VERSION "BO_HSCAN"

NS_ :

BS_:

BU_: BCM_Gp CCF_Server DDM DRDM DSM FTCM FTCMB GWM LPDM PDM PRDM PSM RFA RGTM RGTMB RLSM RPDM RRSM TBM TSTR VIM Virtual_Node WDCM Vector_XXX

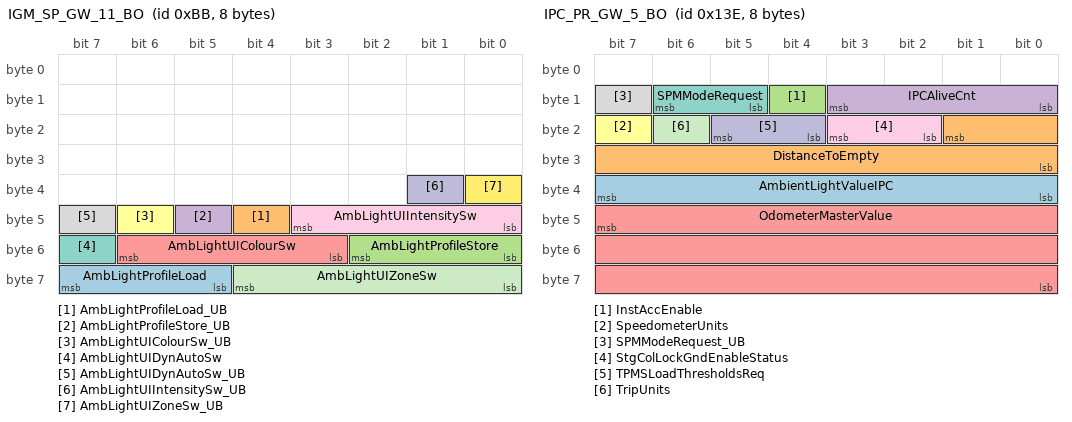
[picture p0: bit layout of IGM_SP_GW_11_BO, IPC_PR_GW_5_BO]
BO_ 187 IGM_SP_GW_11_BO: 8 GWM
 SG_ AmbLightProfileLoad : 63|3@0+ (1,0) [0|7] ""  BCM_Gp
 SG_ AmbLightProfileLoad_UB : 44|1@0+ (1,0) [0|1] ""  BCM_Gp
 SG_ AmbLightProfileStore : 50|3@0+ (1,0) [0|7] ""  BCM_Gp
 SG_ AmbLightProfileStore_UB : 45|1@0+ (1,0) [0|1] ""  BCM_Gp
 SG_ AmbLightUIColourSw : 54|4@0+ (1,0) [0|15] ""  BCM_Gp
 SG_ AmbLightUIColourSw_UB : 46|1@0+ (1,0) [0|1] ""  BCM_Gp
 SG_ AmbLightUIDynAutoSw : 55|1@0+ (1,0) [0|1] ""  BCM_Gp
 SG_ AmbLightUIDynAutoSw_UB : 47|1@0+ (1,0) [0|1] ""  BCM_Gp
 SG_ AmbLightUIIntensitySw : 43|4@0+ (1,0) [0|15] "Brightness level"  BCM_Gp
 SG_ AmbLightUIIntensitySw_UB : 33|1@0+ (1,0) [0|1] ""  BCM_Gp
 SG_ AmbLightUIZoneSw : 60|5@0+ (1,0) [0|31] ""  BCM_Gp
 SG_ AmbLightUIZoneSw_UB : 32|1@0+ (1,0) [0|1] ""  BCM_Gp

BO_ 177 IGM_SP_GW_1_BO: 8 GWM
 SG_ ActivateTimer : 47|1@0+ (1,0) [0|1] ""  BCM_Gp
 SG_ ActivateTimer_UB : 56|1@0+ (1,0) [0|1] ""  BCM_Gp
 SG_ AutoBlindEnableReq : 38|1@0+ (1,0) [0|1] ""  BCM_Gp
 SG_ AutoBlindEnableReq_UB : 63|1@0+ (1,0) [0|1] ""  BCM_Gp
 SG_ DIAnimationEnableReq : 35|1@0+ (1,0) [0|1] ""  BCM_Gp
 SG_ DIAnimationEnableReq_UB : 41|1@0+ (1,0) [0|1] ""  BCM_Gp
 SG_ EEEStateRequest : 24|1@0+ (1,0) [0|1] ""  BCM_Gp
 SG_ EEEStateRequest_UB : 62|1@0+ (1,0) [0|1] ""  BCM_Gp
 SG_ EnableDippedMirror : 27|1@0+ (1,0) [0|1] ""  BCM_Gp
 SG_ EnableDippedMirror_UB : 61|1@0+ (1,0) [0|1] ""  BCM_Gp
 SG_ GestureBlindEnableSw : 37|1@0+ (1,0) [0|1] ""  BCM_Gp
 SG_ GestureBlindEnableSw_UB : 48|1@0+ (1,0) [0|1] ""  BCM_Gp
 SG_ RearCameraWashReq : 36|1@0+ (1,0) [0|1] ""  BCM_Gp
 SG_ RearCameraWashReq_UB : 49|1@0+ (1,0) [0|1] ""  BCM_Gp
 SG_ SideStepsModeReq : 26|2@0+ (1,0) [0|3] ""  TBM
 SG_ SideStepsModeReq_UB : 50|1@0+ (1,0) [0|1] ""  TBM
 SG_ SinglePointEntryReq : 44|1@0+ (1,0) [0|1] ""  BCM_Gp
 SG_ SinglePointEntryReq_UB : 60|1@0+ (1,0) [0|1] ""  BCM_Gp
 SG_ StealthModeUISwitch : 46|2@0+ (1,0) [0|3] ""  BCM_Gp
 SG_ StealthModeUISwitch_UB : 51|1@0+ (1,0) [0|1] ""  BCM_Gp
 SG_ TowBarFunctionReq : 33|2@0+ (1,0) [0|3] ""  TBM
 SG_ TowBarFunctionReq_UB : 52|1@0+ (1,0) [0|1] ""  TBM
 SG_ TowBarMeasureLoad : 34|1@0+ (1,0) [0|1] ""  TBM
 SG_ TowBarMeasureLoad_UB : 53|1@0+ (1,0) [0|1] ""  TBM
 SG_ TrailerLightTestReq : 30|1@0+ (1,0) [0|1] ""  BCM_Gp
 SG_ TrailerLightTestReq_UB : 54|1@0+ (1,0) [0|1] ""  BCM_Gp
 SG_ ValetReq : 29|1@0+ (1,0) [0|1] ""  BCM_Gp
 SG_ ValetReq_UB : 55|1@0+ (1,0) [0|1] ""  BCM_Gp
 SG_ WakeShutDownEnableReq : 28|1@0+ (1,0) [0|1] ""  BCM_Gp
 SG_ WakeShutDownEnableReq_UB : 40|1@0+ (1,0) [0|1] ""  BCM_Gp
 SG_ WalkAwayLockReq : 17|2@0+ (1,0) [0|3] ""  Vector_XXX
 SG_ WalkAwayLockReq_UB : 31|1@0+ (1,0) [0|1] ""  Vector_XXX
 SG_ WindowsGlobalCloseReq : 43|1@0+ (1,0) [0|1] ""  BCM_Gp
 SG_ WindowsGlobalCloseReq_UB : 59|1@0+ (1,0) [0|1] ""  BCM_Gp
 SG_ WindowsGlobalOpenReq : 42|1@0+ (1,0) [0|1] ""  BCM_Gp
 SG_ WindowsGlobalOpenReq_UB : 58|1@0+ (1,0) [0|1] ""  BCM_Gp
 SG_ WiperWinterParkReq : 39|1@0+ (1,0) [0|1] ""  BCM_Gp
 SG_ WiperWinterParkReq_UB : 57|1@0+ (1,0) [0|1] ""  BCM_Gp

BO_ 108 IgnitionAuthDataControl_BO: 8 BCM_Gp
 SG_ IgnitionAuthDataControl : 7|64@0+ (1,0) [0|1.84467440737096E+019] ""  GWM

BO_ 110 IgnitionAuthDataTarget_BO: 8 GWM
 SG_ IgnitionAuthDataTarget : 7|64@0+ (1,0) [0|1.84467440737096E+019] ""  BCM_Gp

BO_ 318 IPC_PR_GW_5_BO: 8 GWM
 SG_ AmbientLightValueIPC : 39|8@0+ (1,0) [0|253] "Counts"  BCM_Gp
 SG_ DistanceToEmpty : 17|10@0+ (1,0) [0|1022] "Range in km"  Vector_XXX
 SG_ InstAccEnable : 12|1@0+ (1,0) [0|1] ""  Vector_XXX
 SG_ IPCAliveCnt : 11|4@0+ (1,0) [0|15] "Counter"  Vector_XXX
 SG_ OdometerMasterValue : 47|24@0+ (1,0) [0|16777215] ""  BCM_Gp,FTCM
 SG_ SpeedometerUnits : 23|1@0+ (1,0) [0|1] ""  Vector_XXX
 SG_ SPMModeRequest : 14|2@0+ (1,0) [0|3] ""  Vector_XXX
 SG_ SPMModeRequest_UB : 15|1@0+ (1,0) [0|1] ""  Vector_XXX
 SG_ StgColLockGndEnableStatus : 19|2@0+ (1,0) [0|3] ""  BCM_Gp
 SG_ TPMSLoadThresholdsReq : 21|2@0+ (1,0) [0|3] ""  Vector_XXX
 SG_ TripUnits : 22|1@0+ (1,0) [0|1] ""  Vector_XXX

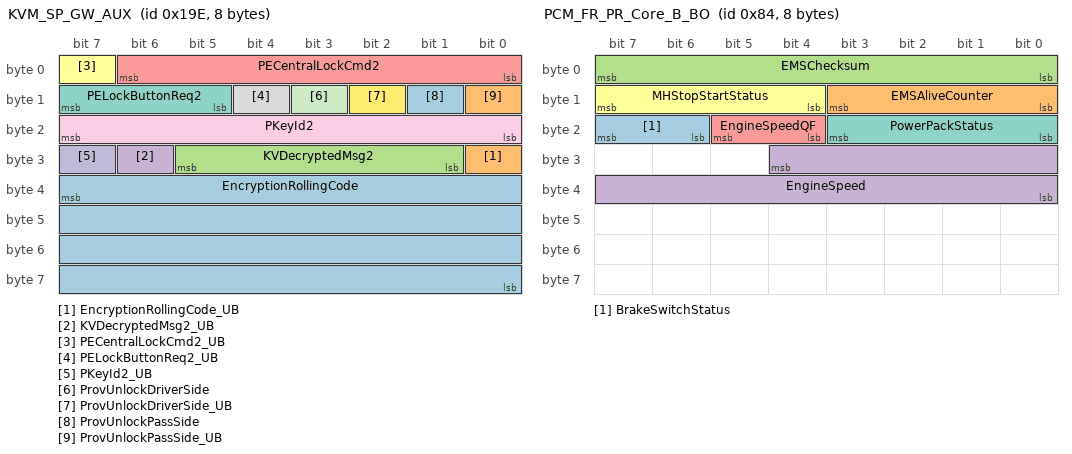
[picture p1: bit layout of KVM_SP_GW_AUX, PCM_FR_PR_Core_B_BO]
BO_ 414 KVM_SP_GW_AUX: 8 RFA
 SG_ EncryptionRollingCode : 39|32@0+ (1,0) [0|4294967295] ""  BCM_Gp,GWM
 SG_ EncryptionRollingCode_UB : 24|1@0+ (1,0) [0|1] ""  BCM_Gp,GWM
 SG_ KVDecryptedMsg2 : 29|5@0+ (1,0) [8|12] "Not Used"  BCM_Gp,GWM
 SG_ KVDecryptedMsg2_UB : 30|1@0+ (1,0) [0|1] ""  BCM_Gp,GWM
 SG_ PECentralLockCmd2 : 6|7@0+ (1,0) [0|127] "See description for encoding"  BCM_Gp,GWM,RGTM,RGTMB
 SG_ PECentralLockCmd2_UB : 7|1@0+ (1,0) [0|1] ""  BCM_Gp,GWM,RGTM,RGTMB
 SG_ PELockButtonReq2 : 15|3@0+ (1,0) [5|6] "Undefined (Unused)"  BCM_Gp,GWM
 SG_ PELockButtonReq2_UB : 12|1@0+ (1,0) [0|1] ""  BCM_Gp,GWM
 SG_ PKeyId2 : 23|8@0+ (1,0) [0|255] "See description for encoding"  BCM_Gp,GWM
 SG_ PKeyId2_UB : 31|1@0+ (1,0) [0|1] ""  BCM_Gp,GWM
 SG_ ProvUnlockDriverSide : 11|1@0+ (1,0) [0|1] ""  BCM_Gp,GWM
 SG_ ProvUnlockDriverSide_UB : 10|1@0+ (1,0) [0|1] ""  BCM_Gp,GWM
 SG_ ProvUnlockPassSide : 9|1@0+ (1,0) [0|1] ""  BCM_Gp,GWM
 SG_ ProvUnlockPassSide_UB : 8|1@0+ (1,0) [0|1] ""  BCM_Gp,GWM

BO_ 1386 LPDM_NM56A: 8 LPDM
 SG_ NMMessageLPDM : 7|64@0+ (1,0) [0|1.84467440737096E+019] ""  Virtual_Node

BO_ 944 LPDM_PR_GW_1: 8 LPDM
 SG_ LeftPowerDoorStatus : 59|4@0+ (1,0) [0|15] ""  GWM

BO_ 124 PATSDataControl_BO: 8 BCM_Gp
 SG_ PATSDataControl : 7|64@0+ (1,0) [0|1.84467440737096E+019] ""  GWM

BO_ 126 PATSDataTarget_BO: 8 GWM
 SG_ PATSDataTarget : 7|64@0+ (1,0) [0|1.84467440737096E+019] ""  BCM_Gp

BO_ 132 PCM_FR_PR_Core_B_BO: 8 GWM
 SG_ BrakeSwitchStatus : 23|2@0+ (1,0) [0|3] ""  BCM_Gp
 SG_ EMSAliveCounter : 11|4@0+ (1,0) [0|15] "Counter"  Vector_XXX
 SG_ EMSChecksum : 7|8@0+ (1,0) [0|255] "Counter"  Vector_XXX
 SG_ EngineSpeed : 28|13@0+ (1,0) [0|8191] "RPM"  BCM_Gp
 SG_ EngineSpeedQF : 21|2@0+ (1,0) [0|3] ""  Vector_XXX
 SG_ MHStopStartStatus : 15|4@0+ (1,0) [0|15] ""  FTCM
 SG_ PowerPackStatus : 19|4@0+ (1,0) [0|15] ""  BCM_Gp,FTCM

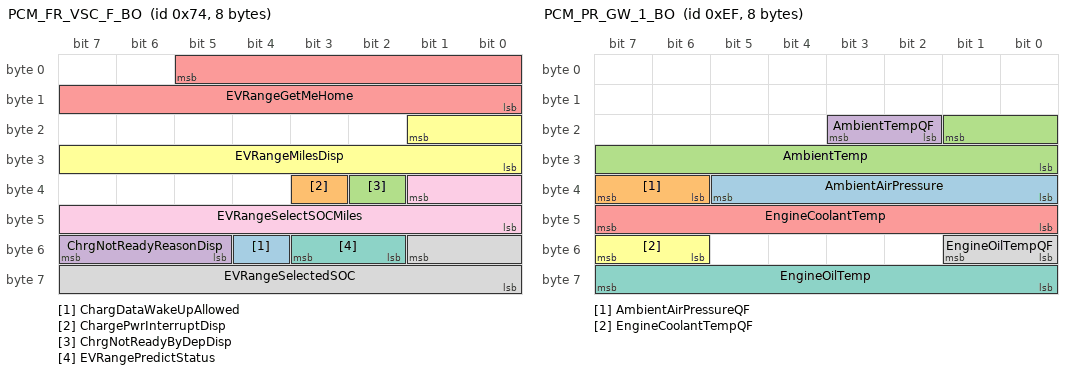
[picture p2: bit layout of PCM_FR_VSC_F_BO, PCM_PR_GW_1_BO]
BO_ 116 PCM_FR_VSC_F_BO: 8 GWM
 SG_ ChargDataWakeUpAllowed : 52|1@0+ (1,0) [0|1] ""  Vector_XXX
 SG_ ChargePwrInterruptDisp : 35|1@0+ (1,0) [0|1] ""  Vector_XXX
 SG_ ChrgNotReadyByDepDisp : 34|1@0+ (1,0) [0|1] ""  Vector_XXX
 SG_ ChrgNotReadyReasonDisp : 55|3@0+ (1,0) [0|7] ""  Vector_XXX
 SG_ EVRangeGetMeHome : 5|14@0+ (0.1,0) [0|1638.3] "km"  WDCM
 SG_ EVRangeMilesDisp : 17|10@0+ (1,0) [0|1023] "Miles"  Vector_XXX
 SG_ EVRangePredictStatus : 51|2@0+ (1,0) [0|3] ""  Vector_XXX
 SG_ EVRangeSelectedSOC : 49|10@0+ (1,0) [0|1023] "km"  Vector_XXX
 SG_ EVRangeSelectSOCMiles : 33|10@0+ (1,0) [0|1023] "Miles"  Vector_XXX

BO_ 239 PCM_PR_GW_1_BO: 8 GWM
 SG_ AmbientAirPressure : 37|6@0+ (10,500) [500|1100] "mBAR"  BCM_Gp,DSM,PSM,RLSM,RRSM
 SG_ AmbientAirPressureQF : 39|2@0+ (1,0) [0|3] ""  BCM_Gp
 SG_ AmbientTemp : 17|10@0+ (0.25,-128) [-128|127.75] "Degrees C"  BCM_Gp,DDM,DRDM,FTCM,PDM,PRDM,RGTM,RGTMB
 SG_ AmbientTempQF : 19|2@0+ (1,0) [0|3] ""  BCM_Gp,DDM,DRDM,FTCM,PDM,PRDM,RGTM,RGTMB
 SG_ EngineCoolantTemp : 47|8@0+ (1,-60) [-60|195] "deg C"  Vector_XXX
 SG_ EngineCoolantTempQF : 55|2@0+ (1,0) [0|3] ""  Vector_XXX
 SG_ EngineOilTemp : 63|8@0+ (1,-60) [-60|195] "deg C"  Vector_XXX
 SG_ EngineOilTempQF : 49|2@0+ (1,0) [0|3] ""  Vector_XXX

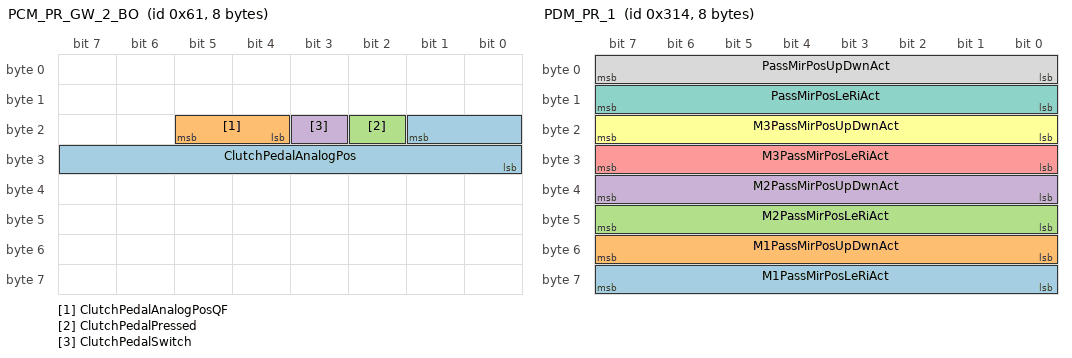
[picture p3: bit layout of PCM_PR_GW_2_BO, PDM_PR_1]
BO_ 97 PCM_PR_GW_2_BO: 8 GWM
 SG_ ClutchPedalAnalogPos : 17|10@0+ (0.0977517,0) [0|99.9999891] "%, range: 0-100%"  BCM_Gp
 SG_ ClutchPedalAnalogPosQF : 21|2@0+ (1,0) [0|3] ""  Vector_XXX
 SG_ ClutchPedalPressed : 18|1@0+ (1,0) [0|1] ""  BCM_Gp
 SG_ ClutchPedalSwitch : 19|1@0+ (1,0) [0|1] ""  Vector_XXX

BO_ 788 PDM_PR_1: 8 PDM
 SG_ M1PassMirPosLeRiAct : 63|8@0+ (1,0) [0|255] "Mirror Position"  Virtual_Node
 SG_ M1PassMirPosUpDwnAct : 55|8@0+ (1,0) [0|255] "Mirror Position"  Virtual_Node
 SG_ M2PassMirPosLeRiAct : 47|8@0+ (1,0) [0|255] "Mirror Position"  Virtual_Node
 SG_ M2PassMirPosUpDwnAct : 39|8@0+ (1,0) [0|255] "Mirror Position"  Virtual_Node
 SG_ M3PassMirPosLeRiAct : 31|8@0+ (1,0) [0|255] "Mirror Position"  Virtual_Node
 SG_ M3PassMirPosUpDwnAct : 23|8@0+ (1,0) [0|255] "Mirror Position"  Virtual_Node
 SG_ PassMirPosLeRiAct : 15|8@0+ (1,0) [0|255] "Mirror Position"  Virtual_Node
 SG_ PassMirPosUpDwnAct : 7|8@0+ (1,0) [0|255] "Mirror Position"  Virtual_Node

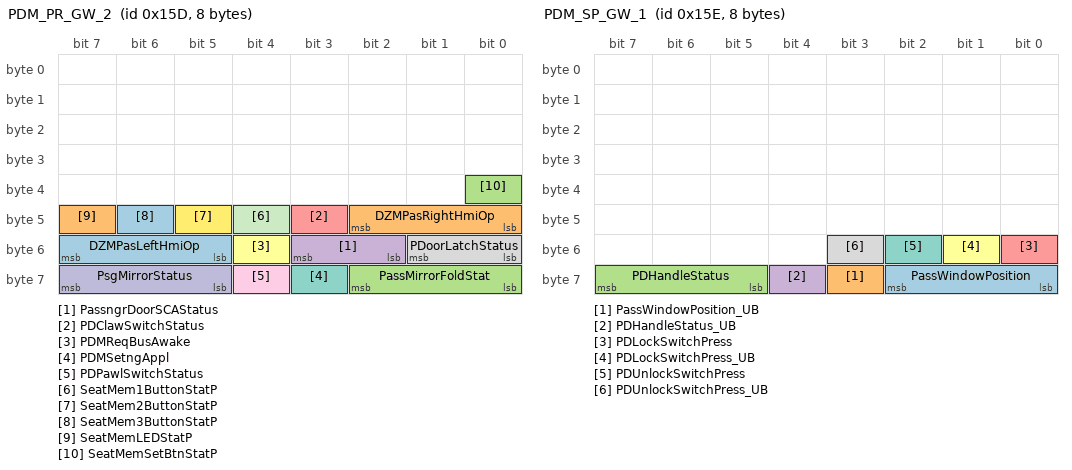
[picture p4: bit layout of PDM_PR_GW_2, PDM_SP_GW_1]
BO_ 349 PDM_PR_GW_2: 8 PDM
 SG_ DZMPasLeftHmiOp : 55|3@0+ (1,0) [5|7] "Not Used"  GWM
 SG_ DZMPasRightHmiOp : 42|3@0+ (1,0) [5|7] "Not Used"  GWM
 SG_ PassMirrorFoldStat : 58|3@0+ (1,0) [0|7] ""  DDM
 SG_ PassngrDoorSCAStatus : 51|2@0+ (1,0) [0|3] ""  DDM
 SG_ PDClawSwitchStatus : 43|1@0+ (1,0) [0|1] ""  DDM
 SG_ PDMReqBusAwake : 52|1@0+ (1,0) [0|1] ""  GWM
 SG_ PDMSetngAppl : 59|1@0+ (1,0) [0|1] ""  Virtual_Node
 SG_ PDoorLatchStatus : 49|2@0+ (1,0) [0|3] "See Description"  BCM_Gp,LPDM,RPDM,TBM
 SG_ PDPawlSwitchStatus : 60|1@0+ (1,0) [0|1] ""  DDM
 SG_ PsgMirrorStatus : 63|3@0+ (1,0) [0|7] ""  GWM
 SG_ SeatMem1ButtonStatP : 44|1@0+ (1,0) [0|1] ""  PSM
 SG_ SeatMem2ButtonStatP : 45|1@0+ (1,0) [0|1] ""  PSM
 SG_ SeatMem3ButtonStatP : 46|1@0+ (1,0) [0|1] ""  PSM
 SG_ SeatMemLEDStatP : 47|1@0+ (1,0) [0|1] ""  PSM
 SG_ SeatMemSetBtnStatP : 32|1@0+ (1,0) [0|1] ""  PSM

BO_ 350 PDM_SP_GW_1: 8 PDM
 SG_ PassWindowPosition : 58|3@0+ (1,0) [6|7] "Undefined (Unused)"  BCM_Gp,FTCM,GWM,LPDM,RPDM
 SG_ PassWindowPosition_UB : 59|1@0+ (1,0) [0|1] ""  BCM_Gp,FTCM,GWM,LPDM,RPDM
 SG_ PDHandleStatus : 63|3@0+ (1,0) [0|7] ""  GWM,RFA
 SG_ PDHandleStatus_UB : 60|1@0+ (1,0) [0|1] ""  GWM,RFA
 SG_ PDLockSwitchPress : 48|1@0+ (1,0) [0|1] ""  BCM_Gp,GWM
 SG_ PDLockSwitchPress_UB : 49|1@0+ (1,0) [0|1] ""  BCM_Gp,GWM
 SG_ PDUnlockSwitchPress : 50|1@0+ (1,0) [0|1] ""  BCM_Gp,GWM
 SG_ PDUnlockSwitchPress_UB : 51|1@0+ (1,0) [0|1] ""  BCM_Gp,GWM

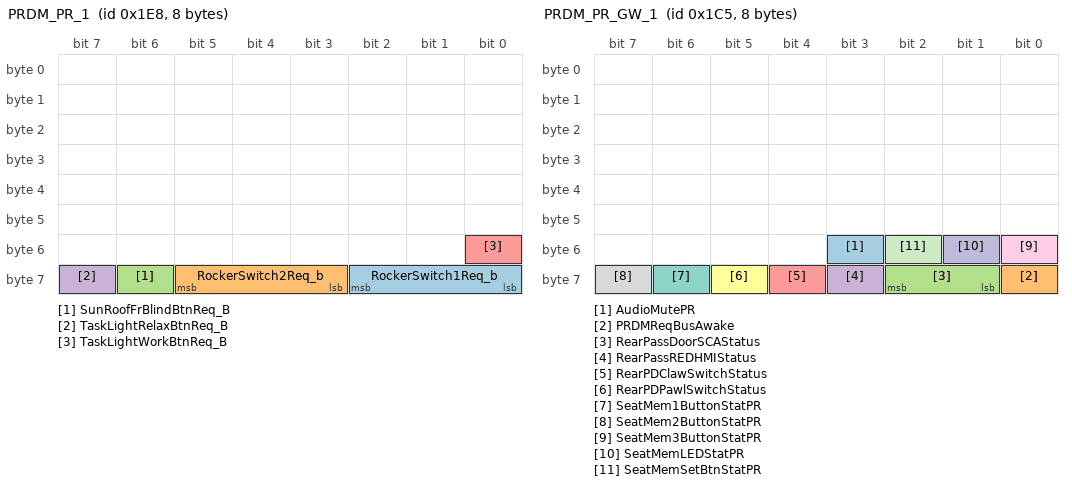
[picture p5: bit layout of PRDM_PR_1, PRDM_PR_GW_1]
BO_ 488 PRDM_PR_1: 8 PRDM
 SG_ RockerSwitch1Req_b : 58|3@0+ (1,0) [5|7] "Not used"  DRDM
 SG_ RockerSwitch2Req_b : 61|3@0+ (1,0) [5|7] "Not used"  DRDM
 SG_ SunRoofFrBlindBtnReq_B : 62|1@0+ (1,0) [0|1] ""  BCM_Gp
 SG_ TaskLightRelaxBtnReq_B : 63|1@0+ (1,0) [0|1] ""  BCM_Gp
 SG_ TaskLightWorkBtnReq_B : 48|1@0+ (1,0) [0|1] ""  BCM_Gp

BO_ 453 PRDM_PR_GW_1: 8 PRDM
 SG_ AudioMutePR : 51|1@0+ (1,0) [0|1] ""  GWM
 SG_ PRDMReqBusAwake : 56|1@0+ (1,0) [0|1] ""  GWM
 SG_ RearPassDoorSCAStatus : 58|2@0+ (1,0) [0|3] ""  DRDM
 SG_ RearPassREDHMIStatus : 59|1@0+ (1,0) [0|1] ""  GWM
 SG_ RearPDClawSwitchStatus : 60|1@0+ (1,0) [0|1] ""  DRDM
 SG_ RearPDPawlSwitchStatus : 61|1@0+ (1,0) [0|1] ""  DRDM
 SG_ SeatMem1ButtonStatPR : 62|1@0+ (1,0) [0|1] ""  PSM
 SG_ SeatMem2ButtonStatPR : 63|1@0+ (1,0) [0|1] ""  PSM
 SG_ SeatMem3ButtonStatPR : 48|1@0+ (1,0) [0|1] ""  PSM
 SG_ SeatMemLEDStatPR : 49|1@0+ (1,0) [0|1] ""  PSM
 SG_ SeatMemSetBtnStatPR : 50|1@0+ (1,0) [0|1] ""  PSM

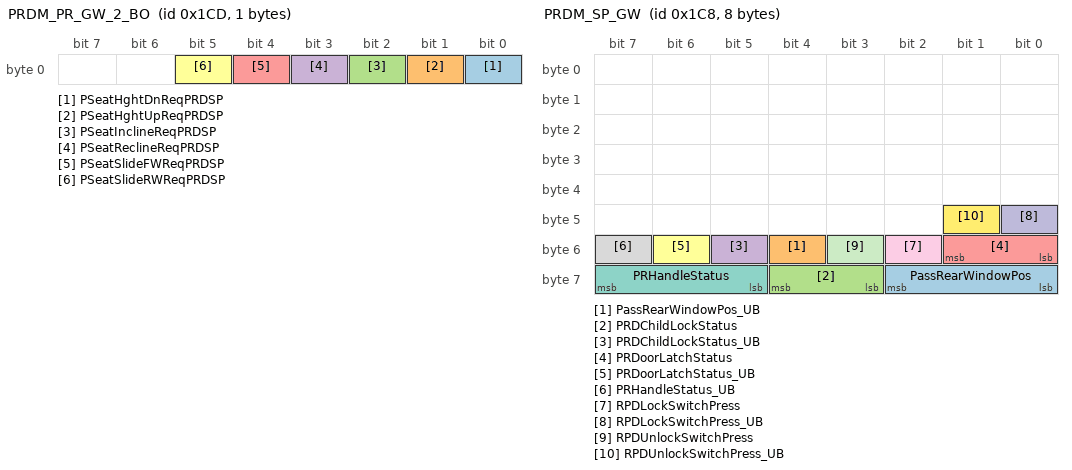
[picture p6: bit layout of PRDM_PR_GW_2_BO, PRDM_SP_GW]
BO_ 461 PRDM_PR_GW_2_BO: 1 PRDM
 SG_ PSeatHghtDnReqPRDSP : 0|1@0+ (1,0) [0|1] ""  PSM
 SG_ PSeatHghtUpReqPRDSP : 1|1@0+ (1,0) [0|1] ""  PSM
 SG_ PSeatInclineReqPRDSP : 2|1@0+ (1,0) [0|1] ""  PSM
 SG_ PSeatReclineReqPRDSP : 3|1@0+ (1,0) [0|1] ""  PSM
 SG_ PSeatSlideFWReqPRDSP : 4|1@0+ (1,0) [0|1] ""  PSM
 SG_ PSeatSlideRWReqPRDSP : 5|1@0+ (1,0) [0|1] ""  PSM

BO_ 456 PRDM_SP_GW: 8 PRDM
 SG_ PassRearWindowPos : 58|3@0+ (1,0) [6|7] "Undefined (Unused)"  BCM_Gp,FTCM,GWM
 SG_ PassRearWindowPos_UB : 52|1@0+ (1,0) [0|1] ""  BCM_Gp,FTCM,GWM
 SG_ PRDChildLockStatus : 60|2@0+ (1,0) [0|3] ""  DDM,GWM
 SG_ PRDChildLockStatus_UB : 53|1@0+ (1,0) [0|1] ""  DDM,GWM
 SG_ PRDoorLatchStatus : 49|2@0+ (1,0) [0|3] "See Description"  BCM_Gp,GWM
 SG_ PRDoorLatchStatus_UB : 54|1@0+ (1,0) [0|1] ""  BCM_Gp,GWM
 SG_ PRHandleStatus : 63|3@0+ (1,0) [0|7] ""  GWM,RFA
 SG_ PRHandleStatus_UB : 55|1@0+ (1,0) [0|1] ""  GWM,RFA
 SG_ RPDLockSwitchPress : 50|1@0+ (1,0) [0|1] ""  BCM_Gp,GWM
 SG_ RPDLockSwitchPress_UB : 40|1@0+ (1,0) [0|1] ""  BCM_Gp,GWM
 SG_ RPDUnlockSwitchPress : 51|1@0+ (1,0) [0|1] ""  BCM_Gp,GWM
 SG_ RPDUnlockSwitchPress_UB : 41|1@0+ (1,0) [0|1] ""  BCM_Gp,GWM

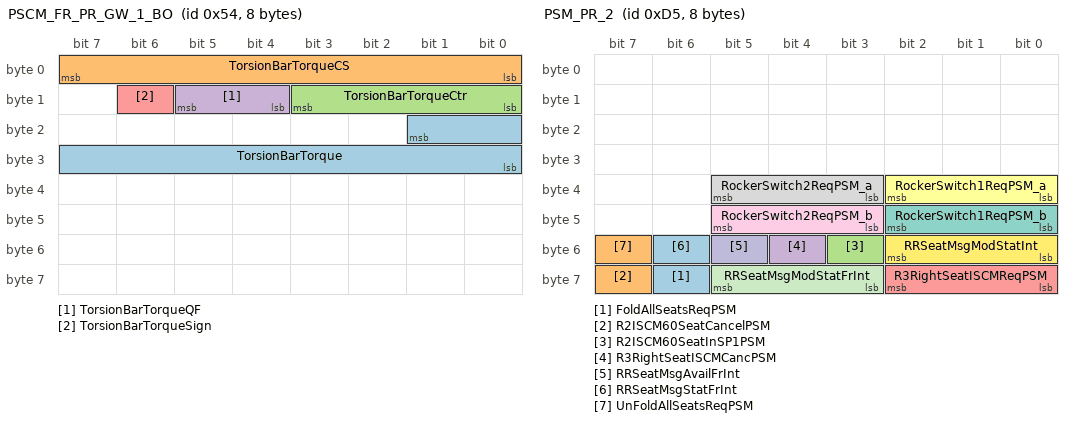
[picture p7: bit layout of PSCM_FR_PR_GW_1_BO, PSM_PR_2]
BO_ 84 PSCM_FR_PR_GW_1_BO: 8 GWM
 SG_ TorsionBarTorque : 17|10@0+ (0.02,0) [0|20.44] "0-3FCh :0..+20.40 Nm, E=N*0.02+0"  Vector_XXX
 SG_ TorsionBarTorqueCS : 7|8@0+ (1,0) [0|255] "checksum"  Vector_XXX
 SG_ TorsionBarTorqueCtr : 11|4@0+ (1,0) [0|15] "Counter value"  Vector_XXX
 SG_ TorsionBarTorqueQF : 13|2@0+ (1,0) [0|3] ""  Vector_XXX
 SG_ TorsionBarTorqueSign : 14|1@0+ (1,0) [0|1] ""  BCM_Gp

BO_ 211 PSM_BO_PR_GW_1: 8 PSM
 SG_ PasSeatInhib1stRow : 26|1@0+ (1,0) [0|1] ""  GWM
 SG_ PasSeatInhib2ndRow : 27|1@0+ (1,0) [0|1] ""  GWM
 SG_ PasSeatInhib3rdRow : 28|1@0+ (1,0) [0|1] ""  GWM
 SG_ PasSeatPosition1stRow : 59|4@0+ (1,0) [5|15] "Reserved"  GWM
 SG_ PasSeatPosition2ndRow : 63|4@0+ (1,0) [5|15] "Reserved"  GWM
 SG_ PasSeatPosition3rdRow : 51|4@0+ (1,0) [5|15] "Reserved"  GWM
 SG_ PassengerCancelSeat : 29|1@0+ (1,0) [0|1] ""  GWM,RLSM,RRSM
 SG_ PassengerSeatMovement : 30|1@0+ (1,0) [0|1] ""  GWM,RLSM,RRSM
 SG_ PassSeatFootRestStat : 31|1@0+ (1,0) [0|1] ""  GWM,RLSM,RRSM
 SG_ PassSeatMemLoadStat : 34|3@0+ (1,0) [0|7] ""  GWM,RLSM,RRSM
 SG_ PassSeatMemStorStat : 37|3@0+ (1,0) [0|7] ""  GWM,RLSM,RRSM
 SG_ PassSeatMovement2ndRow : 39|2@0+ (1,0) [0|3] ""  GWM
 SG_ PassSeatMovement3rdRow : 25|2@0+ (1,0) [0|3] ""  GWM
 SG_ PassSeatMovementStat : 55|4@0+ (1,0) [0|15] ""  GWM,RLSM,RRSM
 SG_ PassSeatMoveSelStat : 16|1@0+ (1,0) [0|1] ""  GWM
 SG_ PassSeatMovmnt2ndRow : 43|4@0+ (1,0) [5|15] "Reserved"  DSM,GWM
 SG_ PassSeatMovmnt3rdRow : 47|4@0+ (1,0) [5|15] "Reserved"  DSM,GWM
 SG_ PassSeatOccupantStatus : 22|1@0+ (1,0) [0|1] ""  GWM,RLSM,RRSM
 SG_ PassSeatPSAStat : 17|1@0+ (1,0) [0|1] ""  GWM,RLSM,RRSM
 SG_ Row1PassMovementINH : 18|1@0+ (1,0) [0|1] ""  GWM
 SG_ Row2PassMovementINH : 19|1@0+ (1,0) [0|1] ""  GWM
 SG_ Row3PassMovementINH : 20|1@0+ (1,0) [0|1] ""  GWM
 SG_ RPSeatMovement : 21|1@0+ (1,0) [0|1] ""  GWM

BO_ 1368 PSM_NM558: 8 PSM
 SG_ NMmessagePSM : 7|64@0+ (1,0) [0|1.84467440737096E+019] ""  Virtual_Node

BO_ 213 PSM_PR_2: 8 PSM
 SG_ FoldAllSeatsReqPSM : 62|1@0+ (1,0) [0|1] ""  DSM
 SG_ R2ISCM60SeatCancelPSM : 63|1@0+ (1,0) [0|1] ""  DSM
 SG_ R2ISCM60SeatInSP1PSM : 51|1@0+ (1,0) [0|1] ""  DSM
 SG_ R3RightSeatISCMCancPSM : 52|1@0+ (1,0) [0|1] ""  DSM
 SG_ R3RightSeatISCMReqPSM : 58|3@0+ (1,0) [0|7] ""  DSM
 SG_ RockerSwitch1ReqPSM_a : 34|3@0+ (1,0) [5|7] "Not used"  DSM
 SG_ RockerSwitch1ReqPSM_b : 42|3@0+ (1,0) [5|7] "Not used"  DSM
 SG_ RockerSwitch2ReqPSM_a : 37|3@0+ (1,0) [5|7] "Not used"  DSM
 SG_ RockerSwitch2ReqPSM_b : 45|3@0+ (1,0) [5|7] "Not used"  DSM
 SG_ RRSeatMsgAvailFrInt : 53|1@0+ (1,0) [0|1] ""  DSM
 SG_ RRSeatMsgModStatFrInt : 61|3@0+ (1,0) [5|7] "Unused"  DSM
 SG_ RRSeatMsgModStatInt : 50|3@0+ (1,0) [5|7] "Unused"  DSM
 SG_ RRSeatMsgStatFrInt : 54|1@0+ (1,0) [0|1] ""  DSM
 SG_ UnFoldAllSeatsReqPSM : 55|1@0+ (1,0) [0|1] ""  DSM

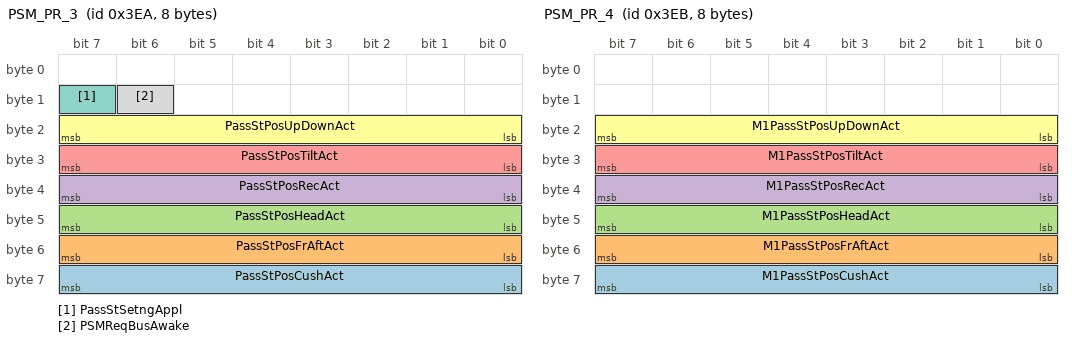
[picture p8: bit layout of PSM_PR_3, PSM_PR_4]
BO_ 1002 PSM_PR_3: 8 PSM
 SG_ PassStPosCushAct : 63|8@0+ (0.5,0) [0|100] "%"  Virtual_Node
 SG_ PassStPosFrAftAct : 55|8@0+ (0.5,0) [0|100] "%"  Virtual_Node
 SG_ PassStPosHeadAct : 47|8@0+ (0.5,0) [0|100] "%"  Virtual_Node
 SG_ PassStPosRecAct : 39|8@0+ (0.5,0) [0|100] "%"  Virtual_Node
 SG_ PassStPosTiltAct : 31|8@0+ (0.5,0) [0|100] "%"  Virtual_Node
 SG_ PassStPosUpDownAct : 23|8@0+ (0.5,0) [0|100] "%"  Virtual_Node
 SG_ PassStSetngAppl : 15|1@0+ (1,0) [0|1] ""  Virtual_Node
 SG_ PSMReqBusAwake : 14|1@0+ (1,0) [0|1] ""  GWM

BO_ 1003 PSM_PR_4: 8 PSM
 SG_ M1PassStPosCushAct : 63|8@0+ (0.5,0) [0|100] "%"  Virtual_Node
 SG_ M1PassStPosFrAftAct : 55|8@0+ (0.5,0) [0|100] "%"  Virtual_Node
 SG_ M1PassStPosHeadAct : 47|8@0+ (0.5,0) [0|100] "%"  Virtual_Node
 SG_ M1PassStPosRecAct : 39|8@0+ (0.5,0) [0|100] "%"  Virtual_Node
 SG_ M1PassStPosTiltAct : 31|8@0+ (0.5,0) [0|100] "%"  Virtual_Node
 SG_ M1PassStPosUpDownAct : 23|8@0+ (0.5,0) [0|100] "%"  Virtual_Node

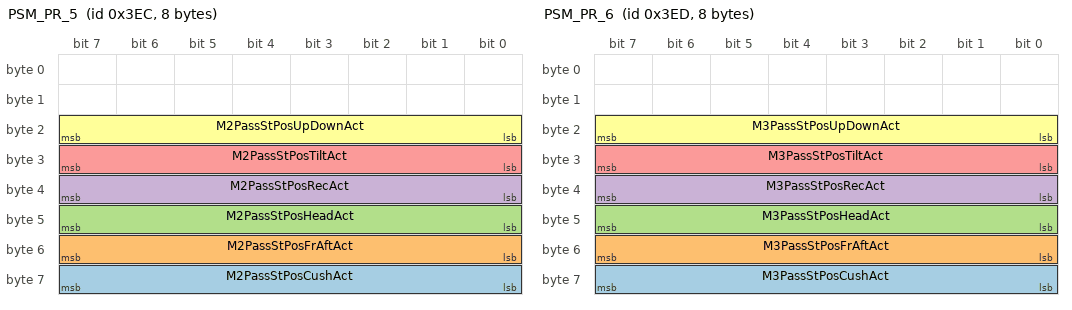
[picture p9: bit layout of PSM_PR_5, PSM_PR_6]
BO_ 1004 PSM_PR_5: 8 PSM
 SG_ M2PassStPosCushAct : 63|8@0+ (0.5,0) [0|100] "%"  Virtual_Node
 SG_ M2PassStPosFrAftAct : 55|8@0+ (0.5,0) [0|100] "%"  Virtual_Node
 SG_ M2PassStPosHeadAct : 47|8@0+ (0.5,0) [0|100] "%"  Virtual_Node
 SG_ M2PassStPosRecAct : 39|8@0+ (0.5,0) [0|100] "%"  Virtual_Node
 SG_ M2PassStPosTiltAct : 31|8@0+ (0.5,0) [0|100] "%"  Virtual_Node
 SG_ M2PassStPosUpDownAct : 23|8@0+ (0.5,0) [0|100] "%"  Virtual_Node

BO_ 1005 PSM_PR_6: 8 PSM
 SG_ M3PassStPosCushAct : 63|8@0+ (0.5,0) [0|100] "%"  Virtual_Node
 SG_ M3PassStPosFrAftAct : 55|8@0+ (0.5,0) [0|100] "%"  Virtual_Node
 SG_ M3PassStPosHeadAct : 47|8@0+ (0.5,0) [0|100] "%"  Virtual_Node
 SG_ M3PassStPosRecAct : 39|8@0+ (0.5,0) [0|100] "%"  Virtual_Node
 SG_ M3PassStPosTiltAct : 31|8@0+ (0.5,0) [0|100] "%"  Virtual_Node
 SG_ M3PassStPosUpDownAct : 23|8@0+ (0.5,0) [0|100] "%"  Virtual_Node

BO_ 191 RCM_FR_PR_GW_1_BO: 8 GWM
 SG_ CrashAirbagStatus : 63|2@0+ (1,0) [0|3] ""  Vector_XXX
 SG_ CrashOccClassStatus : 61|2@0+ (1,0) [0|3] ""  Vector_XXX
 SG_ CrashPACOSSwitchState : 59|2@0+ (1,0) [0|3] ""  Vector_XXX
 SG_ CrashPretensionerStat : 57|2@0+ (1,0) [0|3] ""  Vector_XXX
 SG_ CrashSeatBeltBcklState : 55|2@0+ (1,0) [0|3] ""  Vector_XXX
 SG_ CrashSeverityClass : 53|2@0+ (1,0) [0|3] ""  Vector_XXX
 SG_ CrashSideAirbagStatus : 51|2@0+ (1,0) [0|3] ""  Vector_XXX
 SG_ CrashStatusPIE : 42|1@0+ (1,0) [0|1] ""  BCM_Gp
 SG_ CrashStatusRCM : 43|1@0+ (1,0) [0|1] ""  BCM_Gp,DDM,DRDM,PDM,PRDM
 SG_ CrashTypeFront : 49|1@0+ (1,0) [0|1] ""  Vector_XXX
 SG_ CrashTypeRear : 48|1@0+ (1,0) [0|1] ""  Vector_XXX
 SG_ CrashTypeRoll : 40|1@0+ (1,0) [0|1] ""  Vector_XXX
 SG_ CrashTypeSide : 41|1@0+ (1,0) [0|1] ""  Vector_XXX
 SG_ DrivSeatBeltBcklError : 30|1@0+ (1,0) [0|1] ""  BCM_Gp,LPDM,RPDM
 SG_ DrivSeatBeltBcklState : 31|1@0+ (1,0) [0|1] ""  BCM_Gp,DSM,LPDM,RPDM
 SG_ DrivSeatPositionError : 47|1@0+ (1,0) [0|1] ""  Vector_XXX
 SG_ DrivSeatPositionStatus : 46|1@0+ (1,0) [0|1] ""  LPDM,RPDM
 SG_ KeepNetInAfterRunRCM : 44|1@0+ (1,0) [0|1] ""  Vector_XXX
 SG_ PassSeatBeltBcklError : 28|1@0+ (1,0) [0|1] ""  LPDM,RPDM
 SG_ PassSeatBeltBcklState : 29|1@0+ (1,0) [0|1] ""  LPDM,PSM,RPDM
 SG_ PassSeatPositionStatus : 45|1@0+ (1,0) [0|1] ""  LPDM,RPDM
 SG_ VerticalAcceleration : 27|12@0+ (0.02,-40.96) [-40.96|40.92] "m/s/s"  Vector_XXX

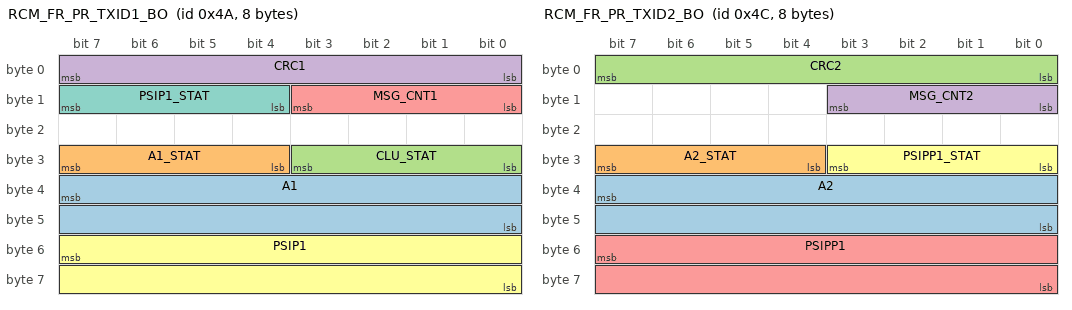
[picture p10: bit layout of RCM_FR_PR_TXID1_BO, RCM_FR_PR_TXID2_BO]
BO_ 74 RCM_FR_PR_TXID1_BO: 8 GWM
 SG_ A1 : 39|16@0+ (0.00125,-40.96) [-40.96|40.9575] "m/s2"  LPDM,RPDM
 SG_ A1_STAT : 31|4@0+ (1,0) [0|15] ""  Vector_XXX
 SG_ CLU_STAT : 27|4@0+ (1,0) [0|15] ""  Vector_XXX
 SG_ CRC1 : 7|8@0+ (1,0) [0|255] "checksum"  Vector_XXX
 SG_ MSG_CNT1 : 11|4@0+ (1,0) [0|15] "Counter value"  Vector_XXX
 SG_ PSIP1 : 55|16@0+ (0.005,-163.84) [-163.84|163.83] "Grad/s"  BCM_Gp
 SG_ PSIP1_STAT : 15|4@0+ (1,0) [0|15] ""  BCM_Gp

BO_ 76 RCM_FR_PR_TXID2_BO: 8 GWM
 SG_ A2 : 39|16@0+ (0.00125,-40.96) [-40.96|40.9575] "m/s2"  LPDM,RPDM,TBM
 SG_ A2_STAT : 31|4@0+ (1,0) [0|15] ""  Vector_XXX
 SG_ CRC2 : 7|8@0+ (1,0) [0|255] "checksum"  Vector_XXX
 SG_ MSG_CNT2 : 11|4@0+ (1,0) [0|15] "Counter value"  Vector_XXX
 SG_ PSIPP1 : 55|16@0+ (0.125,-4096) [-4096|4095.75] "Grad/s/s"  Vector_XXX
 SG_ PSIPP1_STAT : 27|4@0+ (1,0) [0|15] ""  Vector_XXX

BO_ 1288 RFA_NM508LS: 8 RFA
 SG_ NMmessageKVM : 7|64@0+ (1,0) [0|1.84467440737096E+019] ""  Virtual_Node

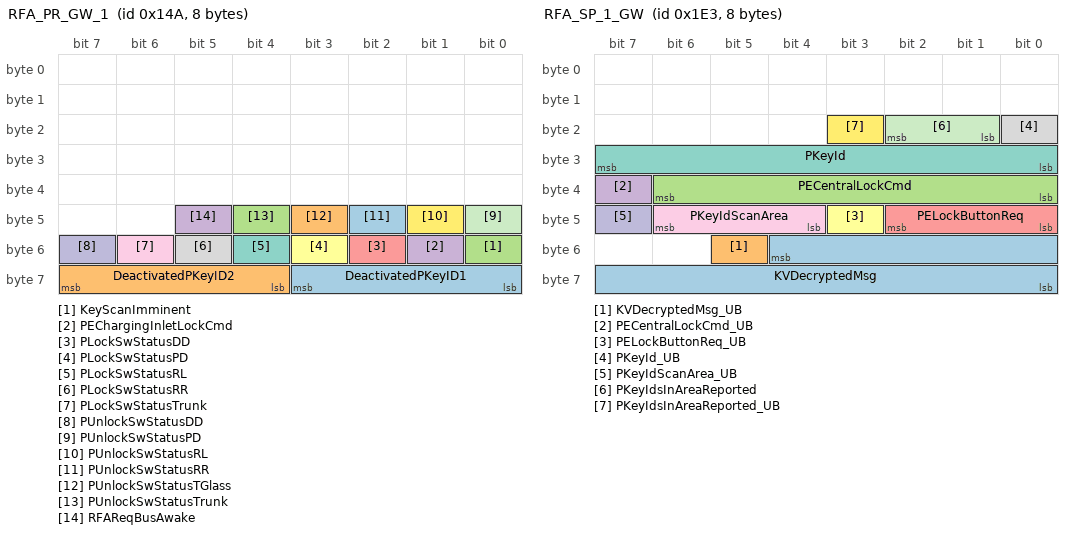
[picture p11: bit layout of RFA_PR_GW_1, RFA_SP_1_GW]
BO_ 330 RFA_PR_GW_1: 8 RFA
 SG_ DeactivatedPKeyID1 : 59|4@0+ (1,0) [0|15] "No Units"  BCM_Gp
 SG_ DeactivatedPKeyID2 : 63|4@0+ (1,0) [0|15] "No Units"  BCM_Gp
 SG_ KeyScanImminent : 48|1@0+ (1,0) [0|1] ""  WDCM
 SG_ PEChargingInletLockCmd : 49|1@0+ (1,0) [0|1] ""  GWM
 SG_ PLockSwStatusDD : 50|1@0+ (1,0) [0|1] ""  BCM_Gp
 SG_ PLockSwStatusPD : 51|1@0+ (1,0) [0|1] ""  BCM_Gp
 SG_ PLockSwStatusRL : 52|1@0+ (1,0) [0|1] ""  BCM_Gp
 SG_ PLockSwStatusRR : 53|1@0+ (1,0) [0|1] ""  BCM_Gp
 SG_ PLockSwStatusTrunk : 54|1@0+ (1,0) [0|1] ""  BCM_Gp
 SG_ PUnlockSwStatusDD : 55|1@0+ (1,0) [0|1] ""  BCM_Gp,DDM,DRDM,PDM,PRDM
 SG_ PUnlockSwStatusPD : 40|1@0+ (1,0) [0|1] ""  BCM_Gp,DDM,DRDM,PDM,PRDM
 SG_ PUnlockSwStatusRL : 41|1@0+ (1,0) [0|1] ""  BCM_Gp,DDM,DRDM,PDM,PRDM
 SG_ PUnlockSwStatusRR : 42|1@0+ (1,0) [0|1] ""  BCM_Gp,DDM,DRDM,PDM,PRDM
 SG_ PUnlockSwStatusTGlass : 43|1@0+ (1,0) [0|1] ""  BCM_Gp
 SG_ PUnlockSwStatusTrunk : 44|1@0+ (1,0) [0|1] ""  BCM_Gp
 SG_ RFAReqBusAwake : 45|1@0+ (1,0) [0|1] ""  GWM

BO_ 483 RFA_SP_1_GW: 8 RFA
 SG_ KVDecryptedMsg : 52|13@0+ (1,0) [0|8191] ""  BCM_Gp,GWM
 SG_ KVDecryptedMsg_UB : 53|1@0+ (1,0) [0|1] ""  BCM_Gp,GWM
 SG_ PECentralLockCmd : 38|7@0+ (1,0) [0|127] "See description for encoding"  BCM_Gp,GWM
 SG_ PECentralLockCmd_UB : 39|1@0+ (1,0) [0|1] ""  BCM_Gp,GWM
 SG_ PELockButtonReq : 42|3@0+ (1,0) [5|6] "Undefined (Unused)"  BCM_Gp,GWM
 SG_ PELockButtonReq_UB : 43|1@0+ (1,0) [0|1] ""  BCM_Gp,GWM
 SG_ PKeyId : 31|8@0+ (1,0) [0|255] "See description for encoding"  BCM_Gp,GWM
 SG_ PKeyId_UB : 16|1@0+ (1,0) [0|1] ""  BCM_Gp,GWM
 SG_ PKeyIdScanArea : 46|3@0+ (1,0) [0|7] ""  BCM_Gp,GWM
 SG_ PKeyIdScanArea_UB : 47|1@0+ (1,0) [0|1] ""  BCM_Gp,GWM
 SG_ PKeyIdsInAreaReported : 18|2@0+ (1,0) [0|3] ""  BCM_Gp,GWM
 SG_ PKeyIdsInAreaReported_UB : 19|1@0+ (1,0) [0|1] ""  BCM_Gp,GWM

BO_ 484 RFA_SP_GW_2: 8 RFA
 SG_ PEPullSwitchStatus : 27|3@0+ (1,0) [6|7] "Unused (Undefined)"  BCM_Gp,GWM
 SG_ PEPullSwitchStatus_UB : 28|1@0+ (1,0) [0|1] ""  BCM_Gp,GWM
 SG_ PKBattStatus : 29|1@0+ (1,0) [0|1] ""  BCM_Gp,GWM
 SG_ PKBattStatus_UB : 30|1@0+ (1,0) [0|1] ""  BCM_Gp,GWM
 SG_ PkeyScanComp : 31|1@0+ (1,0) [0|1] ""  GWM,Virtual_Node
 SG_ PkeyScanComp_UB : 16|1@0+ (1,0) [0|1] ""  GWM,Virtual_Node
 SG_ PKeyScanID : 63|8@0+ (1,0) [0|255] "See description for encoding"  GWM,Virtual_Node
 SG_ PKeyScanID_UB : 48|1@0+ (1,0) [0|1] ""  GWM,Virtual_Node
 SG_ PKeyWarningInd : 49|1@0+ (1,0) [0|1] ""  BCM_Gp,GWM
 SG_ PKeyWarningInd_UB : 50|1@0+ (1,0) [0|1] ""  BCM_Gp,GWM
 SG_ PLockRequestDD : 51|1@0+ (1,0) [0|1] ""  BCM_Gp,GWM
 SG_ PLockRequestDD_UB : 52|1@0+ (1,0) [0|1] ""  BCM_Gp,GWM
 SG_ PLockRequestPD : 53|1@0+ (1,0) [0|1] ""  BCM_Gp,GWM
 SG_ PLockRequestPD_UB : 54|1@0+ (1,0) [0|1] ""  BCM_Gp,GWM
 SG_ PLockRequestRL : 55|1@0+ (1,0) [0|1] ""  BCM_Gp,GWM
 SG_ PLockRequestRL_UB : 40|1@0+ (1,0) [0|1] ""  BCM_Gp,GWM
 SG_ PLockRequestRR : 41|1@0+ (1,0) [0|1] ""  BCM_Gp,GWM
 SG_ PLockRequestRR_UB : 42|1@0+ (1,0) [0|1] ""  BCM_Gp,GWM
 SG_ PLockRequestTrunk : 43|1@0+ (1,0) [0|1] ""  BCM_Gp,GWM
 SG_ PLockRequestTrunk_UB : 44|1@0+ (1,0) [0|1] ""  BCM_Gp,GWM
 SG_ PUnlockRequestDD : 45|1@0+ (1,0) [0|1] ""  BCM_Gp,GWM
 SG_ PUnlockRequestDD_UB : 46|1@0+ (1,0) [0|1] ""  BCM_Gp,GWM
 SG_ PUnlockRequestPD : 47|1@0+ (1,0) [0|1] ""  BCM_Gp,GWM
 SG_ PUnlockRequestPD_UB : 32|1@0+ (1,0) [0|1] ""  BCM_Gp,GWM
 SG_ PUnlockRequestRL : 33|1@0+ (1,0) [0|1] ""  BCM_Gp,GWM
 SG_ PUnlockRequestRL_UB : 34|1@0+ (1,0) [0|1] ""  BCM_Gp,GWM
 SG_ PUnlockRequestRR : 35|1@0+ (1,0) [0|1] ""  BCM_Gp,GWM
 SG_ PUnlockRequestRR_UB : 36|1@0+ (1,0) [0|1] ""  BCM_Gp,GWM
 SG_ PUnlockRequestTGlass : 37|1@0+ (1,0) [0|1] ""  BCM_Gp,GWM
 SG_ PUnlockRequestTGlass_UB : 38|1@0+ (1,0) [0|1] ""  BCM_Gp,GWM
 SG_ PUnlockRequestTrunk : 39|1@0+ (1,0) [0|1] ""  BCM_Gp,GWM
 SG_ PUnlockRequestTrunk_UB : 24|1@0+ (1,0) [0|1] ""  BCM_Gp,GWM

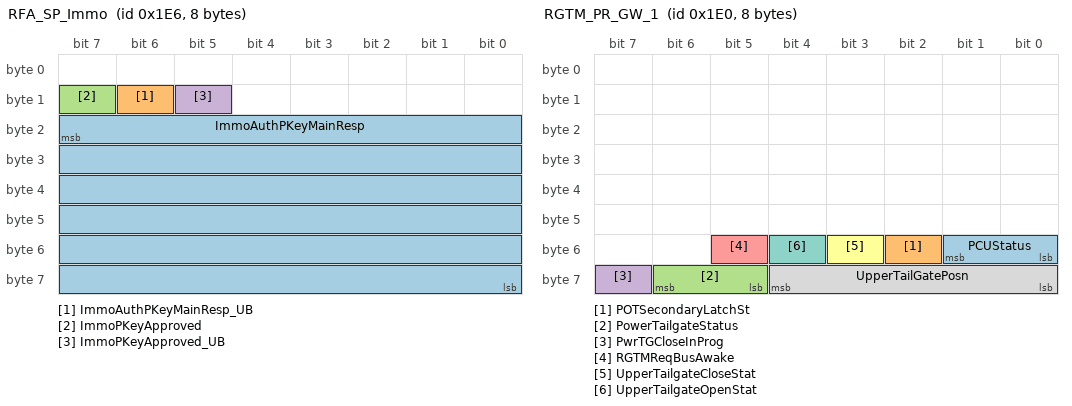
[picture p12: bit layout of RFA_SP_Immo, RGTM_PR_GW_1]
BO_ 486 RFA_SP_Immo: 8 RFA
 SG_ ImmoAuthPKeyMainResp : 23|48@0+ (1,0) [0|281474976710655] ""  BCM_Gp
 SG_ ImmoAuthPKeyMainResp_UB : 14|1@0+ (1,0) [0|1] ""  BCM_Gp
 SG_ ImmoPKeyApproved : 15|1@0+ (1,0) [0|1] ""  BCM_Gp
 SG_ ImmoPKeyApproved_UB : 13|1@0+ (1,0) [0|1] ""  BCM_Gp

BO_ 1318 RGTM_NM526: 8 RGTM
 SG_ NMmessageRGTM : 7|64@0+ (1,0) [0|1.84467440737096E+019] ""  Virtual_Node

BO_ 480 RGTM_PR_GW_1: 8 RGTM
 SG_ PCUStatus : 49|2@0+ (1,0) [0|3] ""  BCM_Gp,RGTMB
 SG_ POTSecondaryLatchSt : 50|1@0+ (1,0) [0|1] ""  RGTMB
 SG_ PowerTailgateStatus : 62|2@0+ (1,0) [0|3] ""  GWM,RGTMB
 SG_ PwrTGCloseInProg : 63|1@0+ (1,0) [0|1] ""  BCM_Gp
 SG_ RGTMReqBusAwake : 53|1@0+ (1,0) [0|1] ""  GWM
 SG_ UpperTailgateCloseStat : 51|1@0+ (1,0) [0|1] ""  RGTMB
 SG_ UpperTailgateOpenStat : 52|1@0+ (1,0) [0|1] ""  RGTMB
 SG_ UpperTailGatePosn : 60|5@0+ (1,0) [0|31] "Positional Data of Upper or lowe"  RGTMB

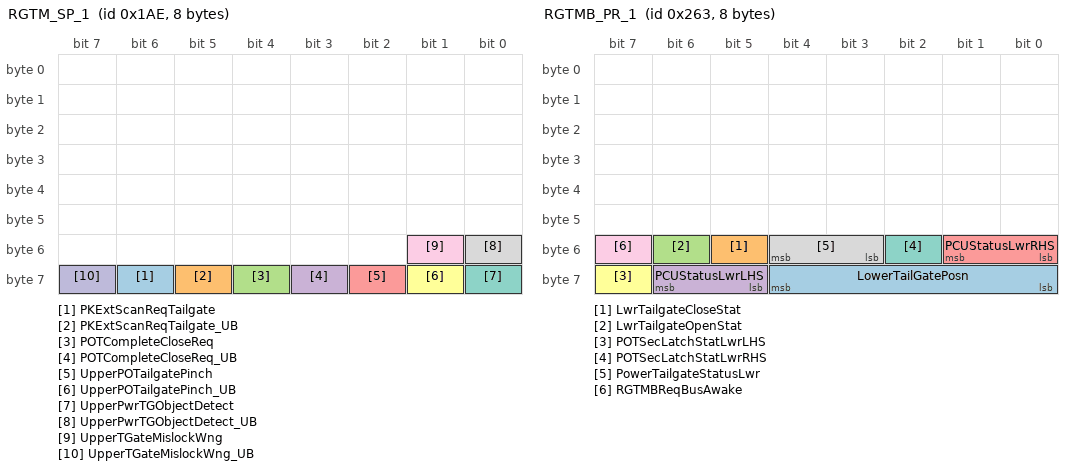
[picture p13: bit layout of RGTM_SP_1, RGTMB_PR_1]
BO_ 430 RGTM_SP_1: 8 RGTM
 SG_ PKExtScanReqTailgate : 62|1@0+ (1,0) [0|1] ""  RFA
 SG_ PKExtScanReqTailgate_UB : 61|1@0+ (1,0) [0|1] ""  RFA
 SG_ POTCompleteCloseReq : 60|1@0+ (1,0) [0|1] ""  RGTMB
 SG_ POTCompleteCloseReq_UB : 59|1@0+ (1,0) [0|1] ""  RGTMB
 SG_ UpperPOTailgatePinch : 58|1@0+ (1,0) [0|1] ""  RGTMB
 SG_ UpperPOTailgatePinch_UB : 57|1@0+ (1,0) [0|1] ""  RGTMB
 SG_ UpperPwrTGObjectDetect : 56|1@0+ (1,0) [0|1] ""  RGTMB
 SG_ UpperPwrTGObjectDetect_UB : 48|1@0+ (1,0) [0|1] ""  RGTMB
 SG_ UpperTGateMislockWng : 49|1@0+ (1,0) [0|1] ""  BCM_Gp
 SG_ UpperTGateMislockWng_UB : 63|1@0+ (1,0) [0|1] ""  BCM_Gp

BO_ 1402 RGTMB_NM57A: 8 RGTMB
 SG_ NMmessageRGTMB : 7|64@0+ (1,0) [0|1.84467440737096E+019] ""  Virtual_Node

BO_ 611 RGTMB_PR_1: 8 RGTMB
 SG_ LowerTailGatePosn : 60|5@0+ (1,0) [0|31] "Positional Data of Upper or lowe"  RGTM
 SG_ LwrTailgateCloseStat : 53|1@0+ (1,0) [0|1] ""  RGTM
 SG_ LwrTailgateOpenStat : 54|1@0+ (1,0) [0|1] ""  RGTM
 SG_ PCUStatusLwrLHS : 62|2@0+ (1,0) [0|3] ""  BCM_Gp,RGTM
 SG_ PCUStatusLwrRHS : 49|2@0+ (1,0) [0|3] ""  BCM_Gp,RGTM
 SG_ POTSecLatchStatLwrLHS : 63|1@0+ (1,0) [0|1] ""  RGTM
 SG_ POTSecLatchStatLwrRHS : 50|1@0+ (1,0) [0|1] ""  RGTM
 SG_ PowerTailgateStatusLwr : 52|2@0+ (1,0) [0|3] ""  RGTM
 SG_ RGTMBReqBusAwake : 55|1@0+ (1,0) [0|1] ""  GWM

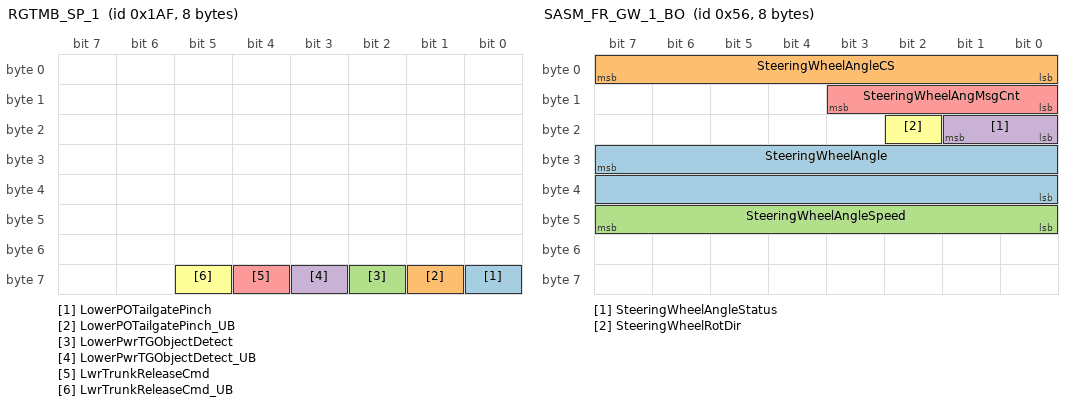
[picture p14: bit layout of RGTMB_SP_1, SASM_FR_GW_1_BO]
BO_ 431 RGTMB_SP_1: 8 RGTMB
 SG_ LowerPOTailgatePinch : 56|1@0+ (1,0) [0|1] ""  RGTM
 SG_ LowerPOTailgatePinch_UB : 57|1@0+ (1,0) [0|1] ""  RGTM
 SG_ LowerPwrTGObjectDetect : 58|1@0+ (1,0) [0|1] ""  RGTM
 SG_ LowerPwrTGObjectDetect_UB : 59|1@0+ (1,0) [0|1] ""  RGTM
 SG_ LwrTrunkReleaseCmd : 60|1@0+ (1,0) [0|1] ""  BCM_Gp,RGTM
 SG_ LwrTrunkReleaseCmd_UB : 61|1@0+ (1,0) [0|1] ""  BCM_Gp,RGTM

BO_ 1306 RLSM_NM51A: 8 RLSM
 SG_ NMmessageRLSM : 7|64@0+ (1,0) [0|1.84467440737096E+019] ""  Virtual_Node

BO_ 389 RLSM_PR_GW_1: 8 RLSM
 SG_ PassSeatHghtDownReqRL : 25|1@0+ (1,0) [0|1] ""  PSM
 SG_ PassSeatHghtUpReqRL : 24|1@0+ (1,0) [0|1] ""  PSM
 SG_ PassSeatHRestAftReqRL : 39|1@0+ (1,0) [0|1] ""  PSM
 SG_ PassSeatHRestDwnReqRL : 38|1@0+ (1,0) [0|1] ""  PSM
 SG_ PassSeatHRestForeReqRL : 37|1@0+ (1,0) [0|1] ""  PSM
 SG_ PassSeatHRestUpReqRL : 36|1@0+ (1,0) [0|1] ""  PSM
 SG_ PassSeatInclineReqRL : 55|1@0+ (1,0) [0|1] ""  PSM
 SG_ PassSeatMemClrReqRL : 35|2@0+ (1,0) [0|3] ""  PSM
 SG_ PassSeatMemClrReqRR : 33|2@0+ (1,0) [0|3] ""  PSM
 SG_ PassSeatMemLoadReqRL : 47|2@0+ (1,0) [0|3] ""  PSM
 SG_ PassSeatMemStrReqRL : 45|2@0+ (1,0) [0|3] ""  PSM
 SG_ PassSeatMoveReqRL : 43|4@0+ (1,0) [8|15] "Reserved"  PSM
 SG_ PassSeatReclineReqRL : 54|1@0+ (1,0) [0|1] ""  PSM
 SG_ PassSeatSlideAftReqRL : 53|1@0+ (1,0) [0|1] ""  PSM
 SG_ PassSeatSlideForeReqRL : 52|1@0+ (1,0) [0|1] ""  PSM
 SG_ PSARequestRL : 63|2@0+ (1,0) [0|3] ""  PSM
 SG_ RCntrSeatMoveSelStat : 61|1@0+ (1,0) [0|1] ""  GWM
 SG_ RCntrSeatMovmentStat : 51|4@0+ (1,0) [0|15] ""  DSM,GWM,PSM,RRSM
 SG_ RCntrSeatUpperLidStat : 60|1@0+ (1,0) [0|1] ""  RRSM
 SG_ RearLeftCancelSeat : 59|1@0+ (1,0) [0|1] ""  DSM,PSM
 SG_ RearSeatFoldFlatReqRL : 58|2@0+ (1,0) [0|3] ""  PSM
 SG_ RLSMSeatMovement : 26|1@0+ (1,0) [0|1] ""  PSM
 SG_ RMSeatInhib2ndRow : 56|1@0+ (1,0) [0|1] ""  GWM,RRSM

BO_ 390 RLSM_PR_GW_2: 8 RLSM
 SG_ RLeftTableDeployed : 56|1@0+ (1,0) [0|1] ""  DSM,GWM,PSM
 SG_ RLSeatCalfRestStat : 58|2@0+ (1,0) [0|3] ""  DSM,GWM,PSM
 SG_ RLSeatFoldFlatReq : 61|3@0+ (1,0) [0|7] ""  DSM,GWM,PSM
 SG_ RLSeatFootRestReq : 62|1@0+ (1,0) [0|1] ""  DSM,GWM,PSM
 SG_ RLSeatInhib2ndRow : 63|1@0+ (1,0) [0|1] ""  GWM
 SG_ RLSeatMasgIntStat : 50|3@0+ (1,0) [0|7] ""  GWM
 SG_ RLSeatMasgLocStat : 53|3@0+ (1,0) [0|7] ""  GWM
 SG_ RLSeatMasgModeStatFr : 34|3@0+ (1,0) [5|7] "Unused"  GWM
 SG_ RLSeatMasgProgStat : 44|3@0+ (1,0) [0|7] ""  GWM
 SG_ RLSeatMasgStatFr : 35|1@0+ (1,0) [0|1] ""  GWM
 SG_ RLSeatMassageModeStat : 47|3@0+ (1,0) [5|7] "unused"  GWM
 SG_ RLSeatMemLoadStat : 55|2@0+ (1,0) [0|3] ""  GWM
 SG_ RLSeatMemStorStat : 41|2@0+ (1,0) [0|3] ""  GWM
 SG_ RLSeatMovementStat : 39|4@0+ (1,0) [8|15] "Reserved"  DSM,GWM,PSM
 SG_ RLSeatMoveSelStat : 24|1@0+ (1,0) [0|1] ""  GWM
 SG_ RLSeatMsgAvailFr : 25|1@0+ (1,0) [0|1] ""  GWM
 SG_ RLSeatOccupancyStat : 26|1@0+ (1,0) [0|1] ""  GWM,PSM

BO_ 1327 RPDM_NM52F: 8 RPDM
 SG_ NMMessageRPDM : 7|64@0+ (1,0) [0|1.84467440737096E+019] ""  Virtual_Node

BO_ 530 RPDM_PR_GW_2: 8 RPDM
 SG_ RightPowerDoorStatus : 59|4@0+ (1,0) [0|15] ""  GWM

BO_ 1385 RRSM_NM569: 8 RRSM
 SG_ NMmessageRRSM : 7|64@0+ (1,0) [0|1.84467440737096E+019] ""  Virtual_Node

BO_ 682 RRSM_PR_GW_1: 8 RRSM
 SG_ CupHolderReq : 57|2@0+ (1,0) [0|3] ""  GWM,RLSM
 SG_ PassSeatHghtDownReqRR : 58|1@0+ (1,0) [0|1] ""  GWM,PSM
 SG_ PassSeatHghtUpReqRR : 59|1@0+ (1,0) [0|1] ""  GWM,PSM
 SG_ PassSeatHRestAftReqRR : 60|1@0+ (1,0) [0|1] ""  GWM,PSM
 SG_ PassSeatHRestDwnReqRR : 61|1@0+ (1,0) [0|1] ""  GWM,PSM
 SG_ PassSeatHRestForeReqRR : 62|1@0+ (1,0) [0|1] ""  GWM,PSM
 SG_ PassSeatHRestUpReqRR : 63|1@0+ (1,0) [0|1] ""  GWM,PSM
 SG_ PassSeatInclineReqRR : 48|1@0+ (1,0) [0|1] ""  GWM,PSM
 SG_ PassSeatMemLoadReqRR : 50|2@0+ (1,0) [0|3] ""  GWM,PSM
 SG_ PassSeatMemStrReqRR : 52|2@0+ (1,0) [0|3] ""  GWM,PSM
 SG_ PassSeatMoveReqRR : 43|4@0+ (1,0) [8|15] "Reserved"  GWM,PSM
 SG_ PassSeatReclineReqRR : 55|1@0+ (1,0) [0|1] ""  GWM,PSM
 SG_ PassSeatSlideAftReqRR : 45|1@0+ (1,0) [0|1] ""  GWM,PSM
 SG_ PassSeatSlideForeReqRR : 44|1@0+ (1,0) [0|1] ""  GWM,PSM
 SG_ PSARequestRR : 54|2@0+ (1,0) [0|3] ""  GWM,PSM
 SG_ RearLeftFoldSwStat : 46|1@0+ (1,0) [0|1] ""  GWM,RLSM
 SG_ RearLeftUnfoldSwStat : 47|1@0+ (1,0) [0|1] ""  GWM,RLSM
 SG_ RearRightCancelSeat : 32|1@0+ (1,0) [0|1] ""  DSM,GWM,PSM
 SG_ RearSeatFoldFlatReqRR : 34|2@0+ (1,0) [0|3] ""  GWM,PSM
 SG_ RRightTableDeployed : 35|1@0+ (1,0) [0|1] ""  DSM,GWM,PSM
 SG_ RRSeatCalfRestStat : 37|2@0+ (1,0) [0|3] ""  DSM,GWM,PSM
 SG_ RRSeatFoldFlatReq : 26|3@0+ (1,0) [0|7] ""  DSM,GWM,PSM
 SG_ RRSeatFootRestReq : 38|1@0+ (1,0) [0|1] ""  DSM,GWM,PSM
 SG_ RRSeatInhib2ndRow : 18|1@0+ (1,0) [0|1] ""  GWM
 SG_ RRSeatMasgAvailFr : 8|1@0+ (1,0) [0|1] ""  GWM
 SG_ RRSeatMasgIntStat : 4|3@0+ (1,0) [0|7] ""  GWM
 SG_ RRSeatMasgLocStat : 7|3@0+ (1,0) [0|7] ""  GWM
 SG_ RRSeatMasgModeStatFr : 12|3@0+ (1,0) [5|7] "Unused"  GWM
 SG_ RRSeatMasgProgStat : 15|3@0+ (1,0) [0|7] ""  GWM
 SG_ RRSeatMasgStatFr : 9|1@0+ (1,0) [0|1] ""  GWM
 SG_ RRSeatMemLoadStat : 20|2@0+ (1,0) [0|3] ""  GWM
 SG_ RRSeatMemStorStat : 22|2@0+ (1,0) [0|3] ""  GWM
 SG_ RRSeatMovementStat : 30|4@0+ (1,0) [8|15] "Reserved"  DSM,GWM,PSM
 SG_ RRSeatMoveSelStat : 23|1@0+ (1,0) [0|1] ""  GWM
 SG_ RRSeatOccupancyStat : 39|1@0+ (1,0) [0|1] ""  GWM,PSM
 SG_ RRSMSeatMovement : 31|1@0+ (1,0) [0|1] ""  GWM,PSM
 SG_ SkiHatchStat : 16|1@0+ (1,0) [0|1] ""  GWM,RLSM
 SG_ SkiHatchSwitchStat : 17|1@0+ (1,0) [0|1] ""  GWM,RLSM

BO_ 86 SASM_FR_GW_1_BO: 8 GWM
 SG_ SteeringWheelAngle : 31|16@0+ (0.1,-780) [-780|780] "Degrees"  BCM_Gp
 SG_ SteeringWheelAngleCS : 7|8@0+ (1,0) [0|255] "Checksum"  Vector_XXX
 SG_ SteeringWheelAngleSpeed : 47|8@0+ (4,0) [0|1016] "Rotational Speed (deg/sec)"  BCM_Gp
 SG_ SteeringWheelAngleStatus : 17|2@0+ (1,0) [0|3] ""  BCM_Gp
 SG_ SteeringWheelAngMsgCnt : 11|4@0+ (1,0) [0|15] "Counter value"  Vector_XXX
 SG_ SteeringWheelRotDir : 18|1@0+ (1,0) [0|1] ""  Vector_XXX

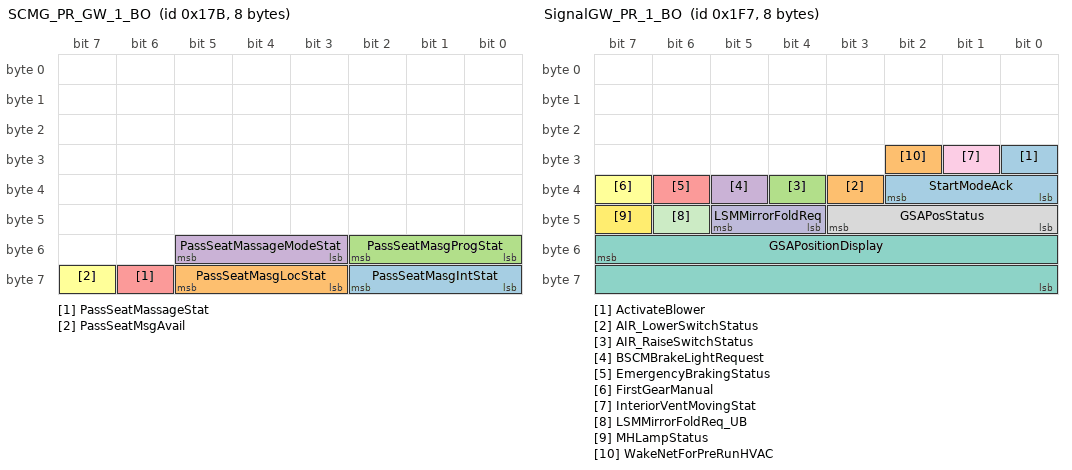
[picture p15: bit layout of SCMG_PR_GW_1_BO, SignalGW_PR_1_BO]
BO_ 379 SCMG_PR_GW_1_BO: 8 PSM
 SG_ PassSeatMasgIntStat : 58|3@0+ (1,0) [0|7] ""  GWM
 SG_ PassSeatMasgLocStat : 61|3@0+ (1,0) [0|7] ""  GWM
 SG_ PassSeatMasgProgStat : 50|3@0+ (1,0) [0|7] ""  GWM
 SG_ PassSeatMassageModeStat : 53|3@0+ (1,0) [0|7] ""  GWM
 SG_ PassSeatMassageStat : 62|1@0+ (1,0) [0|1] ""  GWM
 SG_ PassSeatMsgAvail : 63|1@0+ (1,0) [0|1] ""  GWM

BO_ 503 SignalGW_PR_1_BO: 8 GWM
 SG_ ActivateBlower : 24|1@0+ (1,0) [0|1] ""  BCM_Gp
 SG_ AIR_LowerSwitchStatus : 35|1@0+ (1,0) [0|1] ""  BCM_Gp
 SG_ AIR_RaiseSwitchStatus : 36|1@0+ (1,0) [0|1] ""  BCM_Gp
 SG_ BSCMBrakeLightRequest : 37|1@0+ (1,0) [0|1] ""  BCM_Gp
 SG_ EmergencyBrakingStatus : 38|1@0+ (1,0) [0|1] ""  BCM_Gp,LPDM,RPDM,TBM
 SG_ FirstGearManual : 39|1@0+ (1,0) [0|1] ""  BCM_Gp
 SG_ GSAPositionDisplay : 55|16@0+ (1,0) [0|65535] ""  BCM_Gp
 SG_ GSAPosStatus : 43|4@0+ (1,0) [0|15] ""  BCM_Gp,DDM,DRDM,DSM,PDM,PRDM,PSM,RLSM,RRSM
 SG_ InteriorVentMovingStat : 25|1@0+ (1,0) [0|1] ""  BCM_Gp
 SG_ LSMMirrorFoldReq : 45|2@0+ (1,0) [0|3] ""  DDM
 SG_ LSMMirrorFoldReq_UB : 46|1@0+ (1,0) [0|1] ""  DDM
 SG_ MHLampStatus : 47|1@0+ (1,0) [0|1] ""  BCM_Gp
 SG_ StartModeAck : 34|3@0+ (1,0) [0|7] ""  BCM_Gp
 SG_ WakeNetForPreRunHVAC : 26|1@0+ (1,0) [0|1] ""  BCM_Gp

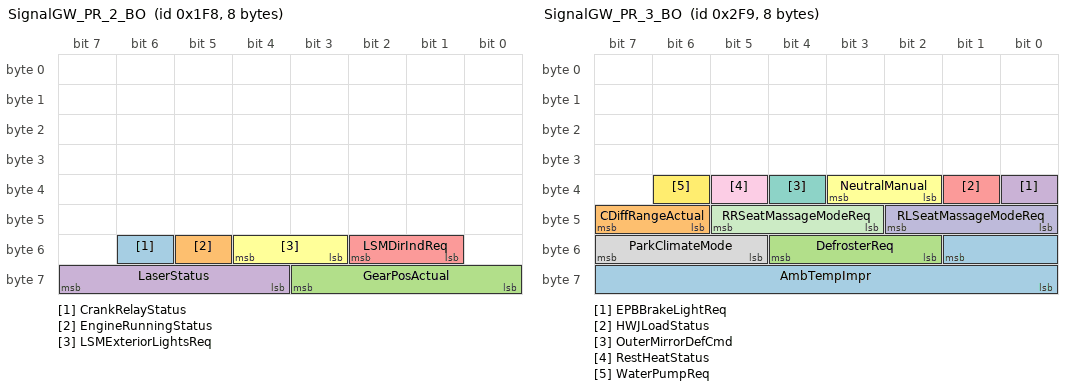
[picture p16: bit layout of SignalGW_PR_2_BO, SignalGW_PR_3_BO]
BO_ 504 SignalGW_PR_2_BO: 8 GWM
 SG_ CrankRelayStatus : 54|1@0+ (1,0) [0|1] ""  BCM_Gp
 SG_ EngineRunningStatus : 53|1@0+ (1,0) [0|1] ""  BCM_Gp
 SG_ GearPosActual : 59|4@0+ (1,0) [0|15] ""  BCM_Gp
 SG_ LaserStatus : 63|4@0+ (1,0) [4|14] "unused"  BCM_Gp
 SG_ LSMDirIndReq : 50|2@0+ (1,0) [0|3] ""  BCM_Gp
 SG_ LSMExteriorLightsReq : 52|2@0+ (1,0) [0|3] ""  BCM_Gp

BO_ 761 SignalGW_PR_3_BO: 8 GWM
 SG_ AmbTempImpr : 49|10@0+ (0.25,-128) [-128|127.75] "Degrees C"  BCM_Gp
 SG_ CDiffRangeActual : 47|2@0+ (1,0) [0|3] ""  BCM_Gp,TBM
 SG_ DefrosterReq : 52|3@0+ (1,0) [0|7] "See description text - bit encod"  BCM_Gp
 SG_ EPBBrakeLightReq : 32|1@0+ (1,0) [0|1] ""  BCM_Gp
 SG_ HWJLoadStatus : 33|1@0+ (1,0) [0|1] ""  BCM_Gp
 SG_ NeutralManual : 35|2@0+ (1,0) [0|3] ""  TBM
 SG_ OuterMirrorDefCmd : 36|1@0+ (1,0) [0|1] ""  DDM,PDM
 SG_ ParkClimateMode : 55|3@0+ (1,0) [5|7] "unused"  BCM_Gp
 SG_ RestHeatStatus : 37|1@0+ (1,0) [0|1] ""  BCM_Gp
 SG_ RLSeatMassageModeReq : 42|3@0+ (1,0) [5|7] "unused"  RLSM
 SG_ RRSeatMassageModeReq : 45|3@0+ (1,0) [5|7] "unused"  RRSM
 SG_ WaterPumpReq : 38|1@0+ (1,0) [0|1] ""  BCM_Gp

BO_ 197 SODL_PR_GW_1_BO: 8 GWM
 SG_ ABRCTAEventStatus : 38|1@0+ (1,0) [0|1] ""  Vector_XXX
 SG_ ABRCTAMonitoringMode : 13|2@0+ (1,0) [0|3] ""  Vector_XXX
 SG_ ABRCTASystemState : 41|2@0+ (1,0) [0|3] ""  Vector_XXX
 SG_ ARAAlertLeft : 33|2@0+ (1,0) [0|3] ""  DDM,PDM
 SG_ AVCMLeftTargetDet : 22|1@0+ (1,0) [0|1] ""  Vector_XXX
 SG_ BSMLeftAlert : 19|1@0+ (1,0) [0|1] ""  DDM,PDM
 SG_ BSMLeftBlocked : 39|1@0+ (1,0) [0|1] ""  Vector_XXX
 SG_ BSMLeftCVWAlert : 18|1@0+ (1,0) [0|1] ""  DDM,PDM
 SG_ BSMLeftSensorState : 37|4@0+ (1,0) [0|15] ""  DDM,PDM
 SG_ BSMLeftServiceRequired : 44|1@0+ (1,0) [0|1] ""  Vector_XXX
 SG_ BSMLeftUnavailable : 45|1@0+ (1,0) [0|1] ""  Vector_XXX
 SG_ BSMMonitoringMode : 29|3@0+ (1,0) [4|7] "Reserved for future enhancements"  Vector_XXX
 SG_ BSMSystemState : 31|2@0+ (1,0) [0|3] ""  Vector_XXX
 SG_ LeftREDAlert : 15|2@0+ (1,0) [0|3] ""  DDM,DRDM,PDM,PRDM
 SG_ RCTAStatus : 17|2@0+ (1,0) [0|3] ""  Vector_XXX
 SG_ RPCStatus : 26|3@0+ (1,0) [0|7] ""  Vector_XXX
 SG_ RPCUserModeStatus : 21|2@0+ (1,0) [0|3] ""  Vector_XXX
 SG_ SODGlobalActuatorReq : 43|2@0+ (1,0) [0|3] ""  Vector_XXX
 SG_ SODLAliveCounter : 11|4@0+ (1,0) [0|15] ""  Vector_XXX
 SG_ SODLightingRequest : 23|1@0+ (1,0) [0|1] ""  Vector_XXX

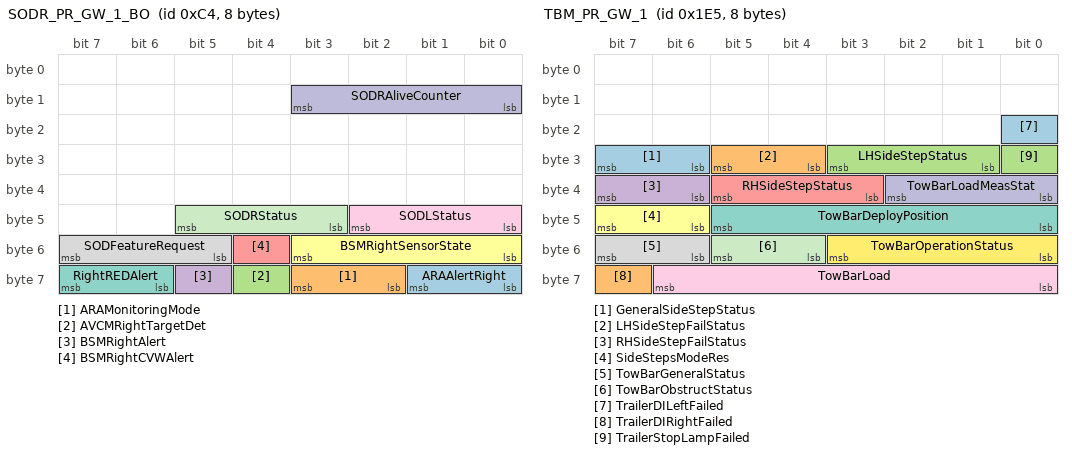
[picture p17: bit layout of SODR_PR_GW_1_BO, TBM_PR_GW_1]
BO_ 196 SODR_PR_GW_1_BO: 8 GWM
 SG_ ARAAlertRight : 57|2@0+ (1,0) [0|3] ""  DDM,PDM
 SG_ ARAMonitoringMode : 59|2@0+ (1,0) [0|3] ""  Vector_XXX
 SG_ AVCMRightTargetDet : 60|1@0+ (1,0) [0|1] ""  Vector_XXX
 SG_ BSMRightAlert : 61|1@0+ (1,0) [0|1] ""  DDM,PDM
 SG_ BSMRightCVWAlert : 52|1@0+ (1,0) [0|1] ""  DDM,PDM
 SG_ BSMRightSensorState : 51|4@0+ (1,0) [0|15] ""  DDM,PDM
 SG_ RightREDAlert : 63|2@0+ (1,0) [0|3] ""  DDM,DRDM,PDM,PRDM
 SG_ SODFeatureRequest : 55|3@0+ (1,0) [0|7] ""  Vector_XXX
 SG_ SODLStatus : 42|3@0+ (1,0) [0|7] ""  Vector_XXX
 SG_ SODRAliveCounter : 11|4@0+ (1,0) [0|15] ""  Vector_XXX
 SG_ SODRStatus : 45|3@0+ (1,0) [0|7] ""  Vector_XXX

BO_ 1344 TBM_NM540: 8 TBM
 SG_ NMmessageTBM : 7|64@0+ (1,0) [0|1.84467440737096E+019] ""  Virtual_Node

BO_ 485 TBM_PR_GW_1: 8 TBM
 SG_ GeneralSideStepStatus : 31|2@0+ (1,0) [0|3] ""  GWM
 SG_ LHSideStepFailStatus : 29|2@0+ (1,0) [0|3] ""  GWM
 SG_ LHSideStepStatus : 27|3@0+ (1,0) [0|7] ""  GWM
 SG_ RHSideStepFailStatus : 39|2@0+ (1,0) [0|3] ""  GWM
 SG_ RHSideStepStatus : 37|3@0+ (1,0) [0|7] ""  GWM
 SG_ SideStepsModeRes : 47|2@0+ (1,0) [0|3] ""  GWM
 SG_ TowBarDeployPosition : 45|6@0+ (1,0) [1|16] "progress of unlocking while stow"  GWM
 SG_ TowBarGeneralStatus : 55|2@0+ (1,0) [0|3] ""  GWM
 SG_ TowBarLoad : 62|7@0+ (5,-100) [-100|500] "Maximum nose Load to be displaye"  GWM
 SG_ TowBarLoadMeasStat : 34|3@0+ (1,0) [0|7] ""  GWM
 SG_ TowBarObstructStatus : 53|2@0+ (1,0) [0|3] ""  GWM
 SG_ TowBarOperationStatus : 51|4@0+ (1,0) [12|14] "Reserved"  GWM
 SG_ TrailerDILeftFailed : 16|1@0+ (1,0) [0|1] ""  BCM_Gp,GWM
 SG_ TrailerDIRightFailed : 63|1@0+ (1,0) [0|1] ""  BCM_Gp,GWM
 SG_ TrailerStopLampFailed : 24|1@0+ (1,0) [0|1] ""  BCM_Gp,GWM

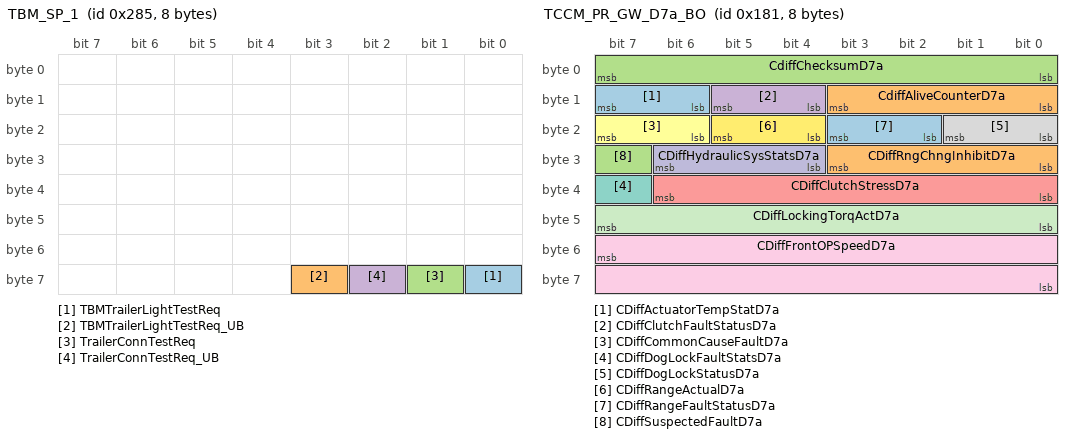
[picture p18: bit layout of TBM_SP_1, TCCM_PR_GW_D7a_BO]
BO_ 645 TBM_SP_1: 8 TBM
 SG_ TBMTrailerLightTestReq : 56|1@0+ (1,0) [0|1] ""  BCM_Gp
 SG_ TBMTrailerLightTestReq_UB : 59|1@0+ (1,0) [0|1] ""  BCM_Gp
 SG_ TrailerConnTestReq : 57|1@0+ (1,0) [0|1] ""  BCM_Gp
 SG_ TrailerConnTestReq_UB : 58|1@0+ (1,0) [0|1] ""  BCM_Gp

BO_ 385 TCCM_PR_GW_D7a_BO: 8 GWM
 SG_ CDiffActuatorTempStatD7a : 15|2@0+ (1,0) [0|3] ""  Vector_XXX
 SG_ CdiffAliveCounterD7a : 11|4@0+ (1,0) [0|15] "Counter value"  Vector_XXX
 SG_ CdiffChecksumD7a : 7|8@0+ (1,0) [0|255] "checksum"  Vector_XXX
 SG_ CDiffClutchFaultStatusD7a : 13|2@0+ (1,0) [0|3] ""  Vector_XXX
 SG_ CDiffClutchStressD7a : 38|7@0+ (1,0) [0|100] "percent of clutch stress"  Vector_XXX
 SG_ CDiffCommonCauseFaultD7a : 23|2@0+ (1,0) [0|3] ""  Vector_XXX
 SG_ CDiffDogLockFaultStatsD7a : 39|1@0+ (1,0) [0|1] ""  Vector_XXX
 SG_ CDiffDogLockStatusD7a : 17|2@0+ (1,0) [0|3] ""  Vector_XXX
 SG_ CDiffFrontOPSpeedD7a : 55|16@0+ (1,0) [0|8000] "RPM"  Vector_XXX
 SG_ CDiffHydraulicSysStatsD7a : 30|3@0+ (1,0) [0|7] ""  Vector_XXX
 SG_ CDiffLockingTorqActD7a : 47|8@0+ (15,0) [0|3000] "Nm"  Vector_XXX
 SG_ CDiffRangeActualD7a : 21|2@0+ (1,0) [0|3] ""  BCM_Gp,TBM
 SG_ CDiffRangeFaultStatusD7a : 19|2@0+ (1,0) [0|3] ""  Vector_XXX
 SG_ CDiffRngChngInhibitD7a : 27|4@0+ (1,0) [0|15] ""  Vector_XXX
 SG_ CDiffSuspectedFaultD7a : 31|1@0+ (1,0) [0|1] ""  Vector_XXX

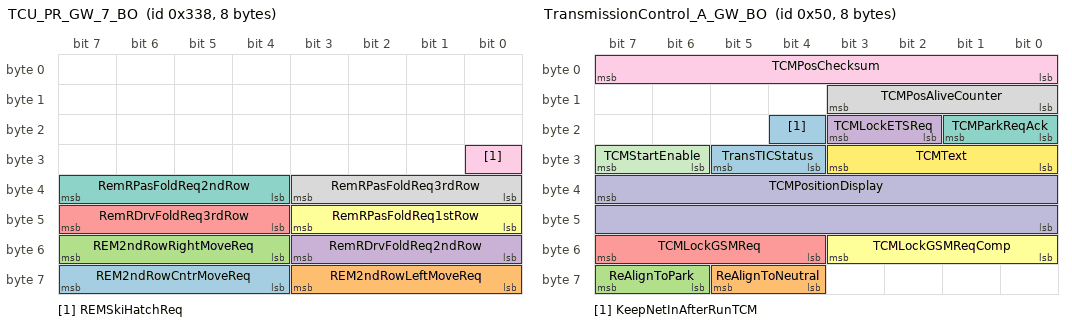
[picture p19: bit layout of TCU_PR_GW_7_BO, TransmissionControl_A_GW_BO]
BO_ 824 TCU_PR_GW_7_BO: 8 GWM
 SG_ REM2ndRowCntrMoveReq : 63|4@0+ (1,0) [4|15] "Reserved"  RLSM
 SG_ REM2ndRowLeftMoveReq : 59|4@0+ (1,0) [4|15] "Reserved"  DSM,PSM,RLSM
 SG_ REM2ndRowRightMoveReq : 55|4@0+ (1,0) [4|15] "Reserved"  DSM,PSM,RRSM
 SG_ RemRDrvFoldReq2ndRow : 51|4@0+ (1,0) [4|15] "Reserved"  Vector_XXX
 SG_ RemRDrvFoldReq3rdRow : 47|4@0+ (1,0) [4|15] "Reserved"  Vector_XXX
 SG_ RemRPasFoldReq1stRow : 43|4@0+ (1,0) [4|15] "Reserved"  Vector_XXX
 SG_ RemRPasFoldReq2ndRow : 39|4@0+ (1,0) [4|15] "Reserved"  Vector_XXX
 SG_ RemRPasFoldReq3rdRow : 35|4@0+ (1,0) [4|15] "Reserved"  Vector_XXX
 SG_ REMSkiHatchReq : 24|1@0+ (1,0) [0|1] ""  RRSM

BO_ 364 TCUDataControl_BO: 8 GWM
 SG_ TCUDataControl : 7|64@0+ (1,0) [0|1.84467440737096E+019] ""  BCM_Gp

BO_ 151 TCUDataTarget_BO: 8 BCM_Gp
 SG_ TCUDataTarget : 7|64@0+ (1,0) [0|1.84467440737096E+019] ""  GWM

BO_ 1612 TEST_RequestKVM_BOCAN: 8 GWM
 SG_ TESTRequestKVM : 7|64@0+ (1,0) [0|1.84467440737096E+019] ""  RFA

BO_ 1613 TEST_ResponseKVM_BOCAN: 8 RFA
 SG_ TESTResponseKVM : 7|64@0+ (1,0) [0|1.84467440737096E+019] ""  GWM

BO_ 949 Timedate_BO: 8 GWM
 SG_ TimeDateSetReq_ICM : 7|64@0+ (1,0) [0|1.84467440737096E+019] ""  BCM_Gp

BO_ 464 Timer: 8 BCM_Gp
 SG_ Timer1Time : 7|32@0+ (1,0) [0|4294967295] ""  GWM
 SG_ Timer2Time : 39|32@0+ (1,0) [0|4294967295] ""  GWM

BO_ 546 Timer1_BO: 8 GWM
 SG_ SetTimer1Time : 23|32@0+ (1,0) [0|4294967295] ""  BCM_Gp
 SG_ SetTimer1Time_UB : 56|1@0+ (1,0) [0|1] ""  BCM_Gp

BO_ 547 Timer2_BO: 8 GWM
 SG_ SetTimer2Time : 23|32@0+ (1,0) [0|4294967295] ""  BCM_Gp
 SG_ SetTimer2Time_UB : 56|1@0+ (1,0) [0|1] ""  BCM_Gp

BO_ 80 TransmissionControl_A_GW_BO: 8 GWM
 SG_ KeepNetInAfterRunTCM : 20|1@0+ (1,0) [0|1] ""  Vector_XXX
 SG_ ReAlignToNeutral : 61|2@0+ (1,0) [0|3] ""  Vector_XXX
 SG_ ReAlignToPark : 63|2@0+ (1,0) [0|3] ""  Vector_XXX
 SG_ TCMLockETSReq : 19|2@0+ (1,0) [0|3] ""  Vector_XXX
 SG_ TCMLockGSMReq : 55|4@0+ (1,0) [3|14] "Not Used"  Vector_XXX
 SG_ TCMLockGSMReqComp : 51|4@0+ (1,0) [1|12] "Not Used"  Vector_XXX
 SG_ TCMParkReqAck : 17|2@0+ (1,0) [0|3] ""  Vector_XXX
 SG_ TCMPosAliveCounter : 11|4@0+ (1,0) [0|15] "Counter"  Vector_XXX
 SG_ TCMPosChecksum : 7|8@0+ (1,0) [0|255] "Counter"  Vector_XXX
 SG_ TCMPositionDisplay : 39|16@0+ (1,0) [0|65535] ""  BCM_Gp,LPDM,RPDM,TBM
 SG_ TCMStartEnable : 31|2@0+ (1,0) [0|3] ""  BCM_Gp
 SG_ TCMText : 27|4@0+ (1,0) [0|15] ""  Vector_XXX
 SG_ TransTICStatus : 29|2@0+ (1,0) [0|3] ""  Vector_XXX

BO_ 2015 TST_FunctionalReq_BOBus: 8 GWM
 SG_ TesterFunctionalReq : 7|64@0+ (1,0) [0|1.84467440737096E+019] ""  DSM,FTCM,FTCMB,LPDM,PSM,RFA,RGTM,RGTMB,RLSM,RPDM,RRSM,TBM,VIM,WDCM

BO_ 1856 TST_PhysicalReqDDM_BOCAN_ASAR: 8 GWM

BO_ 1858 TST_PhysicalReqDRDM_BOCAN_ASAR: 8 GWM

BO_ 1860 TST_PhysicalReqDSM_BOCAN: 8 GWM
 SG_ TesterPhysicalReqDSM : 7|64@0+ (1,0) [0|1.84467440737096E+019] ""  DSM

BO_ 1927 TST_PhysicalReqFTCM_BOCAN: 8 GWM
 SG_ TesterPhysicalReqFTCM : 7|64@0+ (1,0) [0|1.84467440737096E+019] ""  FTCM

BO_ 1936 TST_PhysicalReqFTCMB_BOCAN: 8 GWM
 SG_ TesterPhysicalReqFTCMB : 7|64@0+ (1,0) [0|1.84467440737096E+019] ""  FTCMB

BO_ 1841 TST_PhysicalReqKVM_BOCAN: 8 GWM
 SG_ TesterPhysicalReqKVM : 7|64@0+ (1,0) [0|1.84467440737096E+019] ""  RFA

BO_ 1857 TST_PhysicalReqPDM_BOCAN_ASAR: 8 GWM

BO_ 1859 TST_PhysicalReqPRDM_BOCAN_ASAR: 8 GWM

BO_ 1955 TST_PhysicalReqPSM_BOCAN: 8 GWM
 SG_ TesterPhysicalReqPSM : 7|64@0+ (1,0) [0|1.84467440737096E+019] ""  PSM

BO_ 1909 TST_PhysicalReqRGTM_BOCAN: 8 GWM
 SG_ TesterPhysicalReqRGTM : 7|64@0+ (1,0) [0|1.84467440737096E+019] ""  RGTM

BO_ 1974 TST_PhysicalReqRGTMB_BOCAN: 8 GWM
 SG_ TesterPhysicalReqRGTMB : 7|64@0+ (1,0) [0|1.84467440737096E+019] ""  RGTMB

BO_ 1794 TST_PhysicalReqRLSM_BOCAN: 8 GWM
 SG_ TesterPhysicalReqRLSM : 7|64@0+ (1,0) [0|1.84467440737096E+019] ""  RLSM

BO_ 2016 TST_PhysicalReqRPDM_BOCAN: 8 GWM
 SG_ TesterPhysicalReqRPDM : 7|64@0+ (1,0) [0|1.84467440737096E+019] ""  RPDM

BO_ 1891 TST_PhysicalReqRRSM_BOCAN: 8 GWM
 SG_ TesterPhysicalReqRRSM : 7|64@0+ (1,0) [0|1.84467440737096E+019] ""  RRSM

BO_ 1879 TST_PhysicalReqTBM_BOCAN: 8 GWM
 SG_ TesterPhysicalReqTBM : 7|64@0+ (1,0) [0|1.84467440737096E+019] ""  TBM

BO_ 1826 TST_PhysicalReqVIM_BOCAN: 8 GWM
 SG_ TesterPhysicalReqVIM : 7|64@0+ (1,0) [0|1.84467440737096E+019] ""  VIM

BO_ 1799 TST_PhysicalReqWDCM_BOCAN: 8 GWM
 SG_ TesterPhysicalReqWDCM : 7|64@0+ (1,0) [0|1.84467440737096E+019] ""  WDCM

BO_ 1864 TST_PhysicalRespDDM_BOCAN_ASAR: 8 DDM

BO_ 1866 TST_PhysicalRespDRDM_BOCAN_ASAR: 8 DRDM

BO_ 1868 TST_PhysicalRespDSM_BOCAN: 8 DSM
 SG_ TesterPhysicalResDSM : 7|64@0+ (1,0) [0|1.84467440737096E+019] ""  GWM

BO_ 1935 TST_PhysicalRespFTCM_BOCAN: 8 FTCM
 SG_ TesterPhysicalResFTCM : 7|64@0+ (1,0) [0|1.84467440737096E+019] ""  Vector_XXX

CM_ SG_ 187 AmbLightProfileLoad "Signal to request BCM to load a specific profile";
CM_ SG_ 187 AmbLightProfileStore "Signal to request BCM to store a specific profile";
CM_ SG_ 187 AmbLightUIColourSw "Signal containing colour data from the interior ambient lighting user interface.

No encoding, just a list of numbered colour schemes.";
CM_ SG_ 187 AmbLightUIDynAutoSw "Interior ambient auto-dynamic mode switch status

";
CM_ SG_ 187 AmbLightUIIntensitySw "Intensity level user request for interior ambience lighting";
CM_ SG_ 187 AmbLightUIZoneSw "Interior ambience lighting zone

Bitmapped (1 bit for each zone)
Bit 0 - zone 1
Bit 1 - zone 2
Bit 2 - zone 3
Bit 3 - zone 4
Bit 4 - zone 5

1 = zone addressed
0 = zone NOT addressed";
CM_ SG_ 177 ActivateTimer "Used to activate Timer.";
CM_ SG_ 177 AutoBlindEnableReq "Allows the user to enable or disable the AutoBlind feature";
CM_ SG_ 177 DIAnimationEnableReq "New signal from IPC to BCM to inform when directinal indicator animation is enabled in cluster menu";
CM_ SG_ 177 EEEStateRequest "Request to enable or disable Easy Entry Exit.";
CM_ SG_ 177 EnableDippedMirror "Enable/Disable Dipped Mirror for active key.";
CM_ SG_ 177 GestureBlindEnableSw "Sporadic signal to signify that the Gesture Enable softkey on infotainment touchscreen has been pressed.  This will be in the form of a pulse to 1, and value will default back to zero.";
CM_ SG_ 177 RearCameraWashReq "Infotainment request to Body Control Module for washing the rear camera ";
CM_ SG_ 177 SideStepsModeReq "Indicates the Deployable side step roof Access or the TR Override mode";
CM_ SG_ 177 SinglePointEntryReq "Menu item that turns Single Point Entry (SPE) ON/OFF via Instrument Pack";
CM_ SG_ 177 StealthModeUISwitch "Signal carrys information about whether the user has activated the stealth mode feature. Stealth mode is enabled and disabled internally to the FCDIM so 'activated' will imply that the feature is enabled AND the appropriate key has been pressed by the user.";
CM_ SG_ 177 TowBarFunctionReq "Requests a stow/deploy function from the towbar.";
CM_ SG_ 177 TowBarMeasureLoad "Indicates that the towbar measure the nose load";
CM_ SG_ 177 TrailerLightTestReq "Request trailer Light test Sequence";
CM_ SG_ 177 ValetReq "Turns Valet On/Off";
CM_ SG_ 177 WakeShutDownEnableReq "Indicates if WakeShutDown Sequence is selected by User";
CM_ SG_ 177 WalkAwayLockReq "This signal describes the request for Walk Away Locking feature";
CM_ SG_ 177 WindowsGlobalCloseReq "On/Off toggle on the Instrument Pack menu to turn Windows Global Close function on and off.

Logical Value = 0 - Windows Global Close disabled
Logical Value = 1 - Windows Global Close enabled";
CM_ SG_ 177 WindowsGlobalOpenReq "On/Off toggle on the Instrument Pack menu to turn Windows Global Open function on and off.

Logical Value = 0 - Windows Global Open disabled
Logical Value = 1 - Windows Global Open enabled";
CM_ SG_ 177 WiperWinterParkReq "Description of signal - This signal refers to the front wiper park position.  If set WiperWinterParkReq = 1 will result in the front wiper parking in an 'on-screen' position.  If WiperWinterParkReq = 0, will result in the front wiper parking in the 'off-screen' position.";
CM_ SG_ 108 IgnitionAuthDataControl "Authorise Ignition.

Byte 1 Definition: 
00=Idle, 
01=KeyStatus,
02 = Challenge Query 
03=Response, 
05=Enable Status.

The MSB of the signal must be written to the COM layer first (with an offset of zero in wr_bytes() ) and therefore transmitted on the bus first.
Similarly, subscribing modules will receive the MSB of the signal when they call rd_bytes(0).

E.g. wr_bytes(0) = published_signal_MSB;

Subscribed_Signal_MSB = rd_bytes(0);
";
CM_ SG_ 110 IgnitionAuthDataTarget "Ignition Authorisation.

Byte 1 Definition:
01 = Idle
03 = Challenge Response
04 = Error Status.

The MSB of the signal must be written to the COM layer first (with an offset of zero in wr_bytes() ) and therefore transmitted on the bus first.
Similarly, subscribing modules will receive the MSB of the signal when they call rd_bytes(0).

E.g. wr_bytes(0) = published_signal_MSB;

Subscribed_Signal_MSB = rd_bytes(0);
";
CM_ SG_ 318 AmbientLightValueIPC "This signal takes raw ambient light data from ambient light sensor located in instrument cluster and publishes it on the CAN Bus.
";
CM_ SG_ 318 DistanceToEmpty "Trip computer fuelled range function displayed value in kilometres only.
Used by:
1) Navigation function to compare journey length with available fuel and advise if there is
insufficient fuel for the journey.
2) VSC to calculate Combined Range (Fuel+EV).";
CM_ SG_ 318 InstAccEnable "This is used to inhibit cruise if the IC has not been programmed for ACC.";
CM_ SG_ 318 IPCAliveCnt "This signal is used by other ECU's to monitor the IPC. It will increment by 1 every 20ms. When the value of 15 is reached, it will reset to 0 on the next cycle";
CM_ SG_ 318 OdometerMasterValue "EuCD Signal.
Range: 0 - 16777214 (0-FFFFFEh)
Resolution: 1 KM
FFFFFFh = Invalid Data

                                                                         
NB: Signals greater than 16bits have to be of Signal Type (Bytes) as VSX does not support Unsigned signals >16bits.

The MSB of the signal must be written to the COM layer first (with an offset of zero in wr_bytes() ) and therefore transmitted on the bus first.
Similarly, subscribing modules will receive the MSB of the signal when they call rd_bytes(0).

E.g. wr_bytes(0) = published_signal_MSB;

Subscribed_Signal_MSB = rd_bytes(0);



                             
";
CM_ SG_ 318 SpeedometerUnits "Indicates the main speedometer units. Intended for use by cruise control, ACC, ASL & ISL instead of TripUnits to set the units for setspeed.";
CM_ SG_ 318 SPMModeRequest "Indicates SPM sensitivity level request from driver via IPC.";
CM_ SG_ 318 StgColLockGndEnableStatus "Steering Column Lock Ground Enable Status";
CM_ SG_ 318 TPMSLoadThresholdsReq "Signal to transmit the vehicle load condition to TPMM";
CM_ SG_ 318 TripUnits "Used to display the set speed in the same units as those selected for the trip computer - this is also going to be used for distance units";
CM_ SG_ 414 KVDecryptedMsg2 "Remote decrypted command from KVM.
Previously unused value 1101 now to be used.
Meaning for this value :- Return suspension to normal height.
No changes to any other signal definitions or parameters.

Bit 4 Button Status: 0 = Not held, 1 = Button Held (Jaguar documentation only)
";
CM_ SG_ 414 PECentralLockCmd2 "Passive Entry lock/unlock request
";
CM_ SG_ 414 PELockButtonReq2 "Notification of lock button request with conditions incorrect";
CM_ SG_ 414 PKeyId2 "Passive Key ID

Each bit is assigned to a Key as follows:

Bit 0 = KeyID1  (0000 0001)
Bit 1 = KeyID2  (0000 0010)
Bit 2 = KeyID3  (0000 0100)
Bit 3 = KeyID4  (0000 1000)
Bit 4 = KeyID5  (0001 0000)
Bit 5 = KeyID6  (0010 0000)
Bit 6 = KeyID7  (0100 0000)
Bit 7 = KeyID8  (1000 0000)

This enables more than one Key to be present at a time.";
CM_ SG_ 414 ProvUnlockDriverSide "This signal describes the request for provisional unlocking for the drivers side of the vehicle when an authorised key is present.";
CM_ SG_ 414 ProvUnlockPassSide "This signal describes the request for provisional unlocking for the passenger side of the vehicle when an authorised key is present.";
CM_ SG_ 1386 NMMessageLPDM "Network Management Signal. This signal contains Network Management Data. This data includes the DA (Destination Address), CF (Control Field) and up to 6 data bytes of user defined data.

The MSB of the signal must be written to the COM layer first (with an offset of zero in wr_bytes() ) and therefore transmitted on the bus first.
Similarly, subscribing modules will receive the MSB of the signal when they call rd_bytes(0).

E.g. wr_bytes(0) = published_signal_MSB;

Subscribed_Signal_MSB = rd_bytes(0);";
CM_ SG_ 944 LeftPowerDoorStatus "Status of the left power close door.";
CM_ SG_ 124 PATSDataControl "Engine Start Authorisation

Byte 1 definition > 00=Idle, 01=KeyStatus, 03=Response, 05=Terminate

The MSB of the signal must be written to the COM layer first (with an offset of zero in wr_bytes() ) and therefore transmitted on the bus first.
Similarly, subscribing modules will receive the MSB of the signal when they call rd_bytes(0).

E.g. wr_bytes(0) = published_signal_MSB;

Subscribed_Signal_MSB = rd_bytes(0);
";
CM_ SG_ 126 PATSDataTarget "Engine Start Authorisation

Byte 1 Definition > Idle=00, Challenge=02, SystemStatus=04

The MSB of the signal must be written to the COM layer first (with an offset of zero in wr_bytes() ) and therefore transmitted on the bus first.
Similarly, subscribing modules will receive the MSB of the signal when they call rd_bytes(0).

E.g. wr_bytes(0) = published_signal_MSB;

Subscribed_Signal_MSB = rd_bytes(0);
";
CM_ SG_ 132 BrakeSwitchStatus "Indicates status and fault condition of brake pedal.

";
CM_ SG_ 132 EMSAliveCounter "This counter forms part of a safety-related signal group.
It is incremented by the task which generates the data set used in the CRC calculation, and may be used to determine the health of the data generation task.
Refer to STJLR 18.036 for more detail.";
CM_ SG_ 132 EMSChecksum "This CRC shall be calculated in compliance with STJLR 18.036 Version 5.
The Data Segment Polynomial shall be constructed from the details
in the network configuration file.";
CM_ SG_ 132 EngineSpeed "Instantaneous Crank shaft speed, not corrected for flywheel tolerances and not smoothed.";
CM_ SG_ 132 EngineSpeedQF "Quality Factor for 'EngineSpeed'";
CM_ SG_ 132 MHStopStartStatus "L538:
Status of the Eco-Start Stop-Start Feature
";
CM_ SG_ 132 PowerPackStatus "Describes the state of the powerpack
";
CM_ SG_ 116 ChargDataWakeUpAllowed "This signal authorises the IMC to request a vehicle wake-up event whilst in PowerMode 0.";
CM_ SG_ 116 ChargePwrInterruptDisp "The flag to convey to the customer that charging is interrupted by Power Cut.";
CM_ SG_ 116 ChrgNotReadyByDepDisp "The flag to convey to the customer that charging will not be completed by Departure Time.";
CM_ SG_ 116 ChrgNotReadyReasonDisp "This message conveys to the customer the reason why the HV Battery is not ready (bulk charge OR full charged) by the departure time.";
CM_ SG_ 116 EVRangeGetMeHome "Predicted EV Range in Kilometres whilst in Get Me Home Driver Mode";
CM_ SG_ 116 EVRangeMilesDisp "Estimated EV range in miles";
CM_ SG_ 116 EVRangePredictStatus "The status of the EV Range prediction value.";
CM_ SG_ 116 EVRangeSelectedSOC "Predicted EV Range in Kilometres at the user selected SoC";
CM_ SG_ 116 EVRangeSelectSOCMiles "Predicted EV Range in Miles for the user selected SoC to charge the HV battery to.";
CM_ SG_ 239 AmbientAirPressure "Measured barometric pressure.

EuCD name. Previously called BarometricPressure.";
CM_ SG_ 239 AmbientAirPressureQF "Quality Factor for AmbientAirPressure

EuCD signal name.";
CM_ SG_ 239 AmbientTemp "Ambient air temperature.

EuCD signal encoding,
";
CM_ SG_ 239 AmbientTempQF "EuCD Unique Signal. Quality factor for the signal AmbientTemp.";
CM_ SG_ 239 EngineCoolantTemp "Measured engine coolant temperature.
Source is dependent on sensor location: engine coolant outlet or cylinder head temperature.";
CM_ SG_ 239 EngineCoolantTempQF "Quality Factor for 'EngineCoolantTemp'.";
CM_ SG_ 239 EngineOilTemp "Measured engine oil temperature.";
CM_ SG_ 239 EngineOilTempQF "Quality Factor for 'EngineOilTemp'";
CM_ SG_ 97 ClutchPedalAnalogPos "Clutch pedal position measured as analog value. The signal shall reflect the raw sensor value.
Covered by dependability spec A0265000 issue 2, mod 2.";
CM_ SG_ 97 ClutchPedalAnalogPosQF "QF for Clutch pedal position - Manaul transmission only";
CM_ SG_ 97 ClutchPedalPressed "Reflects the 'clutch slightly engaged status'. Depending on the configuration of clutch inputs in the system this is either when the 25% switch indicates 'pressed', or when the linearized clutch position sensor value exceeds a threshold, possible to calibrate (e.g. approximately 25%). The 'clutch pressed' output signal shall be reset to 'released' when either the 25% switch indicates 'released', or when the linearized clutch position sensor value sinks below another calibratable threshold (i.e. hysteresis).";
CM_ SG_ 97 ClutchPedalSwitch "Informs when the clutch is pressed, at least, to a specified position.The switch indicates fully depressed, >75%, clutch pedal";
CM_ SG_ 788 M1PassMirPosLeRiAct "Memory 1 Mirror position left/right";
CM_ SG_ 788 M1PassMirPosUpDwnAct "Memory 1 Mirror position up/down";
CM_ SG_ 788 M2PassMirPosLeRiAct "Memory 2 Mirror position left/right";
CM_ SG_ 788 M2PassMirPosUpDwnAct "Memory 2 Mirror position up/down";
CM_ SG_ 788 M3PassMirPosLeRiAct "Memory 3 Mirror position left/right";
CM_ SG_ 788 M3PassMirPosUpDwnAct "Memory 3 Mirror position up/down";
CM_ SG_ 788 PassMirPosLeRiAct "Mirror position left/right";
CM_ SG_ 788 PassMirPosUpDwnAct "Mirror position up/down";
CM_ SG_ 349 DZMPasLeftHmiOp "Used to convey BSM door mirror HMI state back to the BSM modules. Message Inactive indicates that the DZM has determined that its physical location is such that the status information is contained in the other signal (i.e. If driver left DZM then passenger left signal will contain 'message inactive')

DZMPasLeftHmiOp    3 bits
Type	Value	Scale	Offset	Interpretation
Logical Value	0	 	Message Inactive
Logical Value	1	 	HMI Fault
Logical Value	2	 	HMI not illuminated
Logical Value	3	 	HMI status LED illuminated
Logical Value	4	 	HMI alert LED illuminated
Logical Value	5-7                           Not used
";
CM_ SG_ 349 DZMPasRightHmiOp "Used to convey BSM door mirror HMI state back to the BSM modules. Message Inactive indicates that the DZM has determined that its physical location is such that the status information is contained in the other signal (i.e. If driver left DZM then passenger left signal will contain 'message inactive')

DZMPasRightHmiOp    3 bit 
Type	Value	Scale	Offset	Interpretation
Logical Value	0	 	 Message Inactive
Logical Value	1	 	 HMI Fault
Logical Value	2	 	 HMI not illuminated
Logical Value	3	 	 HMI status LED illuminated
Logical Value	4	 	 HMI alert LED illuminated
Logical Value	5-7                            Not used
";
CM_ SG_ 349 PassMirrorFoldStat "Provides feedback of the current folding status of the passenger wing mirror";
CM_ SG_ 349 PassngrDoorSCAStatus "A signal reporting the status of the Front Passengers Side Door Soft Close Actuator - SCA.";
CM_ SG_ 349 PDClawSwitchStatus "Front Passenger Side Door Latch Claw Switch Status";
CM_ SG_ 349 PDMReqBusAwake "Single bit message to report PDM requesting CAN keepawake.";
CM_ SG_ 349 PDMSetngAppl "Indicates If a request to change settings would be sucsesfull.";
CM_ SG_ 349 PDoorLatchStatus "Passenger Door Latch Status";
CM_ SG_ 349 PDPawlSwitchStatus "Front Passenger Side Door Latch Pawl Switch Status";
CM_ SG_ 349 PsgMirrorStatus "Provide folding status of passenger wing mirror";
CM_ SG_ 349 SeatMem1ButtonStatP "Signal from passenger door zone module to passenger seat module to detail memory 1 button status.

Logical value 0-Inactive/off
Logical value 1-Active/on";
CM_ SG_ 349 SeatMem2ButtonStatP "Signal from passenger door zone module to passenger seat module to detail memory 2 button status.

Logical value 0-Inactive/off
Logical value 1-Active/on";
CM_ SG_ 349 SeatMem3ButtonStatP "Signal from passenger door zone module to passenger seat module to detail memory 3 button status.

Logical value 0-Inactive/off
Logical value 1-Active/on";
CM_ SG_ 349 SeatMemLEDStatP "Signal from passenger door zone module to driver seat module to detail memory LED status.

Logical value 0-Inactive/off
Logical value 1-Active/on";
CM_ SG_ 349 SeatMemSetBtnStatP "Signal from passenger door zone module to driver seat module to detail memory set button status.

Logical value 0-Inactive/off
Logical value 1-Active/on";
CM_ SG_ 350 PassWindowPosition "Passenger Door Window Position";
CM_ SG_ 350 PDHandleStatus "'HandleStatus' is a signal to be broadcast from DDM, PDM, DRDM and PRDM. The RFA will subscribe to this sporadic CAN signal to ignore the PELock microswitch press as the handle is being deployed (SW containment for mechanical issue)on old passive entry trchnilogy and will be used as a diagnostic CAN signal on ePEPS technology.";
CM_ SG_ 350 PDLockSwitchPress "A Signal (from PDZM to BCM) to inform that the Front Passenger Door Central Lock Switch has been pressed.";
CM_ SG_ 350 PDUnlockSwitchPress "A Signal (from PDZM to BCM) to inform that the Front Passenger Door Central Unlock Switch has been pressed.";
CM_ SG_ 488 RockerSwitch1Req_b "Generic rocker switch pack - switch 1 request";
CM_ SG_ 488 RockerSwitch2Req_b "Generic rocker switch pack - switch 2 request";
CM_ SG_ 488 SunRoofFrBlindBtnReq_B "SunRoof Blind Button Press indication";
CM_ SG_ 488 TaskLightRelaxBtnReq_B "Signal to indicate Task Lighting
Intensity Button press";
CM_ SG_ 488 TaskLightWorkBtnReq_B "Signal to indicate Task Lighting Intensity Button Press";
CM_ SG_ 453 AudioMutePR "Audio Mute Passenger Rear";
CM_ SG_ 453 PRDMReqBusAwake "Single bit message to report PRDM requesting CAN keepawake.";
CM_ SG_ 453 RearPassDoorSCAStatus "A signal reporting the status of the REAR Drivers Side Door Soft Close Actuator - SCA.";
CM_ SG_ 453 RearPassREDHMIStatus "Rear exit detection HMI fault status fin rear passenger door";
CM_ SG_ 453 RearPDClawSwitchStatus "REAR Passengers Side Door Latch Claw Switch Status";
CM_ SG_ 453 RearPDPawlSwitchStatus "REAR Passenger Side Door Latch Pawl Switch Status";
CM_ SG_ 453 SeatMem1ButtonStatPR "Signal from door zone module to seat module to detail memory button status.";
CM_ SG_ 453 SeatMem2ButtonStatPR "Signal from door zone module to seat module to detail memory button status.
";
CM_ SG_ 453 SeatMem3ButtonStatPR "Signal from door zone module to seat module to detail memory button status.
";
CM_ SG_ 453 SeatMemLEDStatPR "Signal from door zone module to seat module to detail memory button status.
";
CM_ SG_ 453 SeatMemSetBtnStatPR "Signal from door zone module to seat module to detail memory button status.
";
CM_ SG_ 461 PSeatHghtDnReqPRDSP "Request front passesnger seat height Down from rear passenger seat";
CM_ SG_ 461 PSeatHghtUpReqPRDSP "Request front passenger seat height Up from rear passenger seat";
CM_ SG_ 461 PSeatInclineReqPRDSP "Request front passenger seat squab Incline from rear passenger seat";
CM_ SG_ 461 PSeatReclineReqPRDSP "Request front passenger seat squab Recline from rear passenger seat";
CM_ SG_ 461 PSeatSlideFWReqPRDSP "Request front passenger seat slide forward from rear passenger seat";
CM_ SG_ 461 PSeatSlideRWReqPRDSP "Request front passenger seat slide rearward from rear passenger seat";
CM_ SG_ 456 PassRearWindowPos "Information on position of rear Pasenger window";
CM_ SG_ 456 PRDChildLockStatus "EuCD Specific signal. Added to align with EuCD007.";
CM_ SG_ 456 PRDoorLatchStatus "Rear Passenger Door Latch Status";
CM_ SG_ 456 PRHandleStatus "'HandleStatus' is a signal to be broadcast from DDM, PDM, DRDM and PRDM. The RFA will subscribe to this sporadic CAN signal to ignore the PELock microswitch press as the handle is being deployed (SW containment for mechanical issue)on old passive entry trchnilogy and will be used as a diagnostic CAN signal on ePEPS technology.";
CM_ SG_ 456 RPDLockSwitchPress "A Signal (from PRDM to BCM) to inform that the Rear Passenger Door Central Lock Switch has been pressed.";
CM_ SG_ 456 RPDUnlockSwitchPress "A Signal (from RPDM to BCM) to inform that the Rear Passenger Door Central Unlock Switch has been pressed.";
CM_ SG_ 84 TorsionBarTorque "EPAS torque sensor value (absolute driver steering torque). This value shall be used by Tow Assist Feature to determine the driver intervention.";
CM_ SG_ 84 TorsionBarTorqueCS "This CRC shall be calculated in compliance with STJLR 18.036 Version 5.
The Data Segment Polynomial shall be constructed from the details in the network configuration file.";
CM_ SG_ 84 TorsionBarTorqueCtr "This counter forms part of a safety-related signal group.
It is incremented by the task which generates the data set used in the CRC calculation, and may be used to determine the health of the data generation task.
Refer to STJLR 18.036 for more detail.";
CM_ SG_ 84 TorsionBarTorqueSign "Indicates the direction of Torsion Bar Torque";
CM_ SG_ 211 PasSeatInhib1stRow "Inform of ability to use move request for passengers side 1st row";
CM_ SG_ 211 PasSeatInhib2ndRow "Inform of ability to use move request for passengers side 2nd row.";
CM_ SG_ 211 PasSeatInhib3rdRow "Inform of ability to use move request for passengers side 3rd row.";
CM_ SG_ 211 PasSeatPosition1stRow "Status of Passengers seat positon on 1st row";
CM_ SG_ 211 PasSeatPosition2ndRow "Status of Passengers seat positon on 2rd row";
CM_ SG_ 211 PasSeatPosition3rdRow "Status of Passengers seat positon on 3rd row";
CM_ SG_ 211 PassengerCancelSeat "To inform rear seats when the passenger seat is manually adjusted so rear seat movement can be cancelled (used for ISCM: Intelligent Seat Cargo Mode)";
CM_ SG_ 211 PassengerSeatMovement "Passenger Seat Movement.";
CM_ SG_ 211 PassSeatFootRestStat "Signal to inform front seat to deploy/retract footrest status";
CM_ SG_ 211 PassSeatMemStorStat "Signal to inform Touch Screen from PSM of a Memory Stored status";
CM_ SG_ 211 PassSeatMovement2ndRow "Signal to inform Infortainment of the status of the seat
";
CM_ SG_ 211 PassSeatMovement3rdRow "Signal to inform Infortainment of the status of the seat
";
CM_ SG_ 211 PassSeatMovementStat "Signal from PSM to Touch Screen and Rear Seats to inform passenger seat ststus";
CM_ SG_ 211 PassSeatMoveSelStat "Signal to inform Touch Screen from PSM of a Seat Selection status.";
CM_ SG_ 211 PassSeatMovmnt2ndRow "Signal to inform HLDF status of the seat";
CM_ SG_ 211 PassSeatMovmnt3rdRow "Signal to inform HLDF status of the seat";
CM_ SG_ 211 PassSeatOccupantStatus "Signal to indicate RLSM, RRSM & IMC/AMC of Passenger Seat Occupancy Status";
CM_ SG_ 211 Row1PassMovementINH "Signal to detect occupant / fold flat inhibited
Sent to Fold Flat switchpacks & touchscreen";
CM_ SG_ 211 Row2PassMovementINH "Signal to detect occupant / fold flat inhibited
Sent to Fold Flat switchpacks & touchscreen";
CM_ SG_ 211 Row3PassMovementINH "Signal to detect occupant / fold flat inhibited
Sent to Fold Flat switchpacks & touchscreen";
CM_ SG_ 211 RPSeatMovement "Signal from PSM to IMC to inform NGI touchscreen of Rear Left seat movement request during Advanced Chauffeur Function.";
CM_ SG_ 1368 NMmessagePSM "Network Management Signal. This signal contains Network Management Data. This data includes the DA (Destination Address), CF (Control Field) and up to 6 data bytes of user defined data (currently not used by Jaguar).

Description of station manager bit field detailing each application function (station manager function 1-16)
Bit 0 - Passenger Seat Movement
Bit 1 - Memory Recall
Bit 2 - Memory Save
Bit 3 - Cancel Memory Recall
Bit 4 to Bit 15 - Unused 

The MSB of the signal must be written to the COM layer first (with an offset of zero in wr_bytes() ) and therefore transmitted on the bus first.
Similarly, subscribing modules will receive the MSB of the signal when they call rd_bytes(0).

E.g. wr_bytes(0) = published_signal_MSB;

Subscribed_Signal_MSB = rd_bytes(0);

Refer 'Software Requirement Specification for CAN Network Management' (VCC doc no 31812308)

CAN ID:
X150/X250 - 0x528
GMRDB - 0x558";
CM_ SG_ 213 FoldAllSeatsReqPSM "Signal to inform DSM for a fold all request on 2nd & 3rd Row seats";
CM_ SG_ 213 R2ISCM60SeatCancelPSM "Signal to inform DSM, RearLeft 60 seat cancelled ISCM movement ";
CM_ SG_ 213 R2ISCM60SeatInSP1PSM "Signal to inform DSM, RearLeft 60 seat reached Safe position in ISCM movement ";
CM_ SG_ 213 R3RightSeatISCMCancPSM "Signal to inform DSM, Row3 Right seat cancelled ISCM movement ";
CM_ SG_ 213 R3RightSeatISCMReqPSM "Signal to inform DSM for Rear Left 60 seat ISCM movement 
";
CM_ SG_ 213 RockerSwitch1ReqPSM_a "Generic rocker switch pack - switch 1 request";
CM_ SG_ 213 RockerSwitch1ReqPSM_b "Generic rocker switch pack - switch 1 request";
CM_ SG_ 213 RockerSwitch2ReqPSM_a "Generic rocker switch pack - switch 2 request";
CM_ SG_ 213 RockerSwitch2ReqPSM_b "Generic rocker switch pack - switch 2 request";
CM_ SG_ 213 RRSeatMsgAvailFrInt "Intermediate Massage signals PSM to DSM";
CM_ SG_ 213 RRSeatMsgModStatFrInt "Intermediate Massage signals PSM to DSM";
CM_ SG_ 213 RRSeatMsgModStatInt "Intermediate Massage signals PSM to DSM";
CM_ SG_ 213 RRSeatMsgStatFrInt "Intermediate Massage signals PSM to DSM";
CM_ SG_ 213 UnFoldAllSeatsReqPSM "Signal to inform DSM for a unfold all request on 2nd & 3rd Row seats";
CM_ SG_ 1002 PassStPosCushAct "Passenger seat Position cushion";
CM_ SG_ 1002 PassStPosFrAftAct "Passenger seat Position Fore-Aft";
CM_ SG_ 1002 PassStPosHeadAct "Passenger seat Position head rest";
CM_ SG_ 1002 PassStPosRecAct "Passenger seat Position Recline";
CM_ SG_ 1002 PassStPosTiltAct "Passenger seat Position Tilt";
CM_ SG_ 1002 PassStPosUpDownAct "Passenger seat Position up-Down";
CM_ SG_ 1002 PassStSetngAppl "Passenger seat settings sucsesfully applied";
CM_ SG_ 1002 PSMReqBusAwake "Single bit message to report PSM requesting CAN keepawake.";
CM_ SG_ 1003 M1PassStPosCushAct "Passenger seat Position cushion";
CM_ SG_ 1003 M1PassStPosFrAftAct "Passenger seat Position Fore-Aft";
CM_ SG_ 1003 M1PassStPosHeadAct "Passenger seat Position head rest";
CM_ SG_ 1003 M1PassStPosRecAct "Passenger seat Position Recline";
CM_ SG_ 1003 M1PassStPosTiltAct "Passenger seat Position Tilt";
CM_ SG_ 1003 M1PassStPosUpDownAct "Passenger seat Position up-Down";
CM_ SG_ 1004 M2PassStPosCushAct "Passenger seat Position cushion";
CM_ SG_ 1004 M2PassStPosFrAftAct "Passenger seat Position Fore-Aft";
CM_ SG_ 1004 M2PassStPosHeadAct "Passenger seat Position head rest";
CM_ SG_ 1004 M2PassStPosRecAct "Passenger seat Position Recline";
CM_ SG_ 1004 M2PassStPosTiltAct "Passenger seat Position Tilt";
CM_ SG_ 1004 M2PassStPosUpDownAct "Passenger seat Position up-Down";
CM_ SG_ 1005 M3PassStPosCushAct "Passenger seat Position cushion";
CM_ SG_ 1005 M3PassStPosFrAftAct "Passenger seat Position Fore-Aft";
CM_ SG_ 1005 M3PassStPosHeadAct "Passenger seat Position head rest";
CM_ SG_ 1005 M3PassStPosRecAct "Passenger seat Position Recline";
CM_ SG_ 1005 M3PassStPosTiltAct "Passenger seat Position Tilt";
CM_ SG_ 1005 M3PassStPosUpDownAct "Passenger seat Position up-Down";
CM_ SG_ 191 CrashAirbagStatus "Driver and passenger airbag deployment status. This information is used to estimate the crash severity.

This signal is used for additional data about the crash event that has occurred when CrashStatusRCM has been set to crash.
The signal status reported here shall represent the status at the point of crash detection and shall be latched in that state for the period that CrashStatusRCM is set to crash.";
CM_ SG_ 191 CrashOccClassStatus "Front passenger seat occupancy status. This information is to be considered while estimating the crash severity.

This signal is used for additional data about the crash event that has occurred when CrashStatusRCM has been set to crash.
The signal status reported here shall represent the status at the point of crash detection and shall be latched in that state for the period that CrashStatusRCM is set to crash.";
CM_ SG_ 191 CrashPACOSSwitchState "'Passenger Airbag Cut Off Switch' state. This information is to be used while estimating the crash severity.

This signal is used for additional data about the crash event that has occurred when CrashStatusRCM has been set to crash.
The signal status reported here shall represent the status at the point of crash detection and shall be latched in that state for the period that CrashStatusRCM is set to crash.";
CM_ SG_ 191 CrashPretensionerStat "Driver's and front seat passenger's pretensioner state. This information is used in estimating the crash severity.

This signal is used for additional data about the crash event that has occurred when CrashStatusRCM has been set to crash.
The signal status reported here shall represent the status at the point of crash detection and shall be latched in that state for the period that CrashStatusRCM is set to crash.";
CM_ SG_ 191 CrashSeatBeltBcklState "Driver's and front seat passenger's seatbelt buckle state. This information is used to estimate the crash severity.

This signal is used for additional data about the crash event that has occurred when CrashStatusRCM has been set to crash.
The signal status reported here shall represent the status at the point of crash detection and shall be latched in that state for the period that CrashStatusRCM is set to crash.";
CM_ SG_ 191 CrashSeverityClass "Crash severity classification for frontal collisions. Set to 'No event' for rear/side collisions.

This signal is used for additional data about the crash event that has occurred when CrashStatusRCM has been set to crash
The signal status reported here shall represent the status at the point of crash detection and shall be latched in that state for the period that CrashStatusRCM is set to crash.";
CM_ SG_ 191 CrashSideAirbagStatus "Side airbags/curtains deployment status. This information is used to estimate the crash severity.

This signal is used for additional data about the crash event that has occurred when CrashStatusRCM has been set to crash.
The signal status reported here shall represent the status at the point of crash detection and shall be latched in that state for the period that CrashStatusRCM is set to crash.";
CM_ SG_ 191 CrashStatusPIE "This signal defines the crash status of the PIE.";
CM_ SG_ 191 CrashStatusRCM "This signal defines the crash status of the vehicle safety system.";
CM_ SG_ 191 CrashTypeFront "Signal indicates whether front crash has occurred or not. This is required to estimate the crash severity.
0 - No Front crash
1 - Front crash

This signal is used for additional data about the crash event that has occurred when CrashStatusRCM has been set to crash.
The signal status reported here shall represent the status at the point of crash detection and shall be latched in that state for the period that CrashStatusRCM is set to crash.";
CM_ SG_ 191 CrashTypeRear "Signal indicates whether rear crash has occurred or not. This is required to estimate the crash severity.
0 - No rear crash
1 - Rear crash

This signal is used for additional data about the crash event that has occurred when CrashStatusRCM has been set to crash.
The signal status reported here shall represent the status at the point of crash detection and shall be latched in that state for the period that CrashStatusRCM is set to crash.";
CM_ SG_ 191 CrashTypeRoll "Signal indicates whether vehicle rollover has occurred or not. This information is required to estimate the crash severity.

This signal is used for additional data about the crash event that has occurred when CrashStatusRCM has been set to crash.
The signal status reported here shall represent the status at the point of crash detection and shall be latched in that state for the period that CrashStatusRCM is set to crash.
";
CM_ SG_ 191 CrashTypeSide "Signal indicates whether side crash has occurred or not. This information is required to estimate the crash severity.
0 - No side crash
1 - Side crash 

This signal is used for additional data about the crash event that has occurred when CrashStatusRCM has been set to crash.
The signal status reported here shall represent the status at the point of crash detection and shall be latched in that state for the period that CrashStatusRCM is set to crash.";
CM_ SG_ 191 DrivSeatBeltBcklError "When the bit is set to a '1', a fault condition exists for the driver's seat belt buckle switch.";
CM_ SG_ 191 DrivSeatBeltBcklState "When the bit is set to a '1', the driver's seat belt buckle is latched.
This signal will be invalid and set to 1 (latched) during proveout and should not be used by subscriber until the valid state is established at 1sec post ignition on PM6";
CM_ SG_ 191 DrivSeatPositionError "Error status of driver seat track position switch.";
CM_ SG_ 191 DrivSeatPositionStatus "Status of driver seat track position switch.

This signal will be invalid and set to 1 (forward) during proveout and should not be used by subscribers until the valid state is established at 1sec post ignition on (PM6)";
CM_ SG_ 191 KeepNetInAfterRunRCM "An after-run function master shall send a CAN signal stating that the network is required during after-run. This allows the after-run manager to keep the OSEK nodes awake in order to create a stable ring and also allows supporting slaves to continue CAN transmission or supply ECU power.";
CM_ SG_ 191 PassSeatBeltBcklError "When the bit is set to a '1', a fault condition exists for the passenger seat belt buckle switch.";
CM_ SG_ 191 PassSeatBeltBcklState "When the bit is set to a '1', the passenger seat belt buckle is latched.";
CM_ SG_ 191 PassSeatPositionStatus "This signal will be invalid and set to 1 (forward) during proveout and should not be used by subscribers until the valid state is established at 1sec post ignition on (PM6)";
CM_ SG_ 74 A1 "Beschleunigung 1 (Lateral Acceleration 1). Positive value when vehicle is in a left hand turn. Units of m/sec2.

See IMU bus spec. for details
";
CM_ SG_ 74 A1_STAT "Status Beschleunigung 1 (Lateral Acceleration 1 Status)

Indicates the status of the Lateral Acceleration 1 signal, A1: 
XXX1 = sensor element not populated 
XX1X = signal faulty 
X1XX = sensor initialising 
1XXX = sensor channel not calibrated 

See IMU bus spec. for details";
CM_ SG_ 74 CLU_STAT "Clusterstatus (Sensor Status). NOT SUPPORTED. Unused signal from standard IMU sensor signal set.

See IMU bus spec. for details
";
CM_ SG_ 74 CRC1 "This CRC shall be calculated in compliance with STJLR 18.036 Version 5.
The Data Segment Polynomial shall be constructed from the details in the network configuration file.";
CM_ SG_ 74 MSG_CNT1 "This counter forms part of a safety-related signal group.
It is incremented by the task which generates the data set used in the CRC calculation, and may be used to determine the health of the data generation task.
Refer to STJLR 18.036 for more detail.";
CM_ SG_ 74 PSIP1 "Gierrate 1 (Yaw Rate 1). Positive value when vehicle is in a left hand turn. Units of Grad/sec, 1 Grad = 1/400th of a full circle.

See IMU bus spec. for details";
CM_ SG_ 74 PSIP1_STAT "Status Gierrate 1 (Yaw Rate 1 Status).

Indicates the status of the Yaw Rate 1 signal, PSIP1:
XXX1 = sensor element not populated
XX1X = signal faulty
X1XX = sensor initialising
1XXX = sensor channel not calibrated

See IMU bus spec. for details";
CM_ SG_ 76 A2 "Beschleunigung 2 (Longitudinal Acceleration). Positive value when vehicle is accelerating forwards. Units of m/sec2. 

See IMU bus spec. for details
";
CM_ SG_ 76 A2_STAT "Status Beschleunigung 2 (Longitudinal Acceleration Status).

Indicates the status of the Longitudinal Acceleration signal, A2: 
XXX1 = sensor element not populated 
XX1X = signal faulty 
X1XX = sensor initialising 
1XXX = sensor channel not calibrated 

See IMU bus spec. for details";
CM_ SG_ 76 CRC2 "This CRC shall be calculated in compliance with STJLR 18.036 Version 5.
The Data Segment Polynomial shall be constructed from the details in the network configuration file.";
CM_ SG_ 76 MSG_CNT2 "This counter forms part of a safety-related signal group.
It is incremented by the task which generates the data set used in the CRC calculation, and may be used to determine the health of the data generation task.
Refer to STJLR 18.036 for more detail.";
CM_ SG_ 76 PSIPP1 "Gierbeschleunigung 1 (Yaw Angular Acceleration 1). NOT SUPPORTED. Unused signal from standard IMU sensor signal set.

See IMU bus spec. for details";
CM_ SG_ 76 PSIPP1_STAT "Status Gierbeschleunigung 1 (Yaw Angular Acceleration 1 Status). 

Indicates the status of the Yaw Angular Acceleration 1 signal, PSIPP1: 
XXX1 = sensor element not populated 
XX1X = signal faulty 
X1XX = sensor initialising 
1XXX = sensor channel not calibrated 

Set to XXX1 as PSIPP1 is not supported.

See IMU bus spec. for details";
CM_ SG_ 1288 NMmessageKVM "Network Management Signal. This signal contains Network Management Data. This data includes the DA (Destination Address), CF (Control Field) and up to 6 data bytes of user defined data (currently not used by Jaguar). 

The MSB of the signal must be written to the COM layer first (with an offset of zero in wr_bytes() ) and therefore transmitted on the bus first.
Similarly, subscribing modules will receive the MSB of the signal when they call rd_bytes(0).

E.g. wr_bytes(0) = published_signal_MSB;

Subscribed_Signal_MSB = rd_bytes(0);

CAN ID:
X150/X250 - 0x508
GMRDB - 0x508

Description of station manager bit field detailing each application function (station manager functions)
Bit 0: LRN - Learn (FOB, TPMS, PK, etc)
Bit 1: ISM - Input Signal Manager
Bit 2: OSM - Output Signal Manager
Bit 3: ELM - E-Latch Manager
Bit 4: CMM - Configuration and Mode Manager
Bit 5: RMM - RFR Mode manager
Bit 6: DGN - Diagnostics
Bit 7: unused
Bit 8: ECI - EE Cache Interface
Bit 9: EDI - EE Direct Interface";
CM_ SG_ 330 DeactivatedPKeyID1 "All detected keys that are passivily deactivated. (Block 1)
This is also used for disabling other functions in the key.

EuCD signal";
CM_ SG_ 330 DeactivatedPKeyID2 "All detected keys that are passivily deactivated. (Block 2).
This is also used for disabling other functions in the key.

EuCD signal";
CM_ SG_ 330 KeyScanImminent "Periodic signal from RFA which will alert wireless chargers that a keyscan is imminent and they should turn off.";
CM_ SG_ 330 PEChargingInletLockCmd "Passive Entry unlock request for the Plug-In Charging Socket.";
CM_ SG_ 330 PLockSwStatusDD "Driver Door lock switch status";
CM_ SG_ 330 PLockSwStatusPD "(Front) Passenger Door lock switch status";
CM_ SG_ 330 PLockSwStatusRL "Rear left door lock switch status";
CM_ SG_ 330 PLockSwStatusRR "Rear right door lock switch status";
CM_ SG_ 330 PLockSwStatusTrunk "Trunk lock switch status";
CM_ SG_ 330 PUnlockSwStatusDD "Driver Door unlock switch status";
CM_ SG_ 330 PUnlockSwStatusPD "(Front) Passenger Door unlock switch status";
CM_ SG_ 330 PUnlockSwStatusRL "Rear Left door unlock switch status";
CM_ SG_ 330 PUnlockSwStatusRR "Rear Right door unlock switch status";
CM_ SG_ 330 PUnlockSwStatusTGlass "Tailgate glass unlock switch status";
CM_ SG_ 330 PUnlockSwStatusTrunk "Trunk unlock switch status";
CM_ SG_ 483 KVDecryptedMsg "Remote decrypted command from KVM.

Bit coded:
0000=IGNORE
0001=Lock
0010=Unlock
0011=Tailgate
0100=Approach Light
0101=Panic Alarm
0110=Security Check Req
0111=Change Lock Mode
Range 1000 - 1101 = Not used
1110 = Raise Suspension 
1111 = Lower Suspension 

Bit 4 Button Status: 0 = Not held, 1 = Button Held (Jaguar documentation only)
Bit 5-12 RSSI value
";
CM_ SG_ 483 PECentralLockCmd "Passive Entry lock/unlock request
";
CM_ SG_ 483 PELockButtonReq "Notification of lock button request with conditions incorrect";
CM_ SG_ 483 PKeyId "Passive Key ID

Each bit is assigned to a Key as follows:

Bit 0 = KeyID1  (0000 0001)
Bit 1 = KeyID2  (0000 0010)
Bit 2 = KeyID3  (0000 0100)
Bit 3 = KeyID4  (0000 1000)
Bit 4 = KeyID5  (0001 0000)
Bit 5 = KeyID6  (0010 0000)
Bit 6 = KeyID7  (0100 0000)
Bit 7 = KeyID8  (1000 0000)

This enables more than one Key to be present at a time.";
CM_ SG_ 483 PKeyIdScanArea "Reports where the passive key was found.

EuCD signal.

JLR note:
---------------
This signal should be grouped in RFA_Gp. However, it is not possible for EuCD to currently do this due to backward compatibility issues. For JLR 10MY it shall be ensured that this signal is written to at the same time as RFA_Gp and that this signal is packaged in the same CAN frame as RFA_Gp.";
CM_ SG_ 483 PKeyIdsInAreaReported "Reports how many keys that have been found for each key search.

EuCD signal.

JLR note:
---------------
This signal should be grouped in RFA_Gp. However, it is not possible for EuCD to currently do this due to backward compatibility issues. For JLR 10MY it shall be ensured that this signal is written to at the same time as RFA_Gp and that this signal is packaged in the same CAN frame as RFA_Gp.";
CM_ SG_ 484 PEPullSwitchStatus "KVM Reports to Body Systems Particular Door Handle Pulled when Vehicle Unlocked.";
CM_ SG_ 484 PKBattStatus "Indicates the status of the smart key internal battery.
***1 Bit Unsigned Type***";
CM_ SG_ 484 PkeyScanComp "Shows if key scanning is complete.";
CM_ SG_ 484 PKeyScanID "Shows which keys are present in
the vehicle.

Bitfield: (0 = Not present,
1 = Present)
Bit 0 -> Key 1
...
Bit 7 -> Key 8";
CM_ SG_ 484 PKeyWarningInd "Passive Key Warning";
CM_ SG_ 484 PLockRequestDD "Driver Door lock request with a valid PKeyID";
CM_ SG_ 484 PLockRequestPD "Passenger Door lock request with a valid PKeyID";
CM_ SG_ 484 PLockRequestRL "Rear Left door lock request with a valid PKeyID";
CM_ SG_ 484 PLockRequestRR "Rear Right door lock request with a valid PKeyID";
CM_ SG_ 484 PLockRequestTrunk "Trunk lock request with a valid PKeyID";
CM_ SG_ 484 PUnlockRequestDD "Driver Door unlock request with a valid PKeyID";
CM_ SG_ 484 PUnlockRequestPD "Passenger Door unlock request with a valid PKeyID";
CM_ SG_ 484 PUnlockRequestRL "Rear Left door unlock request with a valid PKeyID";
CM_ SG_ 484 PUnlockRequestRR "Rear Right door unlock request with a valid PKeyID";
CM_ SG_ 484 PUnlockRequestTGlass "Tailgate Glass unlock request with a valid PKeyID";
CM_ SG_ 484 PUnlockRequestTrunk "Trunk unlock request with a valid PKeyID";
CM_ SG_ 486 ImmoAuthPKeyMainResp "Passive Control Response

The MSB of the signal must be written to the COM layer first (with an offset of zero in wr_bytes() ) and therefore transmitted on the bus first.
Similarly, subscribing modules will receive the MSB of the signal when they call rd_bytes(0).

E.g. wr_bytes(0) = published_signal_MSB;

Subscribed_Signal_MSB = rd_bytes(0);
";
CM_ SG_ 486 ImmoPKeyApproved "Passive Key Approved";
CM_ SG_ 1318 NMmessageRGTM "Network Management Signal. This signal contains Network Management Data. This data includes the DA (Destination Address), CF (Control Field) and up to 6 data bytes of user defined data. 

The MSB of the signal must be written to the COM layer first (with an offset of zero in wr_bytes() ) and therefore transmitted on the bus first.
Similarly, subscribing modules will receive the MSB of the signal when they call rd_bytes(0).

E.g. wr_bytes(0) = published_signal_MSB;

Subscribed_Signal_MSB = rd_bytes(0);
";
CM_ SG_ 480 PCUStatus "Signal from RGTM UPPER reporting the status of  the Power Cinch Unit/Soft Close Unit.";
CM_ SG_ 480 POTSecondaryLatchSt "Signal reporting the (RAW) Upper Tailgate secondary latch status";
CM_ SG_ 480 PowerTailgateStatus "PowerTailgateStatus - Status of power boot/tailgate";
CM_ SG_ 480 PwrTGCloseInProg "Msg from RGTM to BCM indicating that a Power Close (including post power close soft close operation)is in progress/has occurred - to distinguish whether latch/gate close was due to Power Close operation or manual/override operation.";
CM_ SG_ 480 UpperTailgateCloseStat "A message from RGTM Upper telling RGTMB Lower the whether Upper gate is OK to close.
";
CM_ SG_ 480 UpperTailgateOpenStat "A message from RGTM Upper telling RGTMB Lower the whether the Upper gate is OK to open.";
CM_ SG_ 480 UpperTailGatePosn "A signal reporting upper tailgate position ";
CM_ SG_ 430 PKExtScanReqTailgate "Tailgate Module requests a scan of the exterior rear.";
CM_ SG_ 430 POTCompleteCloseReq "Signal reporting a complete close request";
CM_ SG_ 430 UpperPOTailgatePinch "Signal indicating whether a pinch condition has occurred on the power tailgate";
CM_ SG_ 430 UpperPwrTGObjectDetect "A message from RGTM Upper telling RGTMB Lower that an ObjectDetect condition has occurred on the Upper tailgate.

Encoding:
0 - ObjectDetect Inactive
1 - ObjectDetect Active - Stop movement";
CM_ SG_ 430 UpperTGateMislockWng "A signal from the RGTM Upper to BCM to warn of a mislock error";
CM_ SG_ 1402 NMmessageRGTMB "Network Management Signal. This signal contains Network Management Data. This data includes the DA (Destination Address), CF (Control Field) and up to 6 data bytes of user defined data. 

The MSB of the signal must be written to the COM layer first (with an offset of zero in wr_bytes() ) and therefore transmitted on the bus first.
Similarly, subscribing modules will receive the MSB of the signal when they call rd_bytes(0).

E.g. wr_bytes(0) = published_signal_MSB;

Subscribed_Signal_MSB = rd_bytes(0);
";
CM_ SG_ 611 LowerTailGatePosn "A signal reporting Lower tailgate position ";
CM_ SG_ 611 LwrTailgateCloseStat "A message from RGTMB Lower telling RGTM Upper the whether the Lower gate is OK to close.";
CM_ SG_ 611 LwrTailgateOpenStat "A message from RGTMB Lower telling RGTM Upper the whether the Lower gate is OK to open.";
CM_ SG_ 611 PCUStatusLwrLHS "Signal reporting the status of Lower LHS PCU Power Cinch Unit/Soft Close Actuator";
CM_ SG_ 611 PCUStatusLwrRHS "Signal reporting the status of lower RHS PCU Power Cinch Unit //Soft Close Actuator";
CM_ SG_ 611 POTSecLatchStatLwrLHS "Signal reporting the (RAW) Lower LHS Tailgate Latch Status(Secondary)";
CM_ SG_ 611 POTSecLatchStatLwrRHS "Signal reporting the (RAW) Lower RHS Tailgate Latch Status(Secondary)";
CM_ SG_ 611 PowerTailgateStatusLwr "Signal to report on the status of the lower tailgate";
CM_ SG_ 431 LowerPOTailgatePinch "Signal indicating whether a pinch condition has occurred on the lower tailgate";
CM_ SG_ 431 LowerPwrTGObjectDetect "A message from RGTMB Lower telling RGTM Upper that an ObjectDetect condition has occurred on the lower tailgate.

0 - ObjectDetect Inactive
1 - ObjectDetect Active - Stop movement";
CM_ SG_ 431 LwrTrunkReleaseCmd "Request from RGTMB to BCM to drive lower tailgate latch(es)";
CM_ SG_ 1306 NMmessageRLSM "Network Management Signal. This signal contains Network Management Data. This data includes the DA (Destination Address), CF (Control Field) and up to 6 data bytes of user defined data (currently not used by Jaguar). 

Description of station manager bit field detailing each application function (station manager function 1-16)
Bit 0 - Rear Left Seat Movement
Bit 1 - Memory Recall
Bit 2 - Memory Save
Bit 3 - Cancel Memory Recall
Bit 4 to Bit 15 - Unused

The MSB of the signal must be written to the COM layer first (with an offset of zero in wr_bytes() ) and therefore transmitted on the bus first.
Similarly, subscribing modules will receive the MSB of the signal when they call rd_bytes(0).

E.g. wr_bytes(0) = published_signal_MSB;

Subscribed_Signal_MSB = rd_bytes(0);

Refer 'Software Requirement Specification for CAN Network Management' (VCC doc no 31812308)

CAN ID:
X150/X250 - 0x528
GMRDB - 0x558";
CM_ SG_ 389 PassSeatHghtDownReqRL "Request front passesnger seat height down from rear left passenger seat";
CM_ SG_ 389 PassSeatHghtUpReqRL "Request front passesnger seat height down from rear right passenger seat";
CM_ SG_ 389 PassSeatHRestAftReqRL "Signal from RRSM to PSM to request front Passenger seat Head Rest Aft Position";
CM_ SG_ 389 PassSeatHRestDwnReqRL "Signal from RLSM to PSM to request front Passenger seat Head Rest Down";
CM_ SG_ 389 PassSeatHRestForeReqRL "Signal from RLSM to PSM to request front Passenger seat Head Rest Fore Position";
CM_ SG_ 389 PassSeatHRestUpReqRL "Signal from RLSM to PSM to request front Passenger seat Head Rest UP";
CM_ SG_ 389 PassSeatInclineReqRL "Request front passesnger seat incline from rear left passenger seat";
CM_ SG_ 389 PassSeatMemClrReqRL "Signal to inform PSM from RLSM to Clear stored Memory Settings in PSM with respect to rear seat";
CM_ SG_ 389 PassSeatMemLoadReqRL "Signal to inform PSM from RLSM to load PSM with respect to rear seat";
CM_ SG_ 389 PassSeatMemStrReqRL "Signal to inform PSM from RLSM to store locally in PSM with respect to rear seat";
CM_ SG_ 389 PassSeatMoveReqRL "Signal from RLSM to PSM to be sent out when seat is unoccupied";
CM_ SG_ 389 PassSeatReclineReqRL "Request front passenger seat recline from rear left passenger seat";
CM_ SG_ 389 PassSeatSlideAftReqRL "Request front passenger seat slide back from rear left passenger seat";
CM_ SG_ 389 PassSeatSlideForeReqRL "Request front passenger seat slide forward from rear left passenger seat";
CM_ SG_ 389 PSARequestRL "Passanger seat away request and direction";
CM_ SG_ 389 RCntrSeatMoveSelStat "Signal to inform Touch Screen from RLSM of a Seat Selection status.";
CM_ SG_ 389 RCntrSeatMovmentStat "Signal to inform HLDF status of the seat";
CM_ SG_ 389 RCntrSeatUpperLidStat "Signal from RLSM to inform Upper Lid status";
CM_ SG_ 389 RearLeftCancelSeat "Rear Left Seat module will send out a RearLeftCancelSeat signal to the Calf Rest if a rear seat switch pack button is pressed while a memory recall is performed.";
CM_ SG_ 389 RearSeatFoldFlatReqRL "Signal required 'fold flat rear seat' to inform front PSM that there is a rear fold flat request so as to move out of the clash zone";
CM_ SG_ 389 RLSMSeatMovement "Indication of Rear Left seat movement.";
CM_ SG_ 389 RMSeatInhib2ndRow "Inform of ability to use move request for rear middle seat 2nd row";
CM_ SG_ 390 RLeftTableDeployed "RLeftTableDeployed signal is required for a rear business class table in the rear console, this signal will broadcast to the front seat modules to make the DSM & PSM aware of if rear table is deployed or not deployed";
CM_ SG_ 390 RLSeatCalfRestStat "Signal to inform front seats & HVAC of calf rest position";
CM_ SG_ 390 RLSeatFoldFlatReq "Signal to inform front seats to move out of the clash region whenever the 'Rear Fold Flat' is activated. ";
CM_ SG_ 390 RLSeatFootRestReq "Signal to inform front seat to deploy/retract footrest";
CM_ SG_ 390 RLSeatInhib2ndRow "Inform of ability to use move request for rear left seat 2nd row";
CM_ SG_ 390 RLSeatMasgIntStat "Rear Left Seat: Current Massage Intensity Status";
CM_ SG_ 390 RLSeatMasgLocStat "Rear Left Seat: Current Massage Location Status";
CM_ SG_ 390 RLSeatMasgModeStatFr "Signal transmitted by the massage module to the FCDIM to confirm the active massage mode of the seat";
CM_ SG_ 390 RLSeatMasgProgStat "Rear Left Seat: Current Massage Programme Status";
CM_ SG_ 390 RLSeatMasgStatFr "Signal transmitted by the massage module to the FCDIM to confirm the massage seat status on/off";
CM_ SG_ 390 RLSeatMassageModeStat "Rear Left seat massage status indicator";
CM_ SG_ 390 RLSeatMemLoadStat "Signal to inform Touch Screen from RLSM of a Memory Recall status";
CM_ SG_ 390 RLSeatMemStorStat "Signal to inform Touch Screen from RLSM of a Memory Stored status";
CM_ SG_ 390 RLSeatMovementStat "Signal to inform HLDF status of the seat";
CM_ SG_ 390 RLSeatMoveSelStat "Signal to inform Touch Screen from RLSM of a Seat Selection status ";
CM_ SG_ 390 RLSeatMsgAvailFr "Signal transmitted by the Rear SCMG to  FCDIM to indicate massage availability";
CM_ SG_ 390 RLSeatOccupancyStat "Signal from rear left seat module to inform PSM of rear seat occupant status";
CM_ SG_ 1327 NMMessageRPDM "Network Management Signal. This signal contains Network Management Data. This data includes the DA (Destination Address), CF (Control Field) and up to 6 data bytes of user defined data.

The MSB of the signal must be written to the COM layer first (with an offset of zero in wr_bytes() ) and therefore transmitted on the bus first.
Similarly, subscribing modules will receive the MSB of the signal when they call rd_bytes(0).

E.g. wr_bytes(0) = published_signal_MSB;

Subscribed_Signal_MSB = rd_bytes(0);";
CM_ SG_ 530 RightPowerDoorStatus "Status of the right power close door.";
CM_ SG_ 1385 NMmessageRRSM "Network Management Signal. This signal contains Network Management Data. This data includes the DA (Destination Address), CF (Control Field) and up to 6 data bytes of user defined data (currently not used by Jaguar). 

Description of station manager bit field detailing each application function (station manager function 1-16)
Bit 0 - Rear Right Seat Movement
Bit 1 - Memory Recall
Bit 2 - Memory Save
Bit 3 - Cancel Memory Recall
Bit 4 to Bit 15 - Unused

The MSB of the signal must be written to the COM layer first (with an offset of zero in wr_bytes() ) and therefore transmitted on the bus first.
Similarly, subscribing modules will receive the MSB of the signal when they call rd_bytes(0).

E.g. wr_bytes(0) = published_signal_MSB;

Subscribed_Signal_MSB = rd_bytes(0);

Refer 'Software Requirement Specification for CAN Network Management' (VCC doc no 31812308)

CAN ID:
X150/X250 - 0x528
GMRDB - 0x558";
CM_ SG_ 682 CupHolderReq "Signal to inform Rear Left seat module of cupholder switch request";
CM_ SG_ 682 PassSeatHghtDownReqRR "Request front passesnger seat height down from rear right passenger seat";
CM_ SG_ 682 PassSeatHghtUpReqRR "Request front passesnger seat height down from rear right passenger seat";
CM_ SG_ 682 PassSeatHRestAftReqRR "Signal from RLSM to PSM to request front Passenger seat Head Rest Aft Position";
CM_ SG_ 682 PassSeatHRestDwnReqRR "Signal from RRSM to PSM to request front Passenger seat Head Rest Down";
CM_ SG_ 682 PassSeatHRestForeReqRR "Signal from RRSM to PSM to request front Passenger seat Head Rest Fore Position";
CM_ SG_ 682 PassSeatHRestUpReqRR "Signal from RRSM to PSM to request front Passenger seat Head Rest UP";
CM_ SG_ 682 PassSeatInclineReqRR "Request front passesnger seat incline from rear right passenger seat";
CM_ SG_ 682 PassSeatMemLoadReqRR "Signal to inform PSM from RRSM to load PSM with respect to rear seat";
CM_ SG_ 682 PassSeatMemStrReqRR "Signal to inform PSM from RRSM to store locally in PSM with respect to rear seat";
CM_ SG_ 682 PassSeatMoveReqRR "Signal from RRSM to PSM to be sent out when seat is unoccupied";
CM_ SG_ 682 PassSeatReclineReqRR "Request front passenger seat recline from rear right passenger seat";
CM_ SG_ 682 PassSeatSlideAftReqRR "Request front passenger seat slide back from rear right passenger seat";
CM_ SG_ 682 PassSeatSlideForeReqRR "Request front passenger seat slide forward from rear right passenger seat";
CM_ SG_ 682 PSARequestRR "Passanger seat away request and direction";
CM_ SG_ 682 RearLeftFoldSwStat "Signal from Rear Right Module to Rear Left Module to inform Fold Switch Status";
CM_ SG_ 682 RearLeftUnfoldSwStat "Signal from Rear Right Module to Rear Left Module to inform Unfold Switch Status";
CM_ SG_ 682 RearRightCancelSeat "Rear Right Seat module will send out a RearRightCancelSeat signal to the Calf Rest if a rear seat switch pack button is pressed while a memory recall is performed.";
CM_ SG_ 682 RearSeatFoldFlatReqRR "Signal required 'fold flat rear seat' to inform front PSM that there is a rear fold flat request so as to move out of the clash zone
";
CM_ SG_ 682 RRightTableDeployed "RRightTableDeployed signal is required for a rear business class table in the rear console, this signal will broadcast to the front seat modules to make the DSM & PSM aware of if rear table is deployed or not deployed";
CM_ SG_ 682 RRSeatCalfRestStat "Signal to inform front seats & HVAC of calf rest position";
CM_ SG_ 682 RRSeatFoldFlatReq "Signal to inform front seats to move out of the clash region whenever the 'Rear Fold Flat' is activated. ";
CM_ SG_ 682 RRSeatFootRestReq "Signal to inform front seat to deploy/retract footrest";
CM_ SG_ 682 RRSeatInhib2ndRow "Inform of ability to use move request for rear right seat 2nd row";
CM_ SG_ 682 RRSeatMasgAvailFr "Signal transmitted by the Rear SCMH to  FCDIM to indicate massage availability";
CM_ SG_ 682 RRSeatMasgIntStat "Rear Right Seat: Current Massage Intensity Status";
CM_ SG_ 682 RRSeatMasgLocStat "Rear Right Seat: Current Massage Location Status";
CM_ SG_ 682 RRSeatMasgModeStatFr "Signal transmitted by the massage module to the FCDIM to confirm the active massage mode of the seat";
CM_ SG_ 682 RRSeatMasgProgStat "Rear Right Seat: Current Massage Programme Status";
CM_ SG_ 682 RRSeatMasgStatFr "Signal transmitted by the massage module to the FCDIM to confirm the massage seat status on/off";
CM_ SG_ 682 RRSeatMemLoadStat "Signal to inform Touch Screen from RLSM of a Memory Recall status";
CM_ SG_ 682 RRSeatMemStorStat "Signal to inform Touch Screen from RLSM of a Memory Stored status";
CM_ SG_ 682 RRSeatMovementStat "Signal to inform HLDF status of the seat";
CM_ SG_ 682 RRSeatMoveSelStat "Signal to inform Touch Screen from RRSM of a Seat Selection status";
CM_ SG_ 682 RRSeatOccupancyStat "Signal from rear right seat module to inform PSM of rear seat occupant status.";
CM_ SG_ 682 RRSMSeatMovement "Indication of Rear Right seat movement.";
CM_ SG_ 682 SkiHatchStat "Signal to inform touch screen of Ski Hatch status";
CM_ SG_ 682 SkiHatchSwitchStat "Signal from Rear Right Module to Rear Left Module to inform Ski-Hatch Switch Status";
CM_ SG_ 86 SteeringWheelAngle "This signal provides the a measurement of the steering wheel position. The angle is measured as referenced from a 0 degree straight-ahead position. 

- If the steering wheel is rotated clockwise, the measurement decreases.
- If the steering wheel is rotated anti-clockwise, the measurement increases.

On certain vehicle lines fitted with relative angle sensors, the straight-ahead position may have to be 'learned' in each ignition cycle after a brief period of driving. On vehicles fitted with absolute angle sensors, this is not the case.

Depending on the vehicle electrical architecture, the signal may be sourced via the ABS module or direct from the SASM.

The MSB of the signal must be written to the COM layer first (with an offset of zero in wr_bytes() ) and therefore transmitted on the bus first.
Similarly, subscribing modules will receive the MSB of the signal when they call rd_bytes(0).

E.g. wr_bytes(0) = published_signal_MSB;

Subscribed_Signal_MSB = rd_bytes(0);";
CM_ SG_ 86 SteeringWheelAngleCS "This CRC shall be calculated in compliance with STJLR 18.036 Version 5.
The Data Segment Polynomial shall be constructed from the details in the network configuration file.";
CM_ SG_ 86 SteeringWheelAngleSpeed "Steering Wheel Rotation Speed.
";
CM_ SG_ 86 SteeringWheelAngleStatus "2-bit signal relating to SteeringWheelAngleUnsigned. This flag indicates progress with the Learn Centre Algorithm. This signal will indicate a value of 1 (Centre not learned) at the start of every ignition cycle before the algorithm has had a chance to run. As the algorithm runs to completion, the value will increment to 3. Certain exceptional conditions may cause the algorithm to re-run mid-igntion cycle. A fault with the sensor is indicated by a value of 0.
";
CM_ SG_ 86 SteeringWheelAngMsgCnt "This counter forms part of a safety-related signal group.
It is incremented by the task which generates the data set used in the CRC calculation, and may be used to determine the health of the data generation task.
Refer to STJLR 18.036 for more detail.";
CM_ SG_ 86 SteeringWheelRotDir "This signal indicates the direction of steering wheel rotation. ";
CM_ SG_ 379 PassSeatMasgIntStat "Signal transmitted by the massage module to HLDF to confirm the active massage intensity on the front passenger seat.";
CM_ SG_ 379 PassSeatMasgLocStat "Passenger Seat: Current Massage Location Status";
CM_ SG_ 379 PassSeatMasgProgStat "Passenger Seat: Current Massage Programme Status";
CM_ SG_ 379 PassSeatMassageModeStat "Passenger seat massage status indicator";
CM_ SG_ 379 PassSeatMassageStat "The status of the passenger's seat massage system.";
CM_ SG_ 379 PassSeatMsgAvail "States whether the passengers' seat massage system is available";
CM_ SG_ 503 ActivateBlower "Front Blower Relay Activation";
CM_ SG_ 503 AIR_LowerSwitchStatus "This signal denotes the status of the Air Suspension Lower Switch. The signal is used by the body controller for PLIP configuration.";
CM_ SG_ 503 AIR_RaiseSwitchStatus "This signal denotes the status of the Air Suspension Raise switch. It is used by the body controller for PLIP configuration.";
CM_ SG_ 503 BSCMBrakeLightRequest "To request brake light activation for automatic braking functions in the BSCM
";
CM_ SG_ 503 EmergencyBrakingStatus "To enable the visible warning signal to warn other drivers that your vehicle is performing an emergency braking manoeuvre. This can be for example the hazard warning lights or flashing brake lights. These are turned on when the Emergency Braking Light (EBL) function is triggered, the triggering depending on the vehicle speed, deceleration and ABS activation.";
CM_ SG_ 503 FirstGearManual "Flag signal that indicates if the first gear is engaged or not. Manual transmissions only.";
CM_ SG_ 503 GSAPositionDisplay "Message used by IPK and ETS to display selected gear information.TCM will set multiple bits when e.g in Drive 5th gear and in Sport. The Signal TCMDrivingModeDisplay can be used for gear 1-8 display when in manual mode.

Init: Blank ETS display and Blank IPK display. Bit 14 and 15 set to 1, all other bits set to 0 (49152 decimal)

Bits 0 - 5: Gear Selection
000000 = Auto selection
000001 = 1st Gear
000010 = 2nd Gear
000100 = 3rd Gear
001000 = 4th Gear
010000 = 5th Gear
100000 = 6th Gear
100001 = 7th Gear
100010 = 8th Gear
100100 = 9th Gear

Bits 6 - 11: Gear Mode
000001 = Fault
000010 = Park Position
000100 = Reverse Position
001000 = Neutral Position
010000 = Drive Position
100000 = Sport Position

Bits 12 - 13: Flash Display
x1 = FLASH ETS Display
1x = FLASH IPK Display

Bits 14 - 15: Blank Display
x1 = Blank ETS Display
1x = Blank IPK Display";
CM_ SG_ 503 GSAPosStatus "Actual PRNDS Position of the vehicle Transmission (simplified version of GSAPositionDisplay)";
CM_ SG_ 503 LSMMirrorFoldReq "Request to remotely fold or unfold the wing mirrors to support the remote low speed manoeuvering features.";
CM_ SG_ 503 MHLampStatus "Micro Hybrid Lamp used to indicate if the MH system is enabled or disabled";
CM_ SG_ 503 WakeNetForPreRunHVAC "CAN signal stating if the network is required for Pre-Run.

Description of bit field detailing each application function to be stored in the DID (After-Run Function 1- 16):
Pre Run Function 1 (Bit 0) - 
HVAC gets external temperature prior to a fuel burn event
PCM obtains fuel burn information (no. of burns, burns times etc)following a fuel burn event.";
CM_ SG_ 504 CrankRelayStatus "This signal is set true when the vehicle 12v system (as used by the various modules) will suffer a voltage dip due to a cold cranking event. 

Non-EuCD name retained for compatibility.  Use EngineState for new developments.
";
CM_ SG_ 504 EngineRunningStatus "'IF PowerPackStatus = RunningRunning OR RunningStandby OR RunningStartingInProgress
THEN EngineRunningStatus = 1 [Engine running]
ELSE EngineRunningStatus = 0 [Engine not running]'

";
CM_ SG_ 504 GearPosActual "Actual gear position.
Note - this signal is not ASIL rated.
If in gliding this signal will read the gear that the transmission would have been in if gliding was not active.

Info: The EV Drive encoding will only be used on powertrain architectures where there is a transmission that doesn't control torque to all the wheels. e.g. D8 PHEV where the transmission controls torque the wheels on the front axle only.";
CM_ SG_ 504 LaserStatus "Laser status";
CM_ SG_ 504 LSMDirIndReq "Request for direction indicator lights to be turned on during low speed manoeuvres";
CM_ SG_ 504 LSMExteriorLightsReq "Request for vehicle exterior light activation";
CM_ SG_ 761 AmbTempImpr "An improved version of the measured ambient temperature. range -57..+70 degree C";
CM_ SG_ 761 CDiffRangeActual "Transfer box range signal.The 'Undefined' state indicates that Range change is in progress


";
CM_ SG_ 761 DefrosterReq "Bit 1 = RearDefroster
Bit 2 = Mirrors
Bit 3  = FrontDefroster

EATC switch sets all bits!
";
CM_ SG_ 761 EPBBrakeLightReq "L538:
EPB activation of rear brake lamps during dynamic EPB braking";
CM_ SG_ 761 HWJLoadStatus "Status of the heated washer jet load for ELM

0= HWJ off
1= HWJ on";
CM_ SG_ 761 NeutralManual "Signal to indicate when manual transmission is in neutral";
CM_ SG_ 761 OuterMirrorDefCmd "Heated Mirror Command.";
CM_ SG_ 761 ParkClimateMode "Operating mode of the Fuel Burning Heater";
CM_ SG_ 761 RestHeatStatus "Status of HVAC Rest Heating

0 = Rest Heating Off
1 = Rest Heating On";
CM_ SG_ 761 RLSeatMassageModeReq "Rear Left seat massage mode request signal";
CM_ SG_ 761 RRSeatMassageModeReq "Rear Right seat massage mode request signal";
CM_ SG_ 761 WaterPumpReq "Request to turn on  (or off) the extra waterpump";
CM_ SG_ 197 ABRCTAEventStatus "ABRCTA Event Status used to inform the driver that an ABRCTA event has been actuated.";
CM_ SG_ 197 ABRCTAMonitoringMode "Indicateds the status of the ABRCTA system";
CM_ SG_ 197 ABRCTASystemState "Reports the overall system state of the Autobrake RCTA feature.";
CM_ SG_ 197 ARAAlertLeft "Left advanced reversing aid - alert";
CM_ SG_ 197 AVCMLeftTargetDet "Adjacent Vehicle Collision Mitigation (AVCM) system has detected an object within the left side of the host vehicle alert zone or a vehicle is fast approaching from behind and in the adjacent left lane.";
CM_ SG_ 197 BSMLeftAlert "An object of interest has been detected within the alert zone on the left side of the vehicle and the driver should be alerted that there is an object present.";
CM_ SG_ 197 BSMLeftBlocked "This is based on radar measurements made by the left sensor that indicates that there is something directly in front of the sensor (within a few centimetres) that prevents its ability to see objects nearby.";
CM_ SG_ 197 BSMLeftCVWAlert "Cross Vehicle Warning Alert - Left.";
CM_ SG_ 197 BSMLeftSensorState "Indicates the overall mode of the Left Blind Spot Monitoring sensor as a result of CAN inputs and test results.";
CM_ SG_ 197 BSMLeftServiceRequired "The left side sensor has detected an error and is informing the driver that the BSM system is not working properly.";
CM_ SG_ 197 BSMLeftUnavailable "The left side sensor is currently unavailable";
CM_ SG_ 197 BSMMonitoringMode "Indicates the overall mode of the Blind Spot Monitoring system as requested by the driver.";
CM_ SG_ 197 BSMSystemState "Reports the overall System Status of the BSM. To be used to drive message centre display";
CM_ SG_ 197 LeftREDAlert "Signal to inform the REDS Proximity Sensor whether traffic or obstruction is detected by SOD radar module";
CM_ SG_ 197 RCTAStatus "Indicateds the status of the RCTA system";
CM_ SG_ 197 RPCStatus "Rear Precrash feature status";
CM_ SG_ 197 RPCUserModeStatus "Confirmation status of the user selection via HMI";
CM_ SG_ 197 SODGlobalActuatorReq "A request from the SODL for all appropriate availlable actuators to provide actuation based on the detection of a PC event.";
CM_ SG_ 197 SODLAliveCounter "An alive counter from the left rear corner radar, used to determine whether the ECU is still operating.";
CM_ SG_ 197 SODLightingRequest "A request to operate the hazard lights from SOD based automated driving features.";
CM_ SG_ 196 ARAAlertRight "Right advanced reversing aid - alert";
CM_ SG_ 196 ARAMonitoringMode "Indicates the overall mode of the Blind Spot Monitoring system as requested by the driver.";
CM_ SG_ 196 AVCMRightTargetDet "Adjacent Vehicle Collision Mitigation (AVCM) system has detected an object within the right side of the host vehicle alert zone or a vehicle is fast approaching from behind and in the adjacent right lane.";
CM_ SG_ 196 BSMRightAlert "An object of interest has been detected within the alert zone on the right side of the vehicle and the driver should be alerted that there is an object present.";
CM_ SG_ 196 BSMRightCVWAlert "Cross Vehicle Warning Alert - Right.";
CM_ SG_ 196 BSMRightSensorState "Indicates the overall mode of the Right Blind Spot Monitoring sensor as a result of CAN inputs and test results";
CM_ SG_ 196 RightREDAlert "Signal to control Rear exit detection in the right rear door.";
CM_ SG_ 196 SODFeatureRequest "Feature that has requested actuation through DADC.";
CM_ SG_ 196 SODLStatus "Status of SODL Module";
CM_ SG_ 196 SODRAliveCounter "An alive counter from the right rear corner radar, used to determine whether the ECU is still operating.";
CM_ SG_ 196 SODRStatus "The overall health status of the rear right corner radar.";
CM_ SG_ 1344 NMmessageTBM "Network Management Signal. This signal contains Network Management Data. This data includes the DA (Destination Address), CF (Control Field) and up to 6 data bytes of user defined data. 

The MSB of the signal must be written to the COM layer first (with an offset of zero in wr_bytes() ) and therefore transmitted on the bus first.
Similarly, subscribing modules will receive the MSB of the signal when they call rd_bytes(0).

E.g. wr_bytes(0) = published_signal_MSB;

Subscribed_Signal_MSB = rd_bytes(0);
";
CM_ SG_ 485 GeneralSideStepStatus "Indicates a general Side step syste status";
CM_ SG_ 485 LHSideStepFailStatus "Indicates the failure/obstruction mode for LH Side Step";
CM_ SG_ 485 LHSideStepStatus "Current deployment state of the LH Electrical Side Step. This is used to select corresponding display stated on the FCDIM.";
CM_ SG_ 485 RHSideStepFailStatus "Indicates the failure/obstruction mode for RH Side Step";
CM_ SG_ 485 RHSideStepStatus "Current deployment state of the RH Electrical Side Step. This is used to select corresponding display stated on the FCDIM.";
CM_ SG_ 485 SideStepsModeRes "TBM Response to Mode Request";
CM_ SG_ 485 TowBarDeployPosition "Indicates the deployment status of the towbar from fully stowed to fully deployed. Used to display position on the HLDF.";
CM_ SG_ 485 TowBarGeneralStatus "Indicates the General status of the towbar";
CM_ SG_ 485 TowBarLoad "Indicates the Z axis towbar load";
CM_ SG_ 485 TowBarLoadMeasStat "Indicates the towbar load measurement status";
CM_ SG_ 485 TowBarObstructStatus "Indicates the obstruction status of the towbar during movement";
CM_ SG_ 485 TowBarOperationStatus "Indicates the status of the towbar";
CM_ SG_ 485 TrailerDILeftFailed "Indicates the Left Trailer DI is not working.";
CM_ SG_ 485 TrailerDIRightFailed "Indicates the Right Trailer DI is not working";
CM_ SG_ 485 TrailerStopLampFailed "Indicates the Trailer Stop Lamp is not working.";
CM_ SG_ 645 TBMTrailerLightTestReq "Request trailer light test sequence on or off";
CM_ SG_ 645 TrailerConnTestReq "Requests Cold monitor Task (300 ms test of trailer DIs and brake lights)";
CM_ SG_ 385 CDiffActuatorTempStatD7a "This signal indicates whether the transfer case actuator temperature has exceeded internal thresholds.";
CM_ SG_ 385 CdiffAliveCounterD7a "This counter forms part of a safety-related signal group.
It is incremented by the task which generates the data set used in the CRC calculation, and may be used to determine the health of the data generation task.
Refer to STJLR 18.036 for more detail.";
CM_ SG_ 385 CdiffChecksumD7a "This CRC shall be calculated in compliance with STJLR 18.036 Version 5.
The Data Segment Polynomial shall be constructed from the details
in the network configuration file.";
CM_ SG_ 385 CDiffClutchFaultStatusD7a "This signal indicates the centre locking differential clutch fault status";
CM_ SG_ 385 CDiffClutchStressD7a "Transfer case clutch temperature stress level.
The stress level is calculated from clutch disc temperature and maps the temperature range 110 - 220deg C to 0 - 100%.

0 - 100 percent of clutch stress
101 - 126 Invalid (undefined)
127 - 127 Fault Condition";
CM_ SG_ 385 CDiffCommonCauseFaultD7a "This signal indicates AWD common cause fault status.";
CM_ SG_ 385 CDiffFrontOPSpeedD7a "Output speed from the front output of the transfer case

0-8000 Shaft Speed in RPM
8001 - 65534 Invalid
65535 Fault
";
CM_ SG_ 385 CDiffHydraulicSysStatsD7a "Status of the transfer case hydraulic system
";
CM_ SG_ 385 CDiffLockingTorqActD7a "This is the centre differential current locking torque (calculated) published for SCS control

0 - 200 Nm
201 - 254 Reserved
255 Error Marker";
CM_ SG_ 385 CDiffRangeActualD7a "Transfer box range signal.The 'Undefined' state indicates that Range change is in progress


";
CM_ SG_ 385 CDiffRangeFaultStatusD7a "This signal indicates the range failure mode.";
CM_ SG_ 385 CDiffSuspectedFaultD7a "This signal indicates AWD suspected fault status ";
CM_ SG_ 824 REM2ndRowCntrMoveReq "TCU  Signal to inform RLSM of Rear Middle 2nd Row Power Arm Rest Movement Request";
CM_ SG_ 824 REM2ndRowLeftMoveReq "TCU Signal to inform RLSM Rear Left 2nd row Seat Movement Request";
CM_ SG_ 824 REM2ndRowRightMoveReq "TCU Signal to inform RRSM Rear Right 2nd Row Seat Movement Request";
CM_ SG_ 824 RemRDrvFoldReq2ndRow "Telematics Signal to 
inform DSM of a Drivers 
side 2nd Row fold 
request";
CM_ SG_ 824 RemRDrvFoldReq3rdRow "Telematics Signal to 
inform DSM of a Drivers 
side 3rd Row fold 
request";
CM_ SG_ 824 RemRPasFoldReq1stRow "Telematics Signal to inform PSM of a Passengers side 1st Row fold request";
CM_ SG_ 824 RemRPasFoldReq2ndRow "Telematics Signal to 
inform PSM of a 
Passengers side 2nd 
Row fold request";
CM_ SG_ 824 RemRPasFoldReq3rdRow "Telematics Signal to 
inform PSM of a 
Passengers side 3rd Row 
fold request";
CM_ SG_ 824 REMSkiHatchReq "Signal to inform Rear Seat Modules of a Ski Hatch Open request";
CM_ SG_ 364 TCUDataControl "CAN signal transmitted by TCU requesting a feature from BCM. Signal is also used to send the 'auth challenge response' to BCM.

Telematics feature authorisation

Byte0 definition >> 01:Feature Request (TF2), 03:Challenge Response, 04:Error Status

AA BB
00 00 Idle
01 YY Determines feature requested (TF2)
 03 Alarm Reset
 05 Alarm Sensor Disable (Ferry Mode)
 0F Vehicle Location
 30 Pre-Requisite (EWuP)
 33 Remote Engine Stop
 56 Remote Engine Start
 68 Remote Vehicle Unlock
 6F Vehicle Secure
 73 Power up seat modules and desensitize internal motion sensors
 78 Power down seat modules and resensitize internal motion sensors
  All other values reserved for future use
03 R1 Challenge Response - R1 - R6 (6 byte ANS)
04 YY Error Status
 01 Error Status - Time Out
 02 Error Status - Target SID Not Stored
 03 Error Status - Engine Blocked";
CM_ SG_ 151 TCUDataTarget "CAN signal used by BCM to send 'auth challenge query' & request status to TCU
Telematics feature authorisation

Byte1 definition >> 02: Challenge Query, 05: Status

00  XX  Idle
02  C1  Challenge Query  - C1 - C6 (6 byte RN#)
05  81  Enable status = TCU Auth / Ok
01  Disable status = NOK (Target SID Not Stored)
01  Disable status = BLOCKED
01  Disable status = Challenge Error
XX - Don't Care
";
CM_ SG_ 1612 TESTRequestKVM "This signal is for configuring second TL channel in RFA. The second TL channel is very useful for debugging, testing and analyzing the system because it allows to pass selected data in near-real-time to the CAN where it can be captured by CANalyzer. These data are not needed for vehicle operation but are very useful for troubleshooting not only of the software but also of the vehicle systems problems.

Two frames are needed because of Volcano TL configuration requirements: a TL channel requires an input frame and an output frame. We are going to use output frame only. All other ECUs on the network should simply ignore these frames and their signals.

The frames and their signals should be very similar to TST_PhysicalReqKVM and TST_PhysicalRespKVM; the reason we want to avoid using these is to avoid interference with diagnostic layer.";
CM_ SG_ 1613 TESTResponseKVM "This signal is for configuring second TL channel in RFA. The second TL channel is very useful for debugging, testing and analyzing the system because it allows to pass selected data in near-real-time to the CAN where it can be captured by CANalyzer. These data are not needed for vehicle operation but are very useful for troubleshooting not only of the software but also of the vehicle systems problems. 

Two frames are needed because of Volcano TL configuration requirements: a TL channel requires an input frame and an output frame. We are going to use output frame only. All other ECUs on the network should simply ignore these frames and their signals. 

The frames and their signals should be very similar to TST_PhysicalReqKVM and TST_PhysicalRespKVM; the reason we want to avoid using these is to avoid interference with diagnostic layer.";
CM_ SG_ 949 TimeDateSetReq_ICM "Part    No of bits     LSB           MSB     Value range      Scaling    Offset     Max Hex   Invalid HEX
                              offset         offset     Min   ->   Max
Year         8             56              63        2000      2254       1         2000        0xFE          0xFF
Month      8             48              55          0            12         1             0          0x0C          0xFF
Day          8             40              47          0            31         1             0          0x1F          0xFF
Hour         8             32              39          0           23          1             0          0x17          0xFF
Minute      8             24              31          0           59          1             0          0x3B          0xFF
Second    8             16              23          0           59          1             0          0x3B          0xFF


Description                Size    Start bit     End bit    Unit of measure     Meaning
TimeAdjustRequest    ";
CM_ SG_ 464 Timer1Time "Month Day Hour Minute currently set as Timer1

Encoding Description:
Byte 1 = Month
Byte 2 = Day of Month
Byte 3 = Hour
Byte 4 = Minute";
CM_ SG_ 464 Timer2Time "Month Day Hour Minute currently set as Timer2

Encoding Description:
Byte 1 = Month
Byte 2 = Day of Month
Byte 3 = Hour
Byte 4 = Minute";
CM_ SG_ 546 SetTimer1Time "Signal with Timer1Time

SetTimer1TimeCoding:

Bit/Byte coded:

Byte 1=Month
Byte 2=Day
Byte 3=Hour
Byte 4=Minute
";
CM_ SG_ 547 SetTimer2Time "Signal with Timer2Time

SetTimer2TimeCoding:

Bit/Byte coded:

Byte 1=Month
Byte 2=Day
Byte 3=Hour
Byte 4=Minute
";
CM_ SG_ 80 KeepNetInAfterRunTCM "CAN signal stating if the network is required for After-Run.

Description of bit field detailing each application function to be stored in the DID (After-Run Function 1- 16):
Bit 0: output speed condition (n_ab)
Bit 1: position condition (PosPRND)
Bit 2: timer condition 1(tmr_PowerDown)
Bit 3: timer condition 2 (tmr_PowerDownLong)
Bit 4: SbW Display Timer condition
Bit 5 - 15: Fixwert: 0x00";
CM_ SG_ 80 ReAlignToNeutral "Request from the TCM for the GSM to reset its output of driver request to Neutral
";
CM_ SG_ 80 ReAlignToPark "Request from the TCM for the GSM to reset its output of driver request to Park";
CM_ SG_ 80 TCMLockETSReq "Used to Lock ETS for shiftlock functionality and for locking ETS in the event of transmission failure.";
CM_ SG_ 80 TCMLockGSMReq "TCMLockGSMReq and TCMLockGSMReqComp
Signal to prevent the Stick shifter requesting Park above a speed threshold, Changed name and size to match Multican applications";
CM_ SG_ 80 TCMLockGSMReqComp "TCMLockGSMReq and TCMLockGSMReqComp
Signal to prevent the Stick shifter requesting Park above a speed threshold, Changed name and size to match Multican applications";
CM_ SG_ 80 TCMParkReqAck "Used to inform the ETS that the TCM is processing a shift request into Park, used to check validity. Max normal shift time 0.1s. Max Shift time to Park 0.4Sec.";
CM_ SG_ 80 TCMPosAliveCounter "This counter forms part of a safety-related signal group.
It is incremented by the task which generates the data set used in the CRC calculation, and may be used to determine the health of the data generation task.
Refer to STJLR 18.036 for more detail.";
CM_ SG_ 80 TCMPosChecksum "This CRC shall be calculated in compliance with STJLR 18.036 Version 5.
The Data Segment Polynomial shall be constructed from the details in the network configuration file.";
CM_ SG_ 80 TCMPositionDisplay "Message used by IPK and ETS to display selected gear information.TCM will set multiple bits when e.g in Drive 5th gear and in Sport. The Signal TCMDrivingModeDisplay can be used for gear 1-8 display when in manual mode.

Init: Blank ETS display and Blank IPK display. Bit 14 and 15 set to 1, all other bits set to 0 (49152 decimal)

Bits 0 - 5: Gear Selection
000000 = Auto selection
000001 = 1st Gear
000010 = 2nd Gear
000100 = 3rd Gear
001000 = 4th Gear
010000 = 5th Gear
100000 = 6th Gear
100001 = 7th Gear
100010 = 8th Gear
100100 = 9th Gear

Bits 6 - 11: Gear Mode
000001 = Fault
000010 = Park  Position
000100 = Reverse Position
001000 = Neutral Position
010000 = Drive Position
100000 = Sport Position 

Bits 12 - 13: Flash Display
x1 = FLASH ETS Display
1x = FLASH IPK Display

Bits 14 - 15: Blank Display
x1 = Blank ETS Display
1x = Blank IPK Display


On Electronic Shifter installations, the TCMPositionDisplay CAN message will indicate Park as follows:      - at ignition on the";
CM_ SG_ 80 TCMStartEnable "Bit is used to inform the ETS that the TCM is a position such that engine crank is permissible. ";
CM_ SG_ 80 TCMText "The code for the current TCM Text message to be displayed. 

EuCD signal name.";
CM_ SG_ 80 TransTICStatus "Used to indicate the status of transmission Idle Control functionality

This signal is provided at a QM rating only";
CM_ SG_ 2015 TesterFunctionalReq "Scan Tool Functionally Addressed Request for legislated emissions related diagnostics on CAN. This signal shall always be packaged in CANID 0x7DF.

The MSB of the signal must be written to the COM layer first (with an offset of zero in wr_bytes() ) and therefore transmitted on the bus first.
Similarly, subscribing modules will receive the MSB of the signal when they call rd_bytes(0).

E.g. wr_bytes(0) = published_signal_MSB;

Subscribed_Signal_MSB = rd_bytes(0);


";
CM_ SG_ 1860 TesterPhysicalReqDSM "Diagnostic Physically Addressed Request from Tester.

The MSB of the signal must be written to the COM layer first (with an offset of zero in wr_bytes() ) and therefore transmitted on the bus first.
Similarly, subscribing modules will receive the MSB of the signal when they call rd_bytes(0).

E.g. wr_bytes(0) = published_signal_MSB;

Subscribed_Signal_MSB = rd_bytes(0);
";
CM_ SG_ 1927 TesterPhysicalReqFTCM "Diagnostic Physically Addressed Request from Tester.

The MSB of the signal must be written to the COM layer first (with an offset of zero in wr_bytes() ) and therefore transmitted on the bus first.
Similarly, subscribing modules will receive the MSB of the signal when they call rd_bytes(0).

E.g. wr_bytes(0) = published_signal_MSB;

Subscribed_Signal_MSB = rd_bytes(0).
";
CM_ SG_ 1936 TesterPhysicalReqFTCMB "Diagnostic Physically Addressed Request from Tester.

The MSB of the signal must be written to the COM layer first (with an offset of zero in wr_bytes() ) and therefore transmitted on the bus first.
Similarly, subscribing modules will receive the MSB of the signal when they call rd_bytes(0).

E.g. wr_bytes(0) = published_signal_MSB;

Subscribed_Signal_MSB = rd_bytes(0).
";
CM_ SG_ 1841 TesterPhysicalReqKVM "Diagnostic Physically Addressed Request from Tester. Signal name is according to EuCD convention!!

The MSB of the signal must be written to the COM layer first (with an offset of zero in wr_bytes() ) and therefore transmitted on the bus first.
Similarly, subscribing modules will receive the MSB of the signal when they call rd_bytes(0).

E.g. wr_bytes(0) = published_signal_MSB;

Subscribed_Signal_MSB = rd_bytes(0);";
CM_ SG_ 1955 TesterPhysicalReqPSM "Diagnostic Physically Addressed Request from Tester.

The MSB of the signal must be written to the COM layer first (with an offset of zero in wr_bytes() ) and therefore transmitted on the bus first.
Similarly, subscribing modules will receive the MSB of the signal when they call rd_bytes(0).

E.g. wr_bytes(0) = published_signal_MSB;

Subscribed_Signal_MSB = rd_bytes(0).
";
CM_ SG_ 1909 TesterPhysicalReqRGTM "This signal is the physically-adressed diagnostic request to the RGTM ECU.

The MSB of the signal must be written to the COM layer first (with an offset of zero in wr_bytes() ) and therefore transmitted on the bus first.
Similarly, subscribing modules will receive the MSB of the signal when they call rd_bytes(0).

E.g. wr_bytes(0) = published_signal_MSB;

Subscribed_Signal_MSB = rd_bytes(0);

Address = 0x775";
CM_ SG_ 1974 TesterPhysicalReqRGTMB "This signal is the physically-adressed diagnostic request to the RGTMB ECU.

The MSB of the signal must be written to the COM layer first (with an offset of zero in wr_bytes() ) and therefore transmitted on the bus first.
Similarly, subscribing modules will receive the MSB of the signal when they call rd_bytes(0).

E.g. wr_bytes(0) = published_signal_MSB;

Subscribed_Signal_MSB = rd_bytes(0);

Address = 0x775";
CM_ SG_ 1794 TesterPhysicalReqRLSM "Diagnostic Physically Addressed Request from Tester.

The MSB of the signal must be written to the COM layer first (with an offset of zero in wr_bytes() ) and therefore transmitted on the bus first.
Similarly, subscribing modules will receive the MSB of the signal when they call rd_bytes(0).

E.g. wr_bytes(0) = published_signal_MSB;

Subscribed_Signal_MSB = rd_bytes(0).
";
CM_ SG_ 2016 TesterPhysicalReqRPDM "Diagnostic Physically Addressed Request from Tester.

The MSB of the signal must be written to the COM layer first (with an offset of zero in wr_bytes() ) and therefore transmitted on the bus first.
Similarly, subscribing modules will receive the MSB of the signal when they call rd_bytes(0).

E.g. wr_bytes(0) = published_signal_MSB;

Subscribed_Signal_MSB = rd_bytes(0).
";
CM_ SG_ 1891 TesterPhysicalReqRRSM "Diagnostic Physically Addressed Request from Tester.

The MSB of the signal must be written to the COM layer first (with an offset of zero in wr_bytes() ) and therefore transmitted on the bus first.
Similarly, subscribing modules will receive the MSB of the signal when they call rd_bytes(0).

E.g. wr_bytes(0) = published_signal_MSB;

Subscribed_Signal_MSB = rd_bytes(0).
";
CM_ SG_ 1879 TesterPhysicalReqTBM "This signal is the physically-adressed diagnostic request to the TBM ECU.

The MSB of the signal must be written to the COM layer first (with an offset of zero in wr_bytes() ) and therefore transmitted on the bus first.
Similarly, subscribing modules will receive the MSB of the signal when they call rd_bytes(0).

E.g. wr_bytes(0) = published_signal_MSB;

Subscribed_Signal_MSB = rd_bytes(0);
";
CM_ SG_ 1868 TesterPhysicalResDSM "Diagnostic Physically Addressed Response from DSM.

The MSB of the signal must be written to the COM layer first (with an offset of zero in wr_bytes() ) and therefore transmitted on the bus first.
Similarly, subscribing modules will receive the MSB of the signal when they call rd_bytes(0).

E.g. wr_bytes(0) = published_signal_MSB;

Subscribed_Signal_MSB = rd_bytes(0);
";
CM_ SG_ 1935 TesterPhysicalResFTCM "This is the diagnostic response from the FTCM (HDM).

The MSB of the signal must be written to the COM layer first (with an offset of zero in wr_bytes() ) and therefore transmitted on the bus first.
Similarly, subscribing modules will receive the MSB of the signal when they call rd_bytes(0).

E.g. wr_bytes(0) = published_signal_MSB;

Subscribed_Signal_MSB = rd_bytes(0).
";
BA_DEF_ BO_  "GenMsgSendType" ENUM  "cyclic","spontaneous","cyclicIfActive","spontaneousWithDelay","cyclicAndSpontaneous","cyclicAndSpontaneousWithDelay";
BA_DEF_ BO_  "GenMsgCycleTime" FLOAT 0 300000;
BA_DEF_ BO_  "GenMsgStartDelayTime" FLOAT 0 300000;
BA_DEF_ BO_  "GenMsgDelayTime" FLOAT 0 300000;
BA_DEF_ SG_  "GenSigSendType" ENUM  "Cyclic","OnWrite","OnWriteWithRepetition","OnChange","OnChangeWithRepetition","IfActive","IfActiveWithRepetition","NoSigSendType";
BA_DEF_ SG_  "GenSigStartValue" FLOAT -1.79769313486232E+308 1.84467440737096E+019;
BA_DEF_DEF_  "GenMsgSendType" "";
BA_DEF_DEF_  "GenMsgCycleTime" 0;
BA_DEF_DEF_  "GenMsgStartDelayTime" 0;
BA_DEF_DEF_  "GenMsgDelayTime" 0;
BA_DEF_DEF_  "GenSigSendType" "Cyclic";
BA_DEF_DEF_  "GenSigStartValue" 0;
BA_ "GenMsgDelayTime" BO_ 187 30;
BA_ "GenMsgSendType" BO_ 187 1;
BA_ "GenMsgDelayTime" BO_ 177 100;
BA_ "GenMsgSendType" BO_ 177 1;
BA_ "GenMsgDelayTime" BO_ 108 120;
BA_ "GenMsgSendType" BO_ 108 1;
BA_ "GenMsgDelayTime" BO_ 110 180;
BA_ "GenMsgSendType" BO_ 110 1;
BA_ "GenMsgDelayTime" BO_ 318 80;
BA_ "GenMsgSendType" BO_ 318 1;
BA_ "GenMsgDelayTime" BO_ 414 100;
BA_ "GenMsgSendType" BO_ 414 1;
BA_ "GenMsgCycleTime" BO_ 944 300;
BA_ "GenMsgSendType" BO_ 944 0;
BA_ "GenMsgDelayTime" BO_ 124 60;
BA_ "GenMsgSendType" BO_ 124 1;
BA_ "GenMsgDelayTime" BO_ 126 100;
BA_ "GenMsgSendType" BO_ 126 1;
BA_ "GenMsgDelayTime" BO_ 132 20;
BA_ "GenMsgSendType" BO_ 132 1;
BA_ "GenMsgDelayTime" BO_ 116 80;
BA_ "GenMsgSendType" BO_ 116 1;
BA_ "GenMsgDelayTime" BO_ 239 80;
BA_ "GenMsgSendType" BO_ 239 1;
BA_ "GenMsgCycleTime" BO_ 97 40;
BA_ "GenMsgSendType" BO_ 97 0;
BA_ "GenMsgCycleTime" BO_ 788 1000;
BA_ "GenMsgSendType" BO_ 788 0;
BA_ "GenMsgCycleTime" BO_ 349 60;
BA_ "GenMsgSendType" BO_ 349 0;
BA_ "GenMsgDelayTime" BO_ 350 60;
BA_ "GenMsgSendType" BO_ 350 1;
BA_ "GenMsgCycleTime" BO_ 488 100;
BA_ "GenMsgSendType" BO_ 488 0;
BA_ "GenMsgCycleTime" BO_ 453 60;
BA_ "GenMsgSendType" BO_ 453 0;
BA_ "GenMsgCycleTime" BO_ 461 40;
BA_ "GenMsgSendType" BO_ 461 0;
BA_ "GenMsgDelayTime" BO_ 456 60;
BA_ "GenMsgSendType" BO_ 456 1;
BA_ "GenMsgDelayTime" BO_ 84 20;
BA_ "GenMsgSendType" BO_ 84 1;
BA_ "GenMsgCycleTime" BO_ 211 30;
BA_ "GenMsgSendType" BO_ 211 0;
BA_ "GenMsgDelayTime" BO_ 1368 100;
BA_ "GenMsgSendType" BO_ 1368 1;
BA_ "GenMsgCycleTime" BO_ 213 30;
BA_ "GenMsgSendType" BO_ 213 0;
BA_ "GenMsgCycleTime" BO_ 1002 800;
BA_ "GenMsgSendType" BO_ 1002 0;
BA_ "GenMsgCycleTime" BO_ 1003 900;
BA_ "GenMsgSendType" BO_ 1003 0;
BA_ "GenMsgCycleTime" BO_ 1004 900;
BA_ "GenMsgSendType" BO_ 1004 0;
BA_ "GenMsgCycleTime" BO_ 1005 900;
BA_ "GenMsgSendType" BO_ 1005 0;
BA_ "GenMsgDelayTime" BO_ 191 40;
BA_ "GenMsgSendType" BO_ 191 1;
BA_ "GenMsgDelayTime" BO_ 74 10;
BA_ "GenMsgSendType" BO_ 74 1;
BA_ "GenMsgDelayTime" BO_ 76 10;
BA_ "GenMsgSendType" BO_ 76 1;
BA_ "GenMsgCycleTime" BO_ 330 50;
BA_ "GenMsgSendType" BO_ 330 0;
BA_ "GenMsgDelayTime" BO_ 483 50;
BA_ "GenMsgSendType" BO_ 483 1;
BA_ "GenMsgDelayTime" BO_ 484 30;
BA_ "GenMsgSendType" BO_ 484 1;
BA_ "GenMsgDelayTime" BO_ 486 60;
BA_ "GenMsgSendType" BO_ 486 1;
BA_ "GenMsgDelayTime" BO_ 1318 100;
BA_ "GenMsgSendType" BO_ 1318 1;
BA_ "GenMsgCycleTime" BO_ 480 40;
BA_ "GenMsgSendType" BO_ 480 0;
BA_ "GenMsgDelayTime" BO_ 430 80;
BA_ "GenMsgSendType" BO_ 430 1;
BA_ "GenMsgDelayTime" BO_ 1402 100;
BA_ "GenMsgSendType" BO_ 1402 1;
BA_ "GenMsgCycleTime" BO_ 611 180;
BA_ "GenMsgSendType" BO_ 611 0;
BA_ "GenMsgDelayTime" BO_ 431 50;
BA_ "GenMsgSendType" BO_ 431 1;
BA_ "GenMsgDelayTime" BO_ 1306 100;
BA_ "GenMsgSendType" BO_ 1306 1;
BA_ "GenMsgCycleTime" BO_ 389 100;
BA_ "GenMsgSendType" BO_ 389 0;
BA_ "GenMsgCycleTime" BO_ 390 250;
BA_ "GenMsgSendType" BO_ 390 0;
BA_ "GenMsgCycleTime" BO_ 530 300;
BA_ "GenMsgSendType" BO_ 530 0;
BA_ "GenMsgDelayTime" BO_ 1385 100;
BA_ "GenMsgSendType" BO_ 1385 1;
BA_ "GenMsgCycleTime" BO_ 682 200;
BA_ "GenMsgSendType" BO_ 682 0;
BA_ "GenMsgDelayTime" BO_ 86 20;
BA_ "GenMsgSendType" BO_ 86 1;
BA_ "GenMsgCycleTime" BO_ 379 120;
BA_ "GenMsgSendType" BO_ 379 0;
BA_ "GenMsgCycleTime" BO_ 503 60;
BA_ "GenMsgSendType" BO_ 503 0;
BA_ "GenMsgCycleTime" BO_ 504 150;
BA_ "GenMsgSendType" BO_ 504 0;
BA_ "GenMsgCycleTime" BO_ 761 350;
BA_ "GenMsgSendType" BO_ 761 0;
BA_ "GenMsgDelayTime" BO_ 197 20;
BA_ "GenMsgSendType" BO_ 197 1;
BA_ "GenMsgDelayTime" BO_ 196 20;
BA_ "GenMsgSendType" BO_ 196 1;
BA_ "GenMsgCycleTime" BO_ 485 50;
BA_ "GenMsgSendType" BO_ 485 0;
BA_ "GenMsgDelayTime" BO_ 645 100;
BA_ "GenMsgSendType" BO_ 645 1;
BA_ "GenMsgDelayTime" BO_ 385 40;
BA_ "GenMsgSendType" BO_ 385 1;
BA_ "GenMsgDelayTime" BO_ 824 800;
BA_ "GenMsgSendType" BO_ 824 1;
BA_ "GenMsgDelayTime" BO_ 364 120;
BA_ "GenMsgSendType" BO_ 364 1;
BA_ "GenMsgDelayTime" BO_ 151 5;
BA_ "GenMsgSendType" BO_ 151 1;
BA_ "GenMsgSendType" BO_ 1612 1;
BA_ "GenMsgDelayTime" BO_ 949 900;
BA_ "GenMsgSendType" BO_ 949 1;
BA_ "GenMsgCycleTime" BO_ 464 100;
BA_ "GenMsgSendType" BO_ 464 0;
BA_ "GenMsgDelayTime" BO_ 546 300;
BA_ "GenMsgSendType" BO_ 546 1;
BA_ "GenMsgDelayTime" BO_ 547 300;
BA_ "GenMsgSendType" BO_ 547 1;
BA_ "GenMsgDelayTime" BO_ 80 20;
BA_ "GenMsgSendType" BO_ 80 1;
BA_ "GenMsgSendType" BO_ 2015 1;
BA_ "GenMsgDelayTime" BO_ 1856 5;
BA_ "GenMsgSendType" BO_ 1856 1;
BA_ "GenMsgDelayTime" BO_ 1858 5;
BA_ "GenMsgSendType" BO_ 1858 1;
BA_ "GenMsgDelayTime" BO_ 1860 100;
BA_ "GenMsgSendType" BO_ 1860 1;
BA_ "GenMsgDelayTime" BO_ 1927 100;
BA_ "GenMsgSendType" BO_ 1927 1;
BA_ "GenMsgDelayTime" BO_ 1936 100;
BA_ "GenMsgSendType" BO_ 1936 1;
BA_ "GenMsgDelayTime" BO_ 1841 100;
BA_ "GenMsgSendType" BO_ 1841 1;
BA_ "GenMsgDelayTime" BO_ 1857 5;
BA_ "GenMsgSendType" BO_ 1857 1;
BA_ "GenMsgDelayTime" BO_ 1859 5;
BA_ "GenMsgSendType" BO_ 1859 1;
BA_ "GenMsgDelayTime" BO_ 1955 100;
BA_ "GenMsgSendType" BO_ 1955 1;
BA_ "GenMsgDelayTime" BO_ 1909 100;
BA_ "GenMsgSendType" BO_ 1909 1;
BA_ "GenMsgDelayTime" BO_ 1974 100;
BA_ "GenMsgSendType" BO_ 1974 1;
BA_ "GenMsgDelayTime" BO_ 1794 100;
BA_ "GenMsgSendType" BO_ 1794 1;
BA_ "GenMsgDelayTime" BO_ 2016 100;
BA_ "GenMsgSendType" BO_ 2016 1;
BA_ "GenMsgDelayTime" BO_ 1891 100;
BA_ "GenMsgSendType" BO_ 1891 1;
BA_ "GenMsgDelayTime" BO_ 1879 100;
BA_ "GenMsgSendType" BO_ 1879 1;
BA_ "GenMsgDelayTime" BO_ 1826 100;
BA_ "GenMsgSendType" BO_ 1826 1;
BA_ "GenMsgDelayTime" BO_ 1799 100;
BA_ "GenMsgSendType" BO_ 1799 1;
BA_ "GenMsgSendType" BO_ 1864 1;
BA_ "GenMsgSendType" BO_ 1866 1;
BA_ "GenSigSendType" SG_ 108 IgnitionAuthDataControl 1;
BA_ "GenSigStartValue" SG_ 318 AmbientLightValueIPC 1;
BA_ "GenSigStartValue" SG_ 318 DistanceToEmpty 1023;
BA_ "GenSigSendType" SG_ 414 EncryptionRollingCode 1;
BA_ "GenSigSendType" SG_ 414 KVDecryptedMsg2 1;
BA_ "GenSigSendType" SG_ 414 PECentralLockCmd2 1;
BA_ "GenSigSendType" SG_ 414 PELockButtonReq2 1;
BA_ "GenSigSendType" SG_ 414 PKeyId2 1;
BA_ "GenSigSendType" SG_ 414 ProvUnlockDriverSide 1;
BA_ "GenSigSendType" SG_ 414 ProvUnlockPassSide 1;
BA_ "GenSigSendType" SG_ 1386 NMMessageLPDM 1;
BA_ "GenSigSendType" SG_ 124 PATSDataControl 1;
BA_ "GenSigStartValue" SG_ 132 EngineSpeedQF 1;
BA_ "GenSigStartValue" SG_ 239 AmbientAirPressureQF 1;
BA_ "GenSigStartValue" SG_ 239 AmbientTempQF 1;
BA_ "GenSigStartValue" SG_ 239 EngineCoolantTempQF 1;
BA_ "GenSigStartValue" SG_ 239 EngineOilTempQF 1;
BA_ "GenSigStartValue" SG_ 97 ClutchPedalAnalogPosQF 1;
BA_ "GenSigStartValue" SG_ 349 PassMirrorFoldStat 5;
BA_ "GenSigStartValue" SG_ 349 PassngrDoorSCAStatus 3;
BA_ "GenSigStartValue" SG_ 349 PDoorLatchStatus 2;
BA_ "GenSigSendType" SG_ 350 PassWindowPosition 1;
BA_ "GenSigSendType" SG_ 350 PDHandleStatus 1;
BA_ "GenSigSendType" SG_ 350 PDLockSwitchPress 1;
BA_ "GenSigSendType" SG_ 350 PDUnlockSwitchPress 1;
BA_ "GenSigStartValue" SG_ 453 RearPassDoorSCAStatus 3;
BA_ "GenSigSendType" SG_ 456 PassRearWindowPos 1;
BA_ "GenSigSendType" SG_ 456 PRDChildLockStatus 1;
BA_ "GenSigStartValue" SG_ 456 PRDChildLockStatus 3;
BA_ "GenSigSendType" SG_ 456 PRDoorLatchStatus 1;
BA_ "GenSigStartValue" SG_ 456 PRDoorLatchStatus 2;
BA_ "GenSigSendType" SG_ 456 PRHandleStatus 1;
BA_ "GenSigSendType" SG_ 456 RPDLockSwitchPress 1;
BA_ "GenSigSendType" SG_ 456 RPDUnlockSwitchPress 1;
BA_ "GenSigSendType" SG_ 1368 NMmessagePSM 1;
BA_ "GenSigStartValue" SG_ 191 KeepNetInAfterRunRCM 1;
BA_ "GenSigStartValue" SG_ 191 VerticalAcceleration 2048;
BA_ "GenSigStartValue" SG_ 74 A1 32768;
BA_ "GenSigStartValue" SG_ 74 A1_STAT 4;
BA_ "GenSigStartValue" SG_ 74 PSIP1 32768;
BA_ "GenSigStartValue" SG_ 74 PSIP1_STAT 4;
BA_ "GenSigStartValue" SG_ 76 A2 32768;
BA_ "GenSigStartValue" SG_ 76 A2_STAT 4;
BA_ "GenSigStartValue" SG_ 76 PSIPP1 32768;
BA_ "GenSigStartValue" SG_ 76 PSIPP1_STAT 4;
BA_ "GenSigSendType" SG_ 1288 NMmessageKVM 1;
BA_ "GenSigSendType" SG_ 483 KVDecryptedMsg 1;
BA_ "GenSigSendType" SG_ 483 PECentralLockCmd 1;
BA_ "GenSigSendType" SG_ 483 PELockButtonReq 1;
BA_ "GenSigSendType" SG_ 483 PKeyId 1;
BA_ "GenSigSendType" SG_ 483 PKeyIdScanArea 1;
BA_ "GenSigSendType" SG_ 483 PKeyIdsInAreaReported 1;
BA_ "GenSigSendType" SG_ 484 PEPullSwitchStatus 1;
BA_ "GenSigSendType" SG_ 484 PKBattStatus 1;
BA_ "GenSigSendType" SG_ 484 PkeyScanComp 1;
BA_ "GenSigSendType" SG_ 484 PKeyScanID 1;
BA_ "GenSigSendType" SG_ 484 PKeyWarningInd 1;
BA_ "GenSigSendType" SG_ 484 PLockRequestDD 1;
BA_ "GenSigSendType" SG_ 484 PLockRequestPD 1;
BA_ "GenSigSendType" SG_ 484 PLockRequestRL 1;
BA_ "GenSigSendType" SG_ 484 PLockRequestRR 1;
BA_ "GenSigSendType" SG_ 484 PLockRequestTrunk 1;
BA_ "GenSigSendType" SG_ 484 PUnlockRequestDD 1;
BA_ "GenSigSendType" SG_ 484 PUnlockRequestPD 1;
BA_ "GenSigSendType" SG_ 484 PUnlockRequestRL 1;
BA_ "GenSigSendType" SG_ 484 PUnlockRequestRR 1;
BA_ "GenSigSendType" SG_ 484 PUnlockRequestTGlass 1;
BA_ "GenSigSendType" SG_ 484 PUnlockRequestTrunk 1;
BA_ "GenSigSendType" SG_ 486 ImmoAuthPKeyMainResp 1;
BA_ "GenSigSendType" SG_ 486 ImmoPKeyApproved 1;
BA_ "GenSigSendType" SG_ 1318 NMmessageRGTM 1;
BA_ "GenSigStartValue" SG_ 480 PCUStatus 3;
BA_ "GenSigStartValue" SG_ 480 POTSecondaryLatchSt 1;
BA_ "GenSigSendType" SG_ 430 PKExtScanReqTailgate 1;
BA_ "GenSigSendType" SG_ 430 POTCompleteCloseReq 1;
BA_ "GenSigSendType" SG_ 430 UpperPOTailgatePinch 1;
BA_ "GenSigSendType" SG_ 430 UpperPwrTGObjectDetect 1;
BA_ "GenSigSendType" SG_ 430 UpperTGateMislockWng 1;
BA_ "GenSigSendType" SG_ 1402 NMmessageRGTMB 1;
BA_ "GenSigStartValue" SG_ 611 PCUStatusLwrLHS 3;
BA_ "GenSigStartValue" SG_ 611 PCUStatusLwrRHS 3;
BA_ "GenSigStartValue" SG_ 611 POTSecLatchStatLwrLHS 1;
BA_ "GenSigStartValue" SG_ 611 POTSecLatchStatLwrRHS 1;
BA_ "GenSigSendType" SG_ 431 LowerPOTailgatePinch 1;
BA_ "GenSigSendType" SG_ 431 LowerPwrTGObjectDetect 1;
BA_ "GenSigSendType" SG_ 431 LwrTrunkReleaseCmd 1;
BA_ "GenSigSendType" SG_ 1306 NMmessageRLSM 1;
BA_ "GenSigSendType" SG_ 1327 NMMessageRPDM 1;
BA_ "GenSigSendType" SG_ 1385 NMmessageRRSM 1;
BA_ "GenSigStartValue" SG_ 86 SteeringWheelAngle 7800;
BA_ "GenSigStartValue" SG_ 86 SteeringWheelAngleStatus 1;
BA_ "GenSigStartValue" SG_ 503 GSAPositionDisplay 49152;
BA_ "GenSigStartValue" SG_ 503 GSAPosStatus 15;
BA_ "GenSigSendType" SG_ 503 LSMMirrorFoldReq 1;
BA_ "GenSigStartValue" SG_ 504 LaserStatus 15;
BA_ "GenSigStartValue" SG_ 761 CDiffRangeActual 3;
BA_ "GenSigStartValue" SG_ 197 BSMMonitoringMode 2;
BA_ "GenSigSendType" SG_ 1344 NMmessageTBM 1;
BA_ "GenSigStartValue" SG_ 485 TowBarLoad 127;
BA_ "GenSigStartValue" SG_ 485 TrailerDILeftFailed 1;
BA_ "GenSigStartValue" SG_ 485 TrailerDIRightFailed 1;
BA_ "GenSigStartValue" SG_ 485 TrailerStopLampFailed 1;
BA_ "GenSigSendType" SG_ 645 TBMTrailerLightTestReq 1;
BA_ "GenSigSendType" SG_ 645 TrailerConnTestReq 1;
BA_ "GenSigSendType" SG_ 151 TCUDataTarget 1;
BA_ "GenSigSendType" SG_ 1613 TESTResponseKVM 1;
BA_ "GenSigStartValue" SG_ 80 ReAlignToNeutral 1;
BA_ "GenSigStartValue" SG_ 80 ReAlignToPark 1;
BA_ "GenSigStartValue" SG_ 80 TCMLockGSMReqComp 15;
BA_ "GenSigStartValue" SG_ 80 TCMPositionDisplay 49152;
BA_ "GenSigSendType" SG_ 1868 TesterPhysicalResDSM 1;
BA_ "GenSigSendType" SG_ 1935 TesterPhysicalResFTCM 1;
VAL_ 187 AmbLightProfileLoad 0 "No Profile" 1 "Profile 1" 2 "Profile 2" 3 "Profile 3" 4 "Profile 4" 5 "Not Used" 6 "Default" 7 "Default 2" ;
VAL_ 187 AmbLightProfileStore 0 "No Profile" 1 "Profile 1" 2 "Profile 2" 3 "Profile 3" 4 "Profile 4" 5 "Not Used" 6 "Default" 7 "Default 2" ;
VAL_ 187 AmbLightUIDynAutoSw 0 "auto dynamic lighting required OFF" 1 "auto dynamic lighting required ON" ;
VAL_ 177 ActivateTimer 0 "Off" 1 "On" ;
VAL_ 177 AutoBlindEnableReq 0 "Disable Request" 1 "Enable Request" ;
VAL_ 177 DIAnimationEnableReq 0 "Disabled" 1 "Enabled" ;
VAL_ 177 EEEStateRequest 0 "Disable" 1 "Enable" ;
VAL_ 177 EnableDippedMirror 0 "Disabled" 1 "Enabled" ;
VAL_ 177 GestureBlindEnableSw 0 "Button Not Pressed" 1 "Button Pressed" ;
VAL_ 177 RearCameraWashReq 0 "Wash not requested" 1 "Wash requested" ;
VAL_ 177 SideStepsModeReq 0 "Off" 1 "Roof Access Mode" 2 "Terrain Response Override" 3 "Normal/On" ;
VAL_ 177 SinglePointEntryReq 0 "Request Single Point Entry OFF" 1 "Request Single Point Entry ON" ;
VAL_ 177 StealthModeUISwitch 0 "Stealth mode not requested" 1 "Stealth mode requested" 2 "reserved2" 3 "reserved2" ;
VAL_ 177 TowBarFunctionReq 0 "No action" 1 "Deploy" 2 "Stow" 3 "Stop" ;
VAL_ 177 TowBarMeasureLoad 0 "NO req/OFF" 1 "Measure" ;
VAL_ 177 TrailerLightTestReq 0 " No action " 1 "Turn on or off" ;
VAL_ 177 ValetReq 0 "Valet Mode Inactive" 1 "Valet Mode Active" ;
VAL_ 177 WakeShutDownEnableReq 0 "WakeupShutdown Menu Disabled" 1 "WakeupShutdown Menu Enabled" ;
VAL_ 177 WalkAwayLockReq 0 "Undefined" 1 "Central Locking" 2 "Remain Unlocked" 3 "Double Locking" ;
VAL_ 177 WindowsGlobalCloseReq 0 "Disabled" 1 "Enabled" ;
VAL_ 177 WindowsGlobalOpenReq 0 "Disabled" 1 "Enabled" ;
VAL_ 177 WiperWinterParkReq 0 "Disabled" 1 "Enabled" ;
VAL_ 318 AmbientLightValueIPC 254 "Light sensor not available" 255 "Light sensor faulty i.e open circuit or short circuit etc" ;
VAL_ 318 DistanceToEmpty 1023 "Error" ;
VAL_ 318 InstAccEnable 0 "not enabled for ACC" 1 "enabled for ACC" ;
VAL_ 318 SpeedometerUnits 0 "km/h / km" 1 "MPH / miles" ;
VAL_ 318 SPMModeRequest 0 "Request Low sensitivity" 1 "Request Medium sensitivity" 2 "Request High sensitivity" 3 "Request Snow / Ice" ;
VAL_ 318 StgColLockGndEnableStatus 0 "Off/Lock" 1 "Off/Unlock" 2 "On/Lock" 3 "On/Unlock" ;
VAL_ 318 TPMSLoadThresholdsReq 0 "Keep current thresholds" 1 "Use low load thresholds" 2 "Use high load thresholds" 3 "Unused" ;
VAL_ 318 TripUnits 0 "km/h / km" 1 "MPH / miles" ;
VAL_ 414 KVDecryptedMsg2 0 "IGNORE" 1 "Lock" 2 "Unlock" 3 "Tailgate" 4 "Approach Light" 5 "Panic Alarm" 6 "Security Check Req" 7 "Change Lock Mode" 13 "Return Suspension to normal height" 14 "Raise Suspension" 15 "Lower Suspension" ;
VAL_ 414 PELockButtonReq2 0 "Not used" 1 "Driver Door" 2 "Passenger Door" 3 "Left Rear Door" 4 "Right Rear Door" 7 "Not Activated" ;
VAL_ 414 ProvUnlockDriverSide 0 "provisional unlocking not active on driver side" 1 "provisional unlocking active on driver side" ;
VAL_ 414 ProvUnlockPassSide 0 "provisional unlocking not active on passenger side" 1 "provisional unlocking active on passenger side" ;
VAL_ 944 LeftPowerDoorStatus 0 "Unknown" 1 "Normal" 2 "Closing" 3 "Body angle exceeds closing limit" 4 "Body angle exceeds holding limit" 5 "Door closing obstruction" 6 "Temperature too low for operation" 7 "Temperature too high for operation" 8 "Insufficient power available for operation" 9 "Reserved9" 10 "Reserved10" 11 "Reserved11" 12 "Reserved12" 13 "Reserved13" 14 "Reserved14" 15 "Fault" ;
VAL_ 132 BrakeSwitchStatus 0 "Normal Condition" 1 "Brake Pedal Pressed" 2 "(Undefined)" 3 "Brake Switch Fault" ;
VAL_ 132 EngineSpeedQF 0 "The accuracy of the data is undefinable" 1 "Data is temporarily undefinable, evaluation in progress" 2 "The accuracy of the data is not within specification" 3 "The data is calculated with the specified accuracy" ;
VAL_ 132 MHStopStartStatus 0 "STARTUP" 1 "DEACTIVATED" 2 "DESELECTED" 3 "STOP AVAILABLE" 4 "STOP NOT AVAILABLE" 5 "STOPPED" 6 "PRESS CLUTCH PEDAL" 7 "SELECT NEUTRAL" 8 "PRESS BRAKE PEDAL" 9 "IMMINENT START WARNING" 10 "ERROR" 11 "EXT TEMP" 12 "DPF REGEN" 13 "BATT CHARGE" 14 "SYS DEMAND" 15 "A/C DEMAND" ;
VAL_ 132 PowerPackStatus 0 "Init" 1 "Awake" 2 "Ready" 3 "PreStarting" 4 "StartingInProgress" 5 "Running_Running" 6 "Running_Standby" 7 "Running_StartingInProgress" 8 "Running_RemoteStarted" 9 "AfterRun" ;
VAL_ 116 ChargDataWakeUpAllowed 0 "Not Allowed" 1 "Allowed" ;
VAL_ 116 ChargePwrInterruptDisp 0 "No message" 1 "Power Interrupted" ;
VAL_ 116 ChrgNotReadyByDepDisp 0 "No message" 1 "Charging Not Ready By Departure Time" ;
VAL_ 116 ChrgNotReadyReasonDisp 0 "No message" 1 "Powercut has occured" 2 "Insufficient charging period" 3 "Insufficient grid power supply" 4 "Wireless pad misaligned" 5 "Foreign object present between wireless pad" 6 "Unused6" 7 "Unused7" ;
VAL_ 116 EVRangePredictStatus 0 "INITIALISATION" 1 "DISPLAY_RANGE" 2 "RECALCULATING" 3 "ERROR_BLANK" ;
VAL_ 239 AmbientAirPressureQF 0 "The accuracy of the data is undefinable" 1 "Data is temporarily undefinable, evaluation in progress" 2 "The accuracy of the data is not within specification" 3 "The data is calculated with the specified accuracy" ;
VAL_ 239 AmbientTempQF 0 "The accuracy of the data is undefinable" 1 "Data is temporarily undefinable, evaluation in progress" 2 "The accuracy of the data is not within specification" 3 "The data is calculated with the specified accuracy" ;
VAL_ 239 EngineCoolantTempQF 0 "The accuracy of the data is undefinable" 1 "Data is temporarily undefinable, evaluation in progress" 2 "The accuracy of the data is not within specification" 3 "The data is calculated with the specified accuracy" ;
VAL_ 239 EngineOilTempQF 0 "The accuracy of the data is undefinable" 1 "Data is temporarily undefinable, evaluation in progress" 2 "The accuracy of the data is not within specification" 3 "The data is calculated with the specified accuracy" ;
VAL_ 97 ClutchPedalAnalogPosQF 0 "The accuracy of the data is undefinable" 1 "Data is temporarily undefinable, evaluation in progress" 2 "The accuracy of the data is not within specification" 3 "The data is calculated with the specified accuracy" ;
VAL_ 97 ClutchPedalPressed 0 "Not pressed" 1 "Pressed" ;
VAL_ 97 ClutchPedalSwitch 0 "Not Pressed" 1 "Pressed" ;
VAL_ 349 DZMPasLeftHmiOp 0 "Message Inactive" 1 "HMI Fault" 2 "HMI not illuminated" 3 "HMI status LED illuminated" 4 "HMI alert LED illuminated" ;
VAL_ 349 DZMPasRightHmiOp 0 "Message Inactive" 1 "HMI Fault" 2 "HMI not illuminated" 3 "HMI status LED illuminated" 4 "HMI alert LED illuminated" ;
VAL_ 349 PassMirrorFoldStat 0 "Unfolded" 1 "Folding" 2 "Unfolding" 3 "Folded" 4 "Error" 5 "RESERVED3" 6 "RESERVED2" 7 "RESERVED1" ;
VAL_ 349 PassngrDoorSCAStatus 0 "SCA in home position" 1 "SCA closing" 2 "SCA returning" 3 "SCA position unknown" ;
VAL_ 349 PDClawSwitchStatus 0 "INACTIVE (OPEN/unlatched)" 1 "ACTIVE (CLOSED/latched)" ;
VAL_ 349 PDMReqBusAwake 0 "Node not requesting bus keepawake." 1 "Node requesting bus keepawake." ;
VAL_ 349 PDMSetngAppl 0 "Settings not applied" 1 "Settings applied" ;
VAL_ 349 PDPawlSwitchStatus 0 "INACTIVE (OPEN/unlatched)" 1 "ACTIVE (CLOSED/latched)" ;
VAL_ 349 PsgMirrorStatus 0 "Passenger Mirror in Unknown state (Default value)" 1 "Passenger Mirror Folded" 2 "Passenger Mirror Un-Folded" 3 "Passenger Mirror Fold in Progress" 4 "Passenger Mirror Un-Fold in Progress" 5 "Fault in Folding Passenger Mirror" 6 "Fault in Un-Folding Passenger Mirror" 7 "Reserved or Not used" ;
VAL_ 349 SeatMem1ButtonStatP 0 "Inactive/off" 1 "Active/on" ;
VAL_ 349 SeatMem2ButtonStatP 0 "Inactive/off" 1 "Active/on" ;
VAL_ 349 SeatMem3ButtonStatP 0 "Inactive/off" 1 "Active/on" ;
VAL_ 349 SeatMemLEDStatP 0 "Inactive/off" 1 "Active/on" ;
VAL_ 349 SeatMemSetBtnStatP 0 "Inactive/off" 1 "Active/on" ;
VAL_ 350 PassWindowPosition 0 "Undefined window position" 1 "Fully closed position" 2 "Between fully closed and 10 % open" 3 "Between 10 % open and 60 % open" 4 "Between 60 % open and fully open" 5 "Fully open position" ;
VAL_ 350 PDHandleStatus 0 "Initial Value" 1 "Not moving - position unknown" 2 "Not moving - door handle deployed" 3 "Not moving - door handle retracted" 4 "Moving - door handle deploying" 5 "Moving - door handle retracting" 6 "Door handle fault" 7 "Not Used" ;
VAL_ 350 PDLockSwitchPress 0 "Switch not active" 1 "Switch Active" ;
VAL_ 350 PDUnlockSwitchPress 0 "Switch not active" 1 "Switch Active" ;
VAL_ 488 RockerSwitch1Req_b 0 "Off" 1 "Up" 2 "Auto Up" 3 "Down" 4 "Auto Down" ;
VAL_ 488 RockerSwitch2Req_b 0 "Off" 1 "Up" 2 "Auto Up" 3 "Down" 4 "Auto Down" ;
VAL_ 488 SunRoofFrBlindBtnReq_B 0 "Button Released" 1 "Button Pressed" ;
VAL_ 488 TaskLightRelaxBtnReq_B 0 "Button Released" 1 "Button Pressed" ;
VAL_ 488 TaskLightWorkBtnReq_B 0 "Button Released" 1 "Button Pressed" ;
VAL_ 453 AudioMutePR 0 "Button Released" 1 "Button Pressed" ;
VAL_ 453 PRDMReqBusAwake 0 "No Request" 1 "Request Active" ;
VAL_ 453 RearPassDoorSCAStatus 0 "SCA in home position" 1 "SCA closing" 2 "SCA returning" 3 "SCA position unknown" ;
VAL_ 453 RearPassREDHMIStatus 0 "RED HMI Available" 1 "RED HMI Fault" ;
VAL_ 453 RearPDClawSwitchStatus 0 "INACTIVE (OPEN/unlatched)" 1 "ACTIVE (CLOSED/latched)" ;
VAL_ 453 RearPDPawlSwitchStatus 0 "INACTIVE (OPEN/unlatched)" 1 "ACTIVE (CLOSED/latched)" ;
VAL_ 453 SeatMem1ButtonStatPR 0 "Inactive/off" 1 "Active/on" ;
VAL_ 453 SeatMem2ButtonStatPR 0 "Inactive/off" 1 "Active/on" ;
VAL_ 453 SeatMem3ButtonStatPR 0 "Inactive/off" 1 "Active/on" ;
VAL_ 453 SeatMemLEDStatPR 0 "Inactive/off" 1 "Active/on" ;
VAL_ 453 SeatMemSetBtnStatPR 0 "Inactive/off" 1 "Active/on" ;
VAL_ 461 PSeatHghtDnReqPRDSP 0 "OFF" 1 "ON" ;
VAL_ 461 PSeatHghtUpReqPRDSP 0 "OFF" 1 "ON" ;
VAL_ 461 PSeatInclineReqPRDSP 0 "OFF" 1 "ON" ;
VAL_ 461 PSeatReclineReqPRDSP 0 "OFF" 1 "ON" ;
VAL_ 461 PSeatSlideFWReqPRDSP 0 "OFF" 1 "ON" ;
VAL_ 461 PSeatSlideRWReqPRDSP 0 "OFF" 1 "ON" ;
VAL_ 456 PassRearWindowPos 0 "Undefined window position" 1 "Fully closed position" 2 "Between fully closed and 10 % open" 3 "Between 10 % open and 60 % open" 4 "Between 60 % open and fully open" 5 "Fully open position" ;
VAL_ 456 PRDChildLockStatus 0 "Unlocked" 1 "Locked" 2 "Error" 3 "Ignore" ;
VAL_ 456 PRHandleStatus 0 "Initial Value" 1 "Not moving - position unknown" 2 "Not moving - door handle deployed" 3 "Not moving - door handle retracted" 4 "Moving - door handle deploying" 5 "Moving - door handle retracting" 6 "Door handle fault" 7 "Not Used" ;
VAL_ 456 RPDLockSwitchPress 0 "Switch not active" 1 "Switch Active" ;
VAL_ 456 RPDUnlockSwitchPress 0 "Switch not active" 1 "Switch Active" ;
VAL_ 84 TorsionBarTorque 1023 "Data is undefinable" ;
VAL_ 84 TorsionBarTorqueQF 0 "The accuracy of the data is undefinable" 1 "Data is temporarily undefinable, evaluation in progress" 2 "The accuracy of the data is not within specification" 3 "The data is calculated with the specified accuracy" ;
VAL_ 84 TorsionBarTorqueSign 0 "Counterclockwise" 1 "Clockwise" ;
VAL_ 211 PasSeatInhib1stRow 0 "Available to receive a seat movement request" 1 "Seat movement is Inhibited" ;
VAL_ 211 PasSeatInhib2ndRow 0 "Available to receive a seat movement request" 1 "Seat movement is Inhibited" ;
VAL_ 211 PasSeatInhib3rdRow 0 "Available to receive a seat movement request" 1 "Seat movement is Inhibited" ;
VAL_ 211 PasSeatPosition1stRow 0 "Unknown / Initialising" 1 "Folded" 2 "Unfolded" 3 "Mid Travel (Stationary)" 4 "Moving" ;
VAL_ 211 PasSeatPosition2ndRow 0 "Unknown / Initialising" 1 "Folded" 2 "Unfolded" 3 "Mid Travel (Stationary)" 4 "Moving" ;
VAL_ 211 PasSeatPosition3rdRow 0 "Unknown / Initialising" 1 "Folded" 2 "Unfolded" 3 "Mid Travel (Stationary)" 4 "Moving" ;
VAL_ 211 PassengerCancelSeat 0 "Not cancel" 1 "Cancel Movement" ;
VAL_ 211 PassengerSeatMovement 0 "No Passenger Seat Movement" 1 "Passenger Seat Movement" ;
VAL_ 211 PassSeatFootRestStat 0 "Footrest Retracted" 1 "Footrest Deployed" ;
VAL_ 211 PassSeatMemLoadStat 0 "Default" 1 "Memory 1 Recalled" 2 "Memory 2 Recalled" 3 "Memory 3 Recalled" 4 "Rear Memory 1 Recalled" 5 "Rear Memory 2 Recalled" 6 "Rear Memory 3 Recalled" 7 "Undefined" ;
VAL_ 211 PassSeatMemStorStat 0 "Default" 1 "Memory 1 Stored" 2 "Memory 2 Stored" 3 "Memory 3 Stored" 4 "Rear Memory 1 Stored" 5 "Rear Memory 2 Stored" 6 "Rear Memory 3 Stored" 7 "Undefined" ;
VAL_ 211 PassSeatMovement2ndRow 0 "Seat stopped mid travel" 1 "Seat Fully folded" 2 "Seat Fully Unfolded" 3 "Seat moving" ;
VAL_ 211 PassSeatMovement3rdRow 0 "Seat stopped mid travel" 1 "Seat Fully folded" 2 "Seat Fully Unfolded" 3 "Seat moving" ;
VAL_ 211 PassSeatMovementStat 0 "Default" 1 "Seat Fully Folded" 2 "Seat Fully Unfolded" 3 "Seat Mid Travel (Stationary)" 4 "Seat Moving (Passenger Seat is Moving)" 5 "Passenger Seat Away (Fully Front Seat Away)" 6 "Reserved" 7 "Returned to Home" 8 "One Touch Reclined" 9 "In Safe Position 1" 10 "In Safe Position 2" 11 "In Safe Position 3" 12 "Undefined12" 13 "Undefined13" 14 "Undefined14" 15 "Seat in Undefined Position (Passenger Seat is in Other Position)" ;
VAL_ 211 PassSeatMoveSelStat 0 "Passenger Seat Not Selected" 1 "Passenger Seat Selected" ;
VAL_ 211 PassSeatMovmnt2ndRow 0 "Default" 1 "Seat Fully folded" 2 "Seat Fully Unfolded" 3 "Seat mid travel (stationary)" 4 "Seat moving" ;
VAL_ 211 PassSeatMovmnt3rdRow 0 "Default" 1 "Seat Fully folded" 2 "Seat Fully Unfolded" 3 "Seat mid travel (stationary)" 4 "Seat moving" ;
VAL_ 211 PassSeatOccupantStatus 0 "Passenger Seat Unoccupied" 1 "Passenger Seat Occupied" ;
VAL_ 211 PassSeatPSAStat 0 "Not in PSA Mode" 1 "In PSA Mode" ;
VAL_ 211 Row1PassMovementINH 0 "Not Inhibited" 1 "Movement Inhibited" ;
VAL_ 211 Row2PassMovementINH 0 "Not Inhibited" 1 "Movement Inhibited" ;
VAL_ 211 Row3PassMovementINH 0 "Not Inhibited" 1 "Movement Inhibited" ;
VAL_ 211 RPSeatMovement 0 "No Passenger Seat Movement" 1 "Passenger Seat Movement" ;
VAL_ 213 FoldAllSeatsReqPSM 0 "Fold All Request Disabled" 1 "Fold All Request Enabled" ;
VAL_ 213 R2ISCM60SeatCancelPSM 0 "Not cancelled" 1 "Movement cancelled" ;
VAL_ 213 R2ISCM60SeatInSP1PSM 0 "Seat not in Safe position " 1 "Seat in Safe position" ;
VAL_ 213 R3RightSeatISCMCancPSM 0 "Not cancelled" 1 "Movement cancelled" ;
VAL_ 213 R3RightSeatISCMReqPSM 0 "IDLE" 1 "Row 3 Right Seat Folding in Zone 1" 2 "Row 3 Right Seat Folding in Zone 2" 3 "Row 3 Right Seat Folding in Zone 3" 4 "Row 3 Right Seat Unfolding in Zone 3" 5 "Row 3 Right Seat Unfolding in Zone 2" 6 "Row 3 Right Seat Unfolding in Zone 1" ;
VAL_ 213 RockerSwitch1ReqPSM_a 0 "Off" 1 "Up" 2 "Auto Up" 3 "Down" 4 "Auto Down" ;
VAL_ 213 RockerSwitch1ReqPSM_b 0 "Off" 1 "Up" 2 "Auto Up" 3 "Down" 4 "Auto Down" ;
VAL_ 213 RockerSwitch2ReqPSM_a 0 "Off" 1 "Up" 2 "Auto Up" 3 "Down" 4 "Auto Down" ;
VAL_ 213 RockerSwitch2ReqPSM_b 0 "Off" 1 "Up" 2 "Auto Up" 3 "Down" 4 "Auto Down" ;
VAL_ 213 RRSeatMsgAvailFrInt 0 "Not Available" 1 "Available" ;
VAL_ 213 RRSeatMsgModStatFrInt 0 "StandBy status" 1 "Program 1" 2 "Program 2" 3 "Program 3" 4 "Massage off" ;
VAL_ 213 RRSeatMsgModStatInt 0 "StandBy status" 1 "Program 1" 2 "Program 2" 3 "Program 3" 4 "Massage off" ;
VAL_ 213 RRSeatMsgStatFrInt 0 "Off" 1 "On" ;
VAL_ 213 UnFoldAllSeatsReqPSM 0 "UnFold All Request Disabled" 1 "UnFold All Request Enabled" ;
VAL_ 1002 PassStSetngAppl 0 "Settings not applied" 1 "Settings applied" ;
VAL_ 1002 PSMReqBusAwake 0 "Node not requesting bus keepawake." 1 "Node requesting bus keepawake." ;
VAL_ 191 CrashAirbagStatus 0 "Both driver airbag and passenger airbag not deployed" 1 "Only driver airbag deployed" 2 "Only passenger airbag deployed" 3 "Both driver & passenger airbags are deployed" ;
VAL_ 191 CrashOccClassStatus 0 "OCS not fitted" 1 "OCS Empty inhibit" 2 "OCS Occupied small inhibit" 3 "OCS Occupied large allow" ;
VAL_ 191 CrashPACOSSwitchState 0 "PACOS not fitted" 1 "PACOS OFF" 2 "PACOS ON" 3 "Unused" ;
VAL_ 191 CrashPretensionerStat 0 "Both driver pretensioner and passenger pretensioner not deployed" 1 "Only driver pretensioner deployed" 2 "Only passenger pretensioner deployed" 3 "Both driver & passenger pretensioners are deployed" ;
VAL_ 191 CrashSeatBeltBcklState 0 "Both Driver & Passenger not belted" 1 "Only driver belted" 2 "Only passenger belted" 3 "Both Driver & Passenger are belted" ;
VAL_ 191 CrashSeverityClass 0 "No frontal event" 1 "Frontal event pretensioner threshold met" 2 "Frontal event stage 1 airbag threshold met" 3 "Frontal event stage 2 airbag threshold met" ;
VAL_ 191 CrashSideAirbagStatus 0 "No Side airbags/curtainairbags deployed" 1 "Left side airbag/curtain deployed" 2 "Right side airbag/curtain deployed" 3 "Both side airbags/curtains deployed" ;
VAL_ 191 CrashStatusPIE 0 "No Pedestrain Crash" 1 "Pedestrain Crash Detected" ;
VAL_ 191 CrashStatusRCM 0 "No crash" 1 "Crash condition" ;
VAL_ 191 CrashTypeFront 0 "No Crash" 1 "Crash" ;
VAL_ 191 CrashTypeRear 0 "No Crash" 1 "Crash" ;
VAL_ 191 CrashTypeRoll 0 "No rollover" 1 "Vehicle rollover" ;
VAL_ 191 CrashTypeSide 0 "No Crash" 1 "Crash" ;
VAL_ 191 DrivSeatBeltBcklError 0 "No Fault" 1 "Fault Condition" ;
VAL_ 191 DrivSeatBeltBcklState 0 "Not Latched" 1 "Latched" ;
VAL_ 191 DrivSeatPositionError 0 "No Fault" 1 "Fault" ;
VAL_ 191 DrivSeatPositionStatus 0 "Rearward (normal / large occupant)" 1 "Forward (small occupant)" ;
VAL_ 191 KeepNetInAfterRunRCM 0 "Function does not need the network" 1 "Function does need the network" ;
VAL_ 191 PassSeatBeltBcklError 0 "No Fault" 1 "Fault Condition" ;
VAL_ 191 PassSeatBeltBcklState 0 "Not Latched" 1 "Latched" ;
VAL_ 191 PassSeatPositionStatus 0 "Rearward (normal / large occupant)" 1 "Forward (small occupant)" ;
VAL_ 191 VerticalAcceleration 4095 "Fault" ;
VAL_ 74 A1_STAT 0 "sensor ok" 1 "sensor element not populated" 2 "signal faulty" 3 "invalid value (signal faulty) 3" 4 "sensor initialising" 5 "invalid value5" 6 "invalid value (signal faulty) 6" 7 "invalid value (signal faulty) 7" 8 "sensor channel not calibrated" 9 "sensor not calibrated / not populated " 10 "invalid value (signal faulty) 10" 11 "invalid value (signal faulty) 11" 12 "initialising / not calibrated" 13 "invalid value13" 14 "invalid value (signal faulty) 14" 15 "invalid value (signal faulty) 15" ;
VAL_ 74 PSIP1_STAT 0 "sensor ok" 1 "sensor element not populated" 2 "signal faulty" 3 "invalid value (signal faulty) 3" 4 "sensor initialising" 5 "invalid value5" 6 "invalid value (signal faulty) 6" 7 "invalid value (signal faulty) 7" 8 "sensor channel not calibrated" 9 "sensor not calibrated / not populated " 10 "invalid value (signal faulty) 10" 11 "invalid value (signal faulty) 11" 12 "initialising / not calibrated" 13 "invalid value13" 14 "invalid value (signal faulty) 14" 15 "invalid value (signal faulty) 15" ;
VAL_ 76 A2_STAT 0 "sensor ok" 1 "sensor element not populated" 2 "signal faulty" 3 "invalid value (signal faulty) 3" 4 "sensor initialising" 5 "invalid value5" 6 "invalid value (signal faulty) 6" 7 "invalid value (signal faulty) 7" 8 "sensor channel not calibrated" 9 "sensor not calibrated / not populated " 10 "invalid value (signal faulty) 10" 11 "invalid value (signal faulty) 11" 12 "initialising / not calibrated" 13 "invalid value13" 14 "invalid value (signal faulty) 14" 15 "invalid value (signal faulty) 15" ;
VAL_ 76 PSIPP1_STAT 0 "sensor ok" 1 "sensor element not populated" 2 "signal faulty" 3 "invalid value (signal faulty) 3" 4 "sensor initialising" 5 "invalid value5" 6 "invalid value (signal faulty) 6" 7 "invalid value (signal faulty) 7" 8 "sensor channel not calibrated" 9 "sensor not calibrated / not populated " 10 "invalid value (signal faulty) 10" 11 "invalid value (signal faulty) 11" 12 "initialising / not calibrated" 13 "invalid value13" 14 "invalid value (signal faulty) 14" 15 "invalid value (signal faulty) 15" ;
VAL_ 330 KeyScanImminent 0 "No key scan, charging pads on" 1 "Key scan imminent, turn off charging pads" ;
VAL_ 330 PEChargingInletLockCmd 0 "No Request to Unlock Socket" 1 "Request to Unlock Socket" ;
VAL_ 330 PLockSwStatusDD 0 "Lock button NOT pressed" 1 "Lock button pressed" ;
VAL_ 330 PLockSwStatusPD 0 "Lock button NOT pressed" 1 "Lock button pressed" ;
VAL_ 330 PLockSwStatusRL 0 "Lock button NOT pressed" 1 "Lock button pressed" ;
VAL_ 330 PLockSwStatusRR 0 "Lock button NOT pressed" 1 "Lock button pressed" ;
VAL_ 330 PLockSwStatusTrunk 0 "Lock button NOT pressed" 1 "Lock button pressed" ;
VAL_ 330 PUnlockSwStatusDD 0 "Unlock button NOT pressed" 1 "Unlock button pressed" ;
VAL_ 330 PUnlockSwStatusPD 0 "Unlock button NOT pressed" 1 "Unlock button pressed" ;
VAL_ 330 PUnlockSwStatusRL 0 "Unlock button NOT pressed" 1 "Unlock button pressed" ;
VAL_ 330 PUnlockSwStatusRR 0 "Unlock button NOT pressed" 1 "Unlock button pressed" ;
VAL_ 330 PUnlockSwStatusTGlass 0 "Unlock button NOT pressed" 1 "Unlock button pressed" ;
VAL_ 330 PUnlockSwStatusTrunk 0 "Unlock button NOT pressed" 1 "Unlock button pressed" ;
VAL_ 330 RFAReqBusAwake 0 "Node not requesting bus keepawake." 1 "Node requesting bus keepawake." ;
VAL_ 483 PELockButtonReq 0 "Not used" 1 "Driver Door" 2 "Passenger Door" 3 "Left Rear Door" 4 "Right Rear Door" 7 "Not Activated" ;
VAL_ 483 PKeyIdScanArea 0 "Ignore" 1 "Left side" 2 "Right side" 3 "Rear" 4 "Interior" 5 "Unused5" 6 "Unused6" 7 "Unused7" ;
VAL_ 483 PKeyIdsInAreaReported 0 "Ignore" 1 "Only 1 key found in area is being reported" 2 "PKeyId includes all keys found in the scan area" 3 "Unused" ;
VAL_ 484 PEPullSwitchStatus 0 "Not Used" 1 "Driver Door" 2 "Passenger Door" 3 "Left Rear Door" 4 "Right Rear Door" 5 "Tailgate" ;
VAL_ 484 PKBattStatus 0 "Battery OK" 1 "Low Battery" ;
VAL_ 484 PkeyScanComp 0 "Key scanning not complete" 1 "Key scanning complete" ;
VAL_ 484 PKeyWarningInd 0 "No Warning" 1 "Passive Key Lost" ;
VAL_ 484 PLockRequestDD 0 "Ignore" 1 "Lock button pressed with a valid key present" ;
VAL_ 484 PLockRequestPD 0 "Ignore" 1 "Lock button pressed with a valid key present" ;
VAL_ 484 PLockRequestRL 0 "Ignore" 1 "Lock button pressed with a valid key present" ;
VAL_ 484 PLockRequestRR 0 "Ignore" 1 "Lock button pressed with a valid key present" ;
VAL_ 484 PLockRequestTrunk 0 "Ignore" 1 "Lock button pressed with a valid key present" ;
VAL_ 484 PUnlockRequestDD 0 "Ignore" 1 "Unlock button pressed with a valid key present" ;
VAL_ 484 PUnlockRequestPD 0 "Ignore" 1 "Unlock button pressed with a valid key present" ;
VAL_ 484 PUnlockRequestRL 0 "Ignore" 1 "Unlock button pressed with a valid key present" ;
VAL_ 484 PUnlockRequestRR 0 "Ignore" 1 "Unlock button pressed with a valid key present" ;
VAL_ 484 PUnlockRequestTGlass 0 "Ignore" 1 "Unlock button pressed with a valid key present" ;
VAL_ 484 PUnlockRequestTrunk 0 "Ignore" 1 "Unlock button pressed with a valid key present" ;
VAL_ 486 ImmoPKeyApproved 0 "Passive Key Not Approved" 1 "Passive Key Approved" ;
VAL_ 480 PCUStatus 0 "PCU in home position" 1 "PCU closing" 2 "PCU returning" 3 "PCU position unknown" ;
VAL_ 480 POTSecondaryLatchSt 0 "Unlatched" 1 "Closed / Latched" ;
VAL_ 480 PowerTailgateStatus 0 "Idle (fully closed/fully open)" 1 "Opening" 2 "Closing" 3 "Stopped (during open/close action)" ;
VAL_ 480 PwrTGCloseInProg 0 "No Power Close in Progress" 1 "Power Close in Progress (including post poswer close soft close operation)" ;
VAL_ 480 RGTMReqBusAwake 0 "Node not requesting bus keepawake." 1 "Node requesting bus keepawake." ;
VAL_ 480 UpperTailgateCloseStat 0 "RGTM Upper Tailgate close possible" 1 "RGTM Upper Tailgate close not possible" ;
VAL_ 480 UpperTailgateOpenStat 0 "RGTM Upper Tailgate open possible" 1 "RGTM Upper Tailgate open not possible" ;
VAL_ 430 PKExtScanReqTailgate 0 "Not used" 1 "Activate" ;
VAL_ 430 POTCompleteCloseReq 0 "No request" 1 "Complete Close Request" ;
VAL_ 430 UpperPOTailgatePinch 0 "Anti-Pinch Inactive" 1 "Anti-Pinch Active" ;
VAL_ 430 UpperPwrTGObjectDetect 0 "ObjectDetect Inactive" 1 "ObjectDetect Active - Stop movement" ;
VAL_ 430 UpperTGateMislockWng 0 "No Mislock Error" 1 "Mislock Error" ;
VAL_ 611 LwrTailgateCloseStat 0 "RGTMB Lower Tailgate close possible" 1 "RGTMB Lower Tailgate close not possible" ;
VAL_ 611 LwrTailgateOpenStat 0 "RGTMB Lower Tailgate open possible" 1 "RGTMB Lower Tailgate open not possible" ;
VAL_ 611 PCUStatusLwrLHS 0 "PCU in home position" 1 "PCU closing" 2 "PCU returning" 3 "PCU position unknown." ;
VAL_ 611 PCUStatusLwrRHS 0 "PCU in home position" 1 "PCU closing" 2 "PCU returning" 3 "PCU position unknown." ;
VAL_ 611 POTSecLatchStatLwrLHS 0 "Unlatched" 1 "Closed / Latched" ;
VAL_ 611 POTSecLatchStatLwrRHS 0 "Unlatched" 1 "Closed / Latched" ;
VAL_ 611 PowerTailgateStatusLwr 0 "Idle (fully closed/fully open)" 1 "Opening" 2 "Closing" 3 "Stopped (during open/close action)" ;
VAL_ 611 RGTMBReqBusAwake 0 "Node not requesting bus keepawake." 1 "Node requesting bus keepawake." ;
VAL_ 431 LowerPOTailgatePinch 0 "Anti-Pinch Inactive" 1 "Anti-Pinch Active" ;
VAL_ 431 LowerPwrTGObjectDetect 0 "ObjectDetect Inactive" 1 "ObjectDetect Active - Stop movement" ;
VAL_ 431 LwrTrunkReleaseCmd 0 "No request" 1 "Release tailgate latch(es)" ;
VAL_ 389 PassSeatHghtDownReqRL 0 "Off" 1 "On" ;
VAL_ 389 PassSeatHghtUpReqRL 0 "Off" 1 "On" ;
VAL_ 389 PassSeatHRestAftReqRL 0 "Inactive" 1 "Active" ;
VAL_ 389 PassSeatHRestDwnReqRL 0 "Inactive / Off" 1 "Active / ON" ;
VAL_ 389 PassSeatHRestForeReqRL 0 "Inactive" 1 "Active" ;
VAL_ 389 PassSeatHRestUpReqRL 0 "Inactive / Off " 1 "Active / ON" ;
VAL_ 389 PassSeatInclineReqRL 0 "Off" 1 "On" ;
VAL_ 389 PassSeatMemClrReqRL 0 "Default" 1 "Memory 1 Clear" 2 "Memory 2 Clear" 3 "Memory 3 Clear" ;
VAL_ 389 PassSeatMemClrReqRR 0 "Default" 1 "Memory 1 Clear" 2 "Memory 2 Clear" 3 "Memory 3 Clear" ;
VAL_ 389 PassSeatMemLoadReqRL 0 "Default" 1 "Memory 1 Load" 2 "Memory 2 Load" 3 "Memory 3 Load" ;
VAL_ 389 PassSeatMemStrReqRL 0 "Default" 1 "Memory 1 Store" 2 "Memory 2 Store" 3 "Memory 3 Store" ;
VAL_ 389 PassSeatMoveReqRL 0 "Default" 1 "Return to Upright" 2 "Full Front Seat Away" 3 "One Touch Recline" 4 "Stop Seat Movement" 5 "Move to Safe Position 1" 6 "Move to Safe Position 2" 7 "Move to Safe Position 3" ;
VAL_ 389 PassSeatReclineReqRL 0 "Off" 1 "On" ;
VAL_ 389 PassSeatSlideAftReqRL 0 "Off" 1 "On" ;
VAL_ 389 PassSeatSlideForeReqRL 0 "Off" 1 "On" ;
VAL_ 389 PSARequestRL 0 "PSA not active" 1 "PSA forward" 2 "PSA rearward" 3 "unused" ;
VAL_ 389 RCntrSeatMoveSelStat 0 "Rear Centre Seat Not Selected" 1 "Rear Centre Seat Selected" ;
VAL_ 389 RCntrSeatMovmentStat 0 "Default" 1 "Seat Fully Folded" 2 "Seat Fully Unfolded" 3 "Seat Mid Travel (Stationary)" 4 "Seat Moving" 5 "Deployed (Down Position)" 6 "Stowed (Up Position)" 7 "Reserved7" 8 "Reserved8" 9 "Reserved9" 10 "Reserved10" 11 "Reserved11" 12 "Reserved12" 13 "Reserved13" 14 "Reserved14" 15 "Reserved15" ;
VAL_ 389 RCntrSeatUpperLidStat 0 "Closed" 1 "Open" ;
VAL_ 389 RearLeftCancelSeat 0 "Off" 1 "On" ;
VAL_ 389 RearSeatFoldFlatReqRL 0 "Rear seat fully unfolded" 1 "Rear seat outside the clash zone" 2 "Rear seat inside the clash zone" 3 "Seat fully folded" ;
VAL_ 389 RLSMSeatMovement 0 "No Rear Seat Movement" 1 "Rear Seat Movement" ;
VAL_ 389 RMSeatInhib2ndRow 0 "Available to receive a seat movement request" 1 "Seat movement is Inhibited" ;
VAL_ 390 RLeftTableDeployed 0 "Table Not Deployed" 1 "Table Deployed" ;
VAL_ 390 RLSeatCalfRestStat 0 "Default Position (Fully Stowed)" 1 "In Design Position 1 ( Mid Travel 1)" 2 "In Design Position 2 ( Mid Travel 2)" 3 "In Design Position 3 ( Fully Deployed)" ;
VAL_ 390 RLSeatFoldFlatReq 0 "Not active" 1 "Rear seat folding in zone 1 (outside clash zone)" 2 "Rear seat folding in zone 2 (inside clash zone)" 3 "Rear seat folding in zone 3 " 4 "Not used" 5 "Rear seat unfolding in zone 1 (outside clash zone)" 6 "Rear seat unfolding in zone 2 (inside clash zone)" 7 "Rear seat unfolding in zone 3 " ;
VAL_ 390 RLSeatFootRestReq 0 "Footrest Retract" 1 "Footrest Deploy" ;
VAL_ 390 RLSeatInhib2ndRow 0 "Available to receive a seat movement request" 1 "Seat movement is Inhibited" ;
VAL_ 390 RLSeatMasgIntStat 0 "StandBy Status" 1 "Intensity 1" 2 "Intensity 2" 3 "Intensity 3" 4 "Intensity 4" 5 "Intensity 5" 6 "Off" 7 "Unused" ;
VAL_ 390 RLSeatMasgLocStat 0 "Off" 1 "Rolling" 2 "Up" 3 "Down" 4 "Shoulder" 5 "Lumbar" 6 "Undefined6" 7 "Undefined7" ;
VAL_ 390 RLSeatMasgModeStatFr 0 "StandBy status(No button press)" 1 "Program 1" 2 "Program 2" 3 "Program 3" 4 "Massage OFF" ;
VAL_ 390 RLSeatMasgProgStat 0 "Off" 1 "Wave" 2 "Pulse" 3 "Pulse Duo" 4 "Combination" 5 "Hot" 6 "Undefined6" 7 "Undefined7" ;
VAL_ 390 RLSeatMasgStatFr 0 "Off" 1 "On" ;
VAL_ 390 RLSeatMassageModeStat 0 "StandBy status(No button press)" 1 "Standard" 2 "Soft" 3 "Vigorous" 4 "Massage OFF" ;
VAL_ 390 RLSeatMemLoadStat 0 "Default" 1 "Memory 1 Recalled" 2 "Memory 2 Recalled" 3 "Memory 3 Recalled" ;
VAL_ 390 RLSeatMemStorStat 0 "Default" 1 "Memory 1 Stored" 2 "Memory 2 Stored" 3 "Memory 3 Stored" ;
VAL_ 390 RLSeatMovementStat 0 "Default" 1 "Seat Fully Folded" 2 "Seat Fully Unfolded" 3 "Seat Mid Travel (Stationary)" 4 "Seat Moving" 5 "One Touch Reclined" 6 "Fully Reclined" 7 "Returned to Home" ;
VAL_ 390 RLSeatMoveSelStat 0 "Rear Left Seat Not Selected" 1 "Rear Left Seat Selected" ;
VAL_ 390 RLSeatMsgAvailFr 0 "Available" 1 "NOT available" ;
VAL_ 530 RightPowerDoorStatus 0 "Unknown" 1 "Normal" 2 "Closing" 3 "Body angle exceeds closing limit" 4 "Body angle exceeds holding limit" 5 "Door closing obstruction" 6 "Temperature too low for operation" 7 "Temperature too high for operation" 8 "Insufficient power available for operation" 9 "Reserved9" 10 "Reserved10" 11 "Reserved11" 12 "Reserved12" 13 "Reserved13" 14 "Reserved14" 15 "Fault" ;
VAL_ 682 PassSeatHghtDownReqRR 0 "Off" 1 "On" ;
VAL_ 682 PassSeatHghtUpReqRR 0 "Off" 1 "On" ;
VAL_ 682 PassSeatHRestAftReqRR 0 "Inactive" 1 "Active" ;
VAL_ 682 PassSeatHRestDwnReqRR 0 "Inactive / Off" 1 "Active / ON" ;
VAL_ 682 PassSeatHRestForeReqRR 0 "Inactive" 1 "Active" ;
VAL_ 682 PassSeatHRestUpReqRR 0 "Inactive / Off" 1 "Active / ON" ;
VAL_ 682 PassSeatInclineReqRR 0 "Off" 1 "On" ;
VAL_ 682 PassSeatMemLoadReqRR 0 "Default" 1 "Memory 1 Load" 2 "Memory 2 Load" 3 "Memory 3 Load" ;
VAL_ 682 PassSeatMemStrReqRR 0 "Default" 1 "Memory 1 Store" 2 "Memory 2 Store" 3 "Memory 3 Store" ;
VAL_ 682 PassSeatMoveReqRR 0 "Default" 1 "Return to Upright" 2 "Full Front Seat Away" 3 "One Touch Recline" 4 "Stop Seat Movement" 5 "Move to Safe Position 1" 6 "Move to Safe Position 2" 7 "Move to Safe Position 3" ;
VAL_ 682 PassSeatReclineReqRR 0 "Off" 1 "On" ;
VAL_ 682 PassSeatSlideAftReqRR 0 "Off" 1 "On" ;
VAL_ 682 PassSeatSlideForeReqRR 0 "Off" 1 "On" ;
VAL_ 682 PSARequestRR 0 "PSA not active" 1 "PSA forward" 2 "PSA rearward" 3 "unused" ;
VAL_ 682 RearLeftFoldSwStat 0 "Not Pressed" 1 "Pressed" ;
VAL_ 682 RearLeftUnfoldSwStat 0 "Not Pressed" 1 "Pressed" ;
VAL_ 682 RearRightCancelSeat 0 "Off" 1 "On" ;
VAL_ 682 RearSeatFoldFlatReqRR 0 "Rear seat fully unfolded" 1 "Rear seat outside the clash zone" 2 "Rear seat inside the clash zone" 3 "Seat fully folded" ;
VAL_ 682 RRightTableDeployed 0 "Table Not Deployed" 1 "Table Deployed" ;
VAL_ 682 RRSeatCalfRestStat 0 "Default Position (Fully Stowed)" 1 "In Design Position 1 ( Mid Travel 1)" 2 "In Design Position 2 ( Mid Travel 2)" 3 "In Design Position 3 ( Fully Deployed)" ;
VAL_ 682 RRSeatFoldFlatReq 0 "Not active " 1 "Rear seat folding in zone 1 (outside clash zone)" 2 "Rear seat folding in zone 2 (inside clash zone)" 3 "Rear seat folding in zone 3 " 4 "Not used" 5 "Rear seat unfolding in zone 1 (outside clash zone)" 6 "Rear seat unfolding in zone 2 (inside clash zone)" 7 "Rear seat unfolding in zone 3 " ;
VAL_ 682 RRSeatFootRestReq 0 "Footrest Retract" 1 "Footrest Deploy" ;
VAL_ 682 RRSeatInhib2ndRow 0 "Available to receive a seat movement request" 1 "Seat movement is Inhibited" ;
VAL_ 682 RRSeatMasgAvailFr 0 "Available" 1 "NOT available" ;
VAL_ 682 RRSeatMasgIntStat 0 "StandBy Status" 1 "Intensity 1" 2 "Intensity 2" 3 "Intensity 3" 4 "Intensity 4" 5 "Intensity 5" 6 "Off" 7 "Unused" ;
VAL_ 682 RRSeatMasgLocStat 0 "Off" 1 "Rolling" 2 "Up" 3 "Down" 4 "Shoulder" 5 "Lumbar" 6 "Undefined6" 7 "Undefined7" ;
VAL_ 682 RRSeatMasgModeStatFr 0 "StandBy status(No button press)" 1 "Program 1" 2 "Program 2" 3 "Program 3" 4 "Massage OFF" ;
VAL_ 682 RRSeatMasgProgStat 0 "Off" 1 "Wave" 2 "Pulse" 3 "Pulse Duo" 4 "Combination" 5 "Hot" 6 "Undefined6" 7 "Undefined7" ;
VAL_ 682 RRSeatMasgStatFr 0 "Off" 1 "On" ;
VAL_ 682 RRSeatMemLoadStat 0 "Default" 1 "Memory 1 Recalled" 2 "Memory 2 Recalled" 3 "Memory 3 Recalled" ;
VAL_ 682 RRSeatMemStorStat 0 "Default" 1 "Memory 1 Stored" 2 "Memory 2 Stored" 3 "Memory 3 Stored" ;
VAL_ 682 RRSeatMovementStat 0 "Default" 1 "Seat Fully Folded" 2 "Seat Fully Unfolded" 3 "Seat Mid Travel (Stationary)" 4 "Seat Moving" 5 "One Touch Reclined" 6 "Fully Reclined" 7 "Returned to Home" ;
VAL_ 682 RRSeatMoveSelStat 0 "Rear Right Seat Not Selected" 1 "Rear Right Seat Selected" ;
VAL_ 682 RRSMSeatMovement 0 "No Rear Seat Movement" 1 "Rear Seat Movement" ;
VAL_ 682 SkiHatchStat 0 "Closed" 1 "Open" ;
VAL_ 682 SkiHatchSwitchStat 0 "Not Pressed" 1 "Pressed" ;
VAL_ 86 SteeringWheelAngle 65535 "Error Marker" ;
VAL_ 86 SteeringWheelAngleSpeed 255 "Fault Condition Present" ;
VAL_ 86 SteeringWheelAngleStatus 0 "Fault condition" 1 "Steering angle not known or not initialised" 2 "Centre not confirmed (unused on L405)" 3 "Centre confirmed" ;
VAL_ 86 SteeringWheelRotDir 0 "Rotation Counterclockwise" 1 "Rotation Clockwise" ;
VAL_ 379 PassSeatMasgIntStat 0 "StandBy Status" 1 "Intensity 1" 2 "Intensity 2" 3 "Intensity 3" 4 "Intensity 4" 5 "Intensity 5" 6 "Off" 7 "Unused" ;
VAL_ 379 PassSeatMasgLocStat 0 "Off" 1 "Rolling" 2 "Up" 3 "Down" 4 "Shoulder" 5 "Lumbar" 6 "Undefined6" 7 "Undefined7" ;
VAL_ 379 PassSeatMasgProgStat 0 "Off" 1 "Wave" 2 "Pulse" 3 "Pulse Duo" 4 "Combination" 5 "Hot" 6 "Undefined6" 7 "Undefined7" ;
VAL_ 379 PassSeatMassageModeStat 0 "StandBy status(No button press)" 1 "Program 1" 2 "Program 2" 3 "Program 3" 4 "Massage OFF" 5 "Program 4" 6 "Program 5" 7 "Unused" ;
VAL_ 379 PassSeatMassageStat 0 "Off" 1 "On" ;
VAL_ 379 PassSeatMsgAvail 0 "Available" 1 "NOT available" ;
VAL_ 503 ActivateBlower 0 "Inactive / OFF" 1 "Active / ON" ;
VAL_ 503 AIR_LowerSwitchStatus 0 "Switch open" 1 "Switch closed" ;
VAL_ 503 AIR_RaiseSwitchStatus 0 "Switch open" 1 "Switch closed" ;
VAL_ 503 BSCMBrakeLightRequest 0 "no brake light activation" 1 "brake light activation" ;
VAL_ 503 EmergencyBrakingStatus 0 "No EBL request" 1 "EBL request" ;
VAL_ 503 FirstGearManual 0 "Gearbox not in first gear" 1 "Gearbox in first gear" ;
VAL_ 503 GSAPosStatus 0 "Park" 1 "Reverse" 2 "Neutral" 3 "Drive" 4 "RESERVED4" 5 "RESERVED5" 6 "RESERVED6" 7 "Sport" 8 "RESERVED8" 9 "RESERVED9" 10 "RESERVED10" 11 "RESERVED11" 12 "RESERVED12" 13 "RESERVED13" 14 "Fault" 15 "Unconfirmed" ;
VAL_ 503 InteriorVentMovingStat 0 "Vent motor no motion" 1 "Vent Motor position change warning" ;
VAL_ 503 LSMMirrorFoldReq 0 "No request" 1 "Fold" 2 "Unfold" 3 "Reserved" ;
VAL_ 503 MHLampStatus 0 "Lamp Off" 1 "Lamp On" ;
VAL_ 503 StartModeAck 0 "None" 1 "Smart" 2 "Normal" 3 "Fault" 4 "Limited" 5 "Remote" 6 "StartInhibited" 7 "Reserved" ;
VAL_ 503 WakeNetForPreRunHVAC 0 "ECU does not require the Network" 1 "ECU requires the Network" ;
VAL_ 504 CrankRelayStatus 0 "Engine not cranking" 1 "Engine cranking" ;
VAL_ 504 EngineRunningStatus 0 "Engine NOT running." 1 "Engine running." ;
VAL_ 504 GearPosActual 0 "Neutral/Park" 1 "First" 2 "Second" 3 "Third" 4 "Fourth" 5 "Fifth" 6 "Sixth" 7 "Seventh" 8 "Eighth" 9 "Ninth" 10 "Reserved Position10" 11 "Reserved Position11" 12 "Reverse" 13 "Reserved Position13" 14 "EV Drive" 15 "Shift-In Progress / Fault" ;
VAL_ 504 LaserStatus 0 "on" 1 "off" 2 "laser signal input failure" 3 "laser hardware failure" 15 "signal not valid" ;
VAL_ 504 LSMDirIndReq 0 "No request" 1 "Left only requested" 2 "Right only requested" 3 "Both requested" ;
VAL_ 504 LSMExteriorLightsReq 0 "No request" 1 "Main beam requested" 2 "RESERVED2" 3 "RESERVED1" ;
VAL_ 761 CDiffRangeActual 0 "Low range" 1 "Neutral/Fault" 2 "High range" 3 "Range change in process" ;
VAL_ 761 EPBBrakeLightReq 0 "off" 1 "on" ;
VAL_ 761 HWJLoadStatus 0 "Off" 1 "On" ;
VAL_ 761 NeutralManual 0 "Manaul transmission not in neutral " 1 "Manual transmission in neutral" 2 "Reserved (not used)" 3 "Switch fault" ;
VAL_ 761 OuterMirrorDefCmd 0 "Off" 1 "On" ;
VAL_ 761 ParkClimateMode 0 "off" 1 "startup" 2 "engine heating" 3 "cabin heating" 4 "cabin venting" ;
VAL_ 761 RestHeatStatus 0 "Off" 1 "On" ;
VAL_ 761 RLSeatMassageModeReq 0 "StandBy status(No button press)" 1 "Standard" 2 "Soft" 3 "Vigorous" 4 "Massage OFF" ;
VAL_ 761 RRSeatMassageModeReq 0 "StandBy status(No button press)" 1 "Standard" 2 "Soft" 3 "Vigorous" 4 "Massage OFF" ;
VAL_ 761 WaterPumpReq 0 "Pump OFF" 1 "Pump ON" ;
VAL_ 197 ABRCTAEventStatus 0 "NO_EVENT" 1 "ABRCTA_EVENT" ;
VAL_ 197 ABRCTAMonitoringMode 0 "ON" 1 "OFF" 2 "Unavailable" 3 "Reserved" ;
VAL_ 197 ABRCTASystemState 0 "ABRCTA Normal" 1 "Reserved1" 2 "ABRCTA System Fault" 3 "Reserved3" ;
VAL_ 197 ARAAlertLeft 0 "Alert off" 1 "Alert on with sound" 2 "Alert on without sound" 3 "reserved" ;
VAL_ 197 AVCMLeftTargetDet 0 "No target detected" 1 "Target detected" ;
VAL_ 197 BSMLeftAlert 0 "Lamp Off" 1 "Lamp On" ;
VAL_ 197 BSMLeftBlocked 0 "Sensor not Blocked" 1 "Sensor Blocked" ;
VAL_ 197 BSMLeftCVWAlert 0 "Lamp OFF" 1 "Lamp ON" ;
VAL_ 197 BSMLeftSensorState 0 "Undefined" 1 "Initialization" 2 "Initialization Complete" 3 "System Disabled" 4 "System Faulty" 5 "System Standby" 6 "Sensor Blocked" 7 "Not Reporting" 8 "Reporting" 9 "CTA_ACTIVE" 10 "CTA_NOT_AVAILABLE" 11 "CTA_NOT_REPORTING" 12 "SENSOR_STATE_RESERVED0(USED FOR LOW_LEVEL_TEST_MODE)" 13 "SENSOR_STATE_RESERVED1" 14 "SENSOR_STATE_RESERVED2" 15 "SENSOR_STATE_RESERVED3" ;
VAL_ 197 BSMLeftServiceRequired 0 "Lamp Off" 1 "Lamp On - Error present" ;
VAL_ 197 BSMLeftUnavailable 0 "Sensor is available" 1 "Sensor is not available" ;
VAL_ 197 BSMMonitoringMode 0 "Undefined" 1 "Disabled by Driver" 2 "On with Ignition" 3 "Alert with Turn Signal" ;
VAL_ 197 BSMSystemState 0 "System Normal" 1 "Sensor Blockage" 2 "System Fault" 3 "ARAFault" ;
VAL_ 197 LeftREDAlert 0 "System Inactive" 1 "System Active" 2 "RED Alert" 3 "FOV Obstructed" ;
VAL_ 197 RCTAStatus 0 "ON" 1 "OFF" 2 "Unavailable" 3 "Reserved" ;
VAL_ 197 RPCStatus 0 "Disabled" 1 "Standby" 2 "Active" 3 "Fault" 4 "Blocked" 5 "Reserved5" 6 "Reserved6" 7 "Reserved7" ;
VAL_ 197 RPCUserModeStatus 0 "ON" 1 "OFF" 2 "Unavailable" 3 "Reserved" ;
VAL_ 197 SODGlobalActuatorReq 0 "No Request" 1 "RPC Request" 2 "Reserved2" 3 "Reserved3" ;
VAL_ 197 SODLightingRequest 0 "No Request" 1 "RPC" ;
VAL_ 196 ARAAlertRight 0 "Alert off" 1 "Alert on with sound" 2 "Alert on without sound" 3 "reserved" ;
VAL_ 196 ARAMonitoringMode 0 "Undefined" 1 "Disabled by Driver" 2 "On with Ignition" ;
VAL_ 196 AVCMRightTargetDet 0 "No target detected" 1 "Target detected" ;
VAL_ 196 BSMRightAlert 0 "Lamp Off" 1 "Lamp On" ;
VAL_ 196 BSMRightCVWAlert 0 "Lamp OFF" 1 "Lamp ON" ;
VAL_ 196 BSMRightSensorState 0 "Undefined" 1 "Initialization" 2 "Initialization Complete" 3 "System Disabled" 4 "System Faulty" 5 "System Standby" 6 "Sensor Blocked" 7 "Not Reporting" 8 "Reporting" 9 "CTA_ACTIVE" 10 "CTA_NOT_AVAILABLE" 11 "CTA_NOT_REPORTING" 12 "SENSOR_STATE_RESERVED0(USED FOR LOW_LEVEL_TEST_MODE)" 13 "SENSOR_STATE_RESERVED1" 14 "SENSOR_STATE_RESERVED2" 15 "SENSOR_STATE_RESERVED3" ;
VAL_ 196 RightREDAlert 0 "System Inactive" 1 "System Active" 2 "RED Alert" 3 "FOV Obstructed" ;
VAL_ 196 SODFeatureRequest 0 "None" 1 "ABRCTA" 2 "RPC" 3 "RESERVED5" 4 "RESERVED4" 5 "RESERVED3" 6 "RESERVED2" 7 "RESERVED1" ;
VAL_ 196 SODLStatus 0 "No Fault" 1 "Fault" 2 "SOD Blocked" 3 "RESERVED5" 4 "RESERVED4" 5 "RESERVED3" 6 "RESERVED2" 7 "RESERVED1" ;
VAL_ 196 SODRStatus 0 "No Fault" 1 "SODR Blocked" 2 "SODR Fault" 3 "Reserved3" 4 "Reserved4" 5 "Reserved5" 6 "Reserved6" 7 "Reserved7" ;
VAL_ 485 GeneralSideStepStatus 0 "Operational/No failure" 1 "Side Steps Inhibited" 2 "Side Step System Failure" 3 "Reserved" ;
VAL_ 485 LHSideStepFailStatus 0 "Operation /No Failure" 1 "Stowing Obstruction" 2 "Deployment Obstruction" 3 "Side step Failure" ;
VAL_ 485 LHSideStepStatus 0 "Fully Stowed" 1 "1/4 Deployed" 2 "1/2 Deployed" 3 "3/4 Deployed" 4 "Fully Deployed" 5 "Reserved5" 6 "Reserved6" 7 "Reserved7" ;
VAL_ 485 RHSideStepFailStatus 0 "Operation /No Failure" 1 "Stowing Obstruction" 2 "Deployment Obstruction" 3 "Side step Failure" ;
VAL_ 485 RHSideStepStatus 0 "Fully Stowed" 1 "1/4 Deployed" 2 "1/2 Deployed" 3 "3/4 Deployed" 4 "Fully Deployed" 5 "Reserved5" 6 "Reserved6" 7 "Reserved7" ;
VAL_ 485 SideStepsModeRes 0 "Off" 1 "Roof Access Mode" 2 "Terrain Response Override" 3 "Normal/On" ;
VAL_ 485 TowBarDeployPosition 0 "stowed and locked" 63 "deployed and locked" ;
VAL_ 485 TowBarGeneralStatus 0 "Operational/No failure" 1 "TowBar Inhibited" 2 "TowBar System Failure" 3 "TowBar inhibited because trailer is connected" ;
VAL_ 485 TowBarLoad 121 "Negative nose load" 122 "Overloaded" 127 "Load unknown" ;
VAL_ 485 TowBarLoadMeasStat 0 "Measurement idle" 1 "Measurement in progress" 2 "Measurement failed" 3 "Measurement done, tolerance larger of +/-5 kg or +/-5%" 4 "Measurement done, tolerance larger of +/-10 kg or +/-10%" 5 "Measurement done, tolerance larger of +/-15 kg or +/-15%" 6 "Measurement done, tolerance larger of +/-20 kg or +/-20%" 7 "Measurement needs towbar to be stowed and deployed" ;
VAL_ 485 TowBarObstructStatus 0 "No obstruction" 1 "Obstruction towards stowed" 2 "Obstruction towards deployed" 3 "Reserved" ;
VAL_ 485 TowBarOperationStatus 0 "Sleeping" 1 "Unlocking in stowed Position" 2 "Locking in stowed position" 3 "Unlocking in deployed position" 4 "Locking in deployed Position" 5 "Unlocked Moving Towards Deployed" 6 "Unlocked Moving Towards Stowed" 7 "Locked in Deployed Position" 8 "Locked in Stowed position" 9 "stopped, not locked, in stowed position" 10 "stopped, not locked, in deployed position" 11 "stopped, not locked, between stowed and deployed" 15 "Unknown" ;
VAL_ 485 TrailerDILeftFailed 0 "Passed" 1 "Failed/No Connection" ;
VAL_ 485 TrailerDIRightFailed 0 "Passed" 1 "Failed/No Connection" ;
VAL_ 485 TrailerStopLampFailed 0 "Passed" 1 "Failed/No Connection" ;
VAL_ 645 TBMTrailerLightTestReq 0 "No action" 1 "Turn on or off" ;
VAL_ 645 TrailerConnTestReq 0 "Off" 1 "Request Cold Monitor task" ;
VAL_ 385 CDiffActuatorTempStatD7a 0 "Normal temperature" 1 "High temperature threshold exceeded" 2 "Limit temperature threshold exceeded" 3 "Reserved" ;
VAL_ 385 CDiffClutchFaultStatusD7a 0 "No fault" 1 "Diff Temporarily open" 2 "Diff failed open" 3 "Diff failed closed" ;
VAL_ 385 CDiffCommonCauseFaultD7a 0 "No Fault" 1 "A common cause fault is detected" 2 "Clutch Open due to a common cause fault" 3 "Reserved" ;
VAL_ 385 CDiffDogLockFaultStatsD7a 0 "No Fault" 1 "Fault" ;
VAL_ 385 CDiffDogLockStatusD7a 0 "Init" 1 "Locked" 2 "Unlocked" 3 "Shift in Progress/Fault" ;
VAL_ 385 CDiffHydraulicSysStatsD7a 0 "No Fault" 1 "Venting" 2 "Vent 1 Required" 3 "Vent 2 Required" 4 "Fault" 5 "Unused5" 6 "Unused6" 7 "Unused7" ;
VAL_ 385 CDiffLockingTorqActD7a 255 "Error Marker" ;
VAL_ 385 CDiffRangeActualD7a 0 "Low range" 1 "Neutral/Fault" 2 "High range" 3 "Range change in process" ;
VAL_ 385 CDiffRangeFaultStatusD7a 0 "No fault" 1 "Range change not possible" 2 "Range not calibrated - production or service fault" 3 "Undefined range - position unknown due to fault" ;
VAL_ 385 CDiffRngChngInhibitD7a 0 "Initialising" 1 "Speed too High" 2 "Transmission not in N" 3 "Shifter not Locked" 4 "Voltage out of range" 5 "Temperature out of Range" 6 "Communications Fault" 7 "Range Change not Possible" 8 "No Inhibit" 9 "Reserved9" 10 "Reserved10" 11 "Reserved11" 12 "Reserved12" 13 "Reserved13" 14 "Reserved14" 15 "Reserved15" ;
VAL_ 385 CDiffSuspectedFaultD7a 0 "Normal" 1 "A fault suspected" ;
VAL_ 824 REM2ndRowCntrMoveReq 0 "No Movement Request (Default)" 1 "Deploy Request" 2 "Stow Request" 3 "Stop Movement Request" ;
VAL_ 824 REM2ndRowLeftMoveReq 0 "No Movement Request (Default)" 1 "Fold Request" 2 "Unfold Request" 3 "Stop Movement Request" ;
VAL_ 824 REM2ndRowRightMoveReq 0 "No Movement Request (Default)" 1 "Fold Request" 2 "Unfold Request" 3 "Stop Movement Request" ;
VAL_ 824 RemRDrvFoldReq2ndRow 0 "No Movement Request" 1 "Fold Request" 2 "Unfold Request" 3 "Stop Movement Request" ;
VAL_ 824 RemRDrvFoldReq3rdRow 0 "No Movement Request" 1 "Fold Request" 2 "Unfold Request" 3 "Stop Movement Request" ;
VAL_ 824 RemRPasFoldReq1stRow 0 "No Movement Request" 1 "Fold Request" 2 "Unfold Request" 3 "Stop Movement Request" ;
VAL_ 824 RemRPasFoldReq2ndRow 0 "No Movement Request" 1 "Fold Request" 2 "Unfold Request" 3 "Stop Movement Request" ;
VAL_ 824 RemRPasFoldReq3rdRow 0 "No Movement Request" 1 "Fold Request" 2 "Unfold Request" 3 "Stop Movement Request" ;
VAL_ 824 REMSkiHatchReq 0 "Default" 1 "Open Request" ;
VAL_ 80 KeepNetInAfterRunTCM 0 "ECU Does not require the Network" 1 "ECU Requires Network Communication" ;
VAL_ 80 ReAlignToNeutral 0 "Not Used1" 1 "Initial Value - No action" 2 "Realign to Neutral" 3 "Not Used2" ;
VAL_ 80 ReAlignToPark 0 "Not Used" 1 "Initial Value - No action" 2 "Realign to Park" 3 "Not Used" ;
VAL_ 80 TCMLockETSReq 0 "initialisation / fault /Lock" 1 "No Lock Request" 2 "Lock Request" 3 "Fault / Lock" ;
VAL_ 80 TCMLockGSMReq 0 "Initial Value" 1 "No Speed Lock" 2 "Speed Lock Request" 15 "Fault" ;
VAL_ 80 TCMLockGSMReqComp 0 "Fault" 13 "Speed Lock Request" 14 "No Speed Lock" 15 "Initial Value " ;
VAL_ 80 TCMParkReqAck 0 "Initial Value and Value for Position D, R and N." 1 "TCM Park Position Confirmed." 2 "TCM Processing Shift Req into Park" 3 "Fault Condition" ;
VAL_ 80 TCMStartEnable 0 "Transmisson is not in P or N (SbW - TCM does not allow start)" 1 " Transmission is in Neutral, SbW GSM is not in a driving gear an" 2 "Transmission is in Park or SbW EPRC pulled and SbW GSM is not i" 3 "To be interpreted as fault" ;
VAL_ 80 TCMText 0 "ok" 1 "Gearbox Fault" 2 "Gearbox overheating" 3 "Reselect for gear engagement" 4 "Launch Control Ready" 5 "Launch Control Active" 6 "Gearbox Overheating Recommend Low range is selected" 7 "Gearbox overheating. stop safely. Select Low Range" 8 "Dynamic Launch Not Available" 9 "Limited Gears available. Drive with Caution. Service Repair required" 10 "Gearbox Fault. Stop IMMEDIATELY . Vehicle Recovery required" 11 "Manual Shift disabled" 12 "Gearbox Fault. Stop safely. Vehicle Recovery required" 13 "Gearbox Fault. Service Repair required. Limited range available" 14 "Vehicle System fault. Gear Shifting affected. Service Repair required" 15 "Reserved" ;
VAL_ 80 TransTICStatus 0 "TIC Standby" 1 "TIC Active" 2 "TIC Not Active/Deactivating" 3 "TIC Fault" ;
SIG_GROUP_ 414 KVM_P_AUX 1 : EncryptionRollingCode KVDecryptedMsg2 PECentralLockCmd2 PELockButtonReq2 PKeyId2 ProvUnlockDriverSide ProvUnlockPassSide;
SIG_GROUP_ 1386 LPDM_NM56A 1 : NMMessageLPDM;
SIG_GROUP_ 97 ClutchPedalGrp2 1 : ClutchPedalAnalogPos ClutchPedalAnalogPosQF ClutchPedalPressed ClutchPedalSwitch;
SIG_GROUP_ 1288 RFA_NM508LS 1 : NMmessageKVM;
SIG_GROUP_ 480 RGTM_A 1 : UpperTailgateCloseStat UpperTailgateOpenStat;
SIG_GROUP_ 611 RGTMB_A 1 : LwrTailgateCloseStat LwrTailgateOpenStat;
SIG_GROUP_ 1327 RPDM_NM52F 1 : NMMessageRPDM;
SIG_GROUP_ 1344 TBM_NM540 1 : NMmessageTBM;
SIG_GROUP_ 1613 TEST_ResponseKVM 1 : TESTResponseKVM;
SIG_GROUP_ 1868 TST_PhysicalRespDSM 1 : TesterPhysicalResDSM;
SIG_GROUP_ 1935 TST_PhysicalRespFTCM 1 : TesterPhysicalResFTCM;
